VERSION ""

NS_ :

BS_:

BU_: Bat1 OpticalSensor EMUS_BMS SCIMO_PE TelemetryNode Master SensorF SensorR BrakeF BrakeR PDU HVCU HVTU TestBench MDB1 MDB2 MDB3 MDB4 MDB5 MDB6 Track CLU

BO_ 57 CLU_TX_ActionRequest: 5 CLU
 SG_ CLU_TX_TargetAirGap : 8|32@1+ (1,0) [0|4294967295] "" Vector__XXX
 SG_ CLU_TX_ActionRequest : 0|8@1+ (1,0) [0|255] "" Vector__XXX

BO_ 564 CLU_RX_ActionRequest: 1 SensorF
 SG_ CLU_RX_ActionRequest : 0|8@1+ (1,0) [0|255] ""  SensorF

BO_ 2165346838 BMS44_2_Frame: 8 Vector__XXX
 SG_ BMS44_2_FramePayload : 0|64@1+ (1,0) [0|0] ""  SensorF

BO_ 1792 CLU_RX_StatusLedControll: 1 SensorF
 SG_ CLU_RX_ErrorStatus : 0|1@1+ (1,0) [0|1] ""  CLU

BO_ 592 CLU_TX_LevitationState: 1 CLU
 SG_ CLU_LevitationState : 0|8@1+ (1,0) [0|255] ""  SensorF

BO_ 768 CLU_TX_CoolingState: 1 Vector__XXX
 SG_ CLU_RequiresCooling : 0|1@1+ (1,0) [0|1] ""  SensorF

BO_ 274 MDB3_RX_TargetAirGap: 4 CLU
 SG_ MDB3_TargetAirGap : 0|32@1- (0.0001,0) [-214748.3648|214748.3647] "mm" Vector__XXX

BO_ 295 MDB6_RX_TargetAirGap: 4 CLU
 SG_ MDB6_TargetAirGap : 0|32@1- (0.0001,0) [-214748.3648|214748.3647] "mm" Vector__XXX

BO_ 297 MDB6_TX_Temperature: 4 Vector__XXX
 SG_ MDB6_Temperature : 0|32@1- (0.0001,0) [-214748.3648|214748.3647] "C"  CLU

BO_ 294 MDB6_TX_AirGap: 4 Vector__XXX
 SG_ MDB6_AirGap : 0|32@1- (0.0001,0) [-214748.3648|214748.3647] "mm"  CLU

BO_ 293 MDB6_TX_State: 1 MDB6
 SG_ MDB6_State : 0|8@1+ (1,0) [0|255] ""  CLU

BO_ 292 MDB5_TX_Temperature: 4 Vector__XXX
 SG_ MDB5_Temperature : 0|32@1- (0.0001,0) [-214748.3648|214748.3647] "C"  CLU

BO_ 290 MDB5_RX_TargetAirGap: 4 CLU
 SG_ MDB5_TargetAirGap : 0|32@1- (0.0001,0) [-214748.3648|214748.3647] "mm" Vector__XXX

BO_ 289 MDB5_TX_AirGap: 4 Vector__XXX
 SG_ MDB5_AirGap : 0|32@1- (0.0001,0) [-214748.3648|214748.3647] "mm"  CLU

BO_ 288 MDB5_TX_State: 1 MDB5
 SG_ MDB5_State : 0|8@1+ (1,0) [0|255] ""  CLU

BO_ 281 MDB4_TX_Temperature: 4 Vector__XXX
 SG_ MDB4_Temperature : 0|32@1- (0.0001,0) [-214748.3648|214748.3647] "C"  CLU

BO_ 279 MDB4_RX_TargetAirGap: 4 CLU
 SG_ MDB4_TargetAirGap : 0|32@1- (0.0001,0) [-214748.3648|214748.3647] "C" Vector__XXX

BO_ 278 MDB4_TX_AirGap: 4 Vector__XXX
 SG_ MDB4_AirGap : 0|32@1- (0.0001,0) [-214748.3648|214748.3647] "mm"  CLU

BO_ 277 MDB4_TX_State: 1 MDB4
 SG_ MDB4_State : 0|8@1+ (1,0) [0|255] ""  CLU

BO_ 276 MDB3_TX_Temperature: 4 Vector__XXX
 SG_ MDB3_Temperature : 0|32@1- (0.0001,0) [-214748.3648|214748.3647] "C"  CLU

BO_ 273 MDB3_TX_AirGap: 4 Vector__XXX
 SG_ MDB3_AirGap : 0|32@1- (0.0001,0) [-214748.3648|214748.3647] "mm"  CLU

BO_ 272 MDB3_TX_State: 1 MDB3
 SG_ MDB3_State : 0|8@1+ (1,0) [0|255] ""  CLU

BO_ 265 MDB2_TX_Temperature: 4 Vector__XXX
 SG_ MDB2_Temperature : 0|32@1- (0.0001,0) [-214748.3648|214748.3647] "C"  CLU

BO_ 263 MDB2_RX_TargetAirGap: 4 CLU
 SG_ MDB2_TargetAirGap : 0|32@1- (0.0001,0) [-214748.3648|214748.3647] "mm" Vector__XXX

BO_ 262 MDB2_TX_AirGap: 4 Vector__XXX
 SG_ MDB2_AirGap : 0|32@1- (0.0001,0) [-214748.3648|214748.3647] "mm"  CLU

BO_ 261 MDB2_TX_State: 1 MDB2
 SG_ MDB2_State : 0|8@1+ (1,0) [0|255] ""  CLU

BO_ 258 MDB1_RX_TargetAirGap: 4 CLU
 SG_ MDB1_TargetAirGap : 0|32@1- (0.0001,0) [0|0] "mm" Vector__XXX

BO_ 260 MDB1_TX_Temperature: 4 MDB3
 SG_ MDB1_Temperature : 0|32@1- (0.0001,0) [-214748.3648|214748.3647] "C"  CLU,SensorF

BO_ 257 MDB1_TX_AirGap: 4 MDB3
 SG_ MDB1_AirGap : 0|32@1- (0.0001,0) [-214748.3648|214748.3647] "mm"  CLU

BO_ 1041 BrakeF_TX_PressureCooling: 2 BrakeF
 SG_ BrakeF_TX_Pressure_Reservoir : 0|12@1+ (0.005,-2) [-2|18.475] "bar"  SensorF

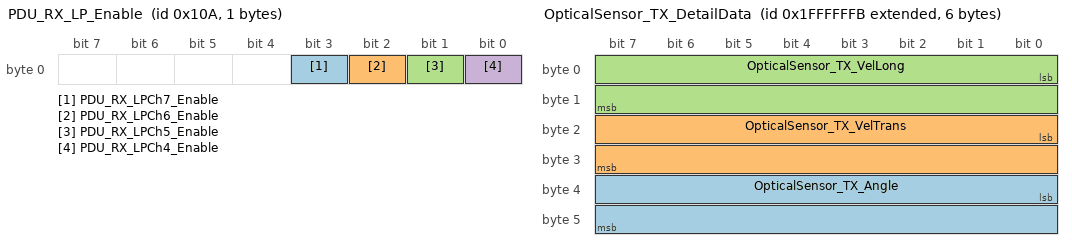
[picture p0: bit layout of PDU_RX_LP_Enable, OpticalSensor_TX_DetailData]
BO_ 266 PDU_RX_LP_Enable: 1 PDU
 SG_ PDU_RX_LPCh7_Enable : 3|1@1+ (1,0) [0|1] ""  PDU,SensorF
 SG_ PDU_RX_LPCh6_Enable : 2|1@1+ (1,0) [0|1] ""  PDU,SensorF
 SG_ PDU_RX_LPCh5_Enable : 1|1@1+ (1,0) [0|1] ""  PDU,SensorF
 SG_ PDU_RX_LPCh4_Enable : 0|1@1+ (1,0) [0|1] ""  PDU,SensorF

BO_ 2148592864 BMS44_1_Frame: 8 Bat1
 SG_ BMS44_1_FramePayload : 0|64@1+ (1,0) [0|0] ""  SensorF

BO_ 1 Track_TX_Respond: 1 Track
 SG_ Track_TX_Response : 0|8@1+ (1,0) [0|255] ""  SensorF

BO_ 0 Track_RX_Controll: 1 SensorF
 SG_ Track_RX_Command : 0|8@1+ (1,0) [0|255] "" Vector__XXX

BO_ 512 TEST_GROUND_STATION_CONTROLL: 1 Vector__XXX
 SG_ TEST_GROUND_STATION_COMMAND : 0|8@1+ (1,0) [0|255] ""  SensorF

BO_ 256 MDB1_TX_State: 1 MDB1
 SG_ MDB1_State : 0|8@1+ (1,0) [0|255] ""  CLU,SensorF

BO_ 450 SensorR_RX_POD1: 8 Vector__XXX

BO_ 2684354555 OpticalSensor_TX_DetailData: 6 OpticalSensor
 SG_ OpticalSensor_TX_Angle : 32|16@1- (0.01,0) [-45|45] "ï¿½" Vector__XXX
 SG_ OpticalSensor_TX_VelTrans : 16|16@1- (0.036,0) [-200|200] "km/h" Vector__XXX
 SG_ OpticalSensor_TX_VelLong : 0|16@1+ (0.036,0) [0|400] "km/h" Vector__XXX

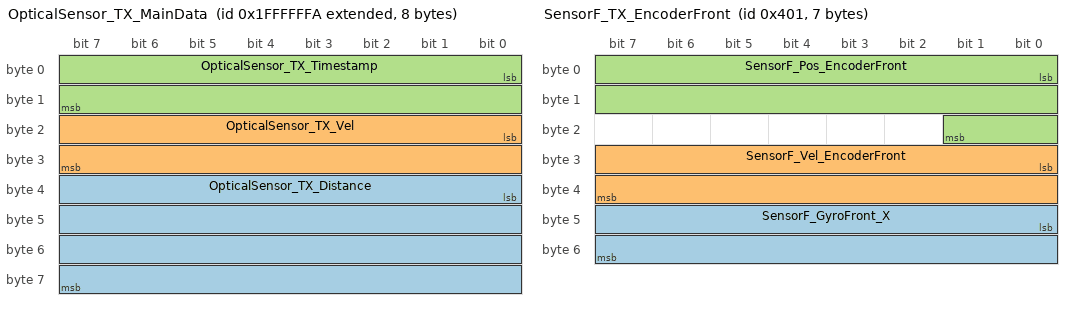
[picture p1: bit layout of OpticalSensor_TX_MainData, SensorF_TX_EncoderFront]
BO_ 2684354554 OpticalSensor_TX_MainData: 8 OpticalSensor
 SG_ OpticalSensor_TX_Distance : 32|32@1+ (0.001,0) [0|4294970] "m"  SensorF,SensorR
 SG_ OpticalSensor_TX_Vel : 16|16@1+ (0.036,0) [0|400] "km/h"  SensorF,SensorR
 SG_ OpticalSensor_TX_Timestamp : 0|16@1+ (1,0) [0|65535] ""  SensorF,SensorR

BO_ 2684354556 OpticalSensor_TX_Status: 8 OpticalSensor
 SG_ OpticalSensor_TX_VddOK : 62|1@1+ (1,0) [0|0] ""  SensorF
 SG_ OpticalSensor_TX_VeeOK : 61|1@1+ (1,0) [0|0] ""  SensorF
 SG_ OpticalSensor_TX_V33OK : 60|1@1+ (1,0) [0|0] ""  SensorF
 SG_ OpticalSensor_TX_V25OK : 59|1@1+ (1,0) [0|0] ""  SensorF
 SG_ OpticalSensor_TX_LEDStatus : 57|2@1+ (1,0) [0|0] ""  SensorF
 SG_ OpticalSensor_TX_LED_Cal : 56|1@1+ (1,0) [0|0] ""  SensorF
 SG_ OpticalSensor_TX_PowerOK : 55|1@1+ (1,0) [0|0] ""  SensorF
 SG_ OpticalSensor_TX_CurrentOK : 54|1@1+ (1,0) [0|0] ""  SensorF
 SG_ OpticalSensor_TX_CurrentLowHigh : 53|1@1+ (1,0) [0|0] ""  SensorF
 SG_ OpticalSensor_TX_OpticOK : 52|1@1+ (1,0) [0|0] ""  SensorF
 SG_ OpticalSensor_TX_TempOK : 51|1@1+ (1,0) [0|0] ""  SensorF
 SG_ OpticalSensor_TX_SensorOK : 50|1@1+ (1,0) [0|0] ""  SensorF
 SG_ OpticalSensor_TX_SelfTest : 49|1@1+ (1,0) [0|0] ""  SensorF
 SG_ OpticalSensor_TX_STST : 48|1@1+ (1,0) [0|0] ""  SensorF
 SG_ OpticalSensor_TX_LEDCurrent : 40|8@1+ (0.01,0) [0|2.55] "A"  SensorF
 SG_ OpticalSensor_TX_Temp : 32|8@1- (1,0) [-128|127] "ï¿½C"  SensorF
 SG_ OpticalSensor_TX_SensorNo : 24|8@1+ (1,0) [0|0] ""  SensorF
 SG_ OpticalSensor_TX_SerialNo : 0|24@1+ (1,0) [0|0] ""  SensorF

BO_ 2 CANzero_NMT: 4 Master
 SG_ CANzero_NMT_Node : 16|16@1+ (1,0) [0|63] ""  SensorF,SensorR,BrakeF,BrakeR,PDU,HVCU,HVTU,TelemetryNode,MDB1,MDB2,MDB3,MDB4,MDB5,MDB6,Track,CLU
 SG_ CANzero_NMT_State : 0|16@1+ (1,0) [0|0] ""  SensorF,SensorR,BrakeF,BrakeR,PDU,HVCU,HVTU,TelemetryNode,MDB1,MDB2,MDB3,MDB4,MDB5,MDB6,Track,CLU

BO_ 122 CANzero_Sync: 0 Master

BO_ 123 CANzero_Timestamp: 0 Master

BO_ 129 SensorF_EMCY: 4 SensorF
 SG_ SensorF_E14_fiducialHighOffset : 26|1@1+ (1,0) [0|0] ""  Master,TelemetryNode
 SG_ SensorF_E13_encoderSpeedError : 25|1@1+ (1,0) [0|0] ""  Master,TelemetryNode
 SG_ SensorF_E12_encoderError : 24|1@1+ (1,0) [0|0] ""  Master,TelemetryNode
 SG_ SensorF_E10_TelemEmergency : 22|1@1+ (1,0) [0|0] ""  Master,TelemetryNode
 SG_ SensorF_E9_SWError : 21|1@1+ (1,0) [0|0] ""  Master,TelemetryNode
 SG_ SensorF_E8_NodeErrorFlag : 20|1@1+ (1,0) [0|0] ""  Master,TelemetryNode
 SG_ SensorF_E7_TelemetryTimeout : 19|1@1+ (1,0) [0|0] ""  Master,TelemetryNode
 SG_ SensorF_E6_SensorRTimeout : 18|1@1+ (1,0) [0|0] ""  Master,TelemetryNode
 SG_ SensorF_E5_HVCUTimeout : 17|1@1+ (1,0) [0|0] ""  Master,TelemetryNode
 SG_ SensorF_E4_PDUTimeout : 16|1@1+ (1,0) [0|0] ""  Master,TelemetryNode
 SG_ SensorF_E3_BrakeRTimeout : 15|1@1+ (1,0) [0|0] ""  Master,TelemetryNode
 SG_ SensorF_E2_BrakeFTimeout : 14|1@1+ (1,0) [0|0] ""  Master,TelemetryNode
 SG_ SensorF_E1_StateMTransitionE : 13|1@1+ (1,0) [0|0] ""  Master,TelemetryNode
 SG_ SensorF_E0_OtherError : 12|1@1+ (1,0) [0|0] ""  Master,TelemetryNode
 SG_ SensorF_W2_encoderOORWarning : 2|1@1+ (1,0) [0|0] ""  Master,TelemetryNode
 SG_ SensorF_W1_StateMTransitionW : 1|1@1+ (1,0) [0|0] ""  Master,TelemetryNode
 SG_ SensorF_W0_OtherWarning : 0|1@1+ (1,0) [0|0] ""  Master,TelemetryNode

BO_ 385 SensorF_TX_StatePod: 1 SensorF
 SG_ SensorF_TX_PodState : 0|8@1+ (1,0) [0|0] ""  CLU,Track,BrakeF,PDU

BO_ 449 SensorF_RX_PDO1: 0 Vector__XXX

BO_ 513 SensorF_TX_FSMTransitions: 4 SensorF
 SG_ SensorF_TX_PreopHVCUT : 24|1@1+ (1,0) [0|0] "" Vector__XXX
 SG_ SensorF_TX_PreopPDUT : 16|1@1+ (1,0) [0|0] "" Vector__XXX
 SG_ SensorF_TX_PreopBrakeRT : 15|1@1+ (1,0) [0|0] "" Vector__XXX
 SG_ SensorF_TX_PreopBrakeFT : 14|1@1+ (1,0) [0|0] "" Vector__XXX
 SG_ SensorF_TX_PreopSensorRT : 13|1@1+ (1,0) [0|0] "" Vector__XXX
 SG_ SensorF_TX_EnableSensorRT : 12|1@1+ (1,0) [0|0] "" Vector__XXX
 SG_ SensorF_TX_EnablePDUT : 11|1@1+ (1,0) [0|0] "" Vector__XXX
 SG_ SensorF_TX_EnableHVCUT : 10|1@1+ (1,0) [0|0] "" Vector__XXX
 SG_ SensorF_TX_EnableBrakeRT : 9|1@1+ (1,0) [0|0] "" Vector__XXX
 SG_ SensorF_TX_EnableBrakeFT : 8|1@1+ (1,0) [0|0] "" Vector__XXX
 SG_ SensorF_TX_SetHVTransition : 7|1@1+ (1,0) [0|0] "" Vector__XXX
 SG_ SensorF_TX_PreopTransition : 6|1@1+ (1,0) [0|0] "" Vector__XXX
 SG_ SensorF_TX_LaunchStartTransition : 5|1@1+ (1,0) [0|0] "" Vector__XXX
 SG_ SensorF_TX_LaunchSetupTransition : 4|1@1+ (1,0) [0|0] "" Vector__XXX
 SG_ SensorF_TX_HWEnableTransition : 3|1@1+ (1,0) [0|0] "" Vector__XXX
 SG_ SensorF_TX_ErrorResetTransition : 2|1@1+ (1,0) [0|0] "" Vector__XXX
 SG_ SensorF_TX_EnableTransition : 1|1@1+ (1,0) [0|0] "" Vector__XXX
 SG_ SensorF_TX_BrakesTransition : 0|1@1+ (1,0) [0|0] "" Vector__XXX

BO_ 577 SensorF_RX_PDO2: 0 Vector__XXX

BO_ 641 SensorF_TX_PDO3: 0 SensorF

BO_ 705 SensorF_RX_PDO3: 0 Vector__XXX

BO_ 769 SensorF_TX_PDO4: 0 SensorF

BO_ 833 SensorF_RX_PDO4: 0 Vector__XXX

BO_ 897 SensorF_TX_PDO5: 0 SensorF

BO_ 961 SensorF_TX_PDO6: 0 SensorF

BO_ 1025 SensorF_TX_EncoderFront: 7 SensorF
 SG_ SensorF_GyroFront_X : 40|16@1- (0.017,0) [-557.056|557.039] "Â°/s"  SensorR
 SG_ SensorF_Vel_EncoderFront : 24|16@1- (0.002,0) [-65.536|65.534] "m/s"  SensorR
 SG_ SensorF_Pos_EncoderFront : 0|18@1- (0.005,0) [-655.36|655.355] "m"  SensorR

BO_ 1089 SensorF_TX_BMS: 2 SensorF
 SG_ SensorF_TX_BatteryTemp : 0|12@1+ (0.05,-30) [-30|174.75] "C"  PDU

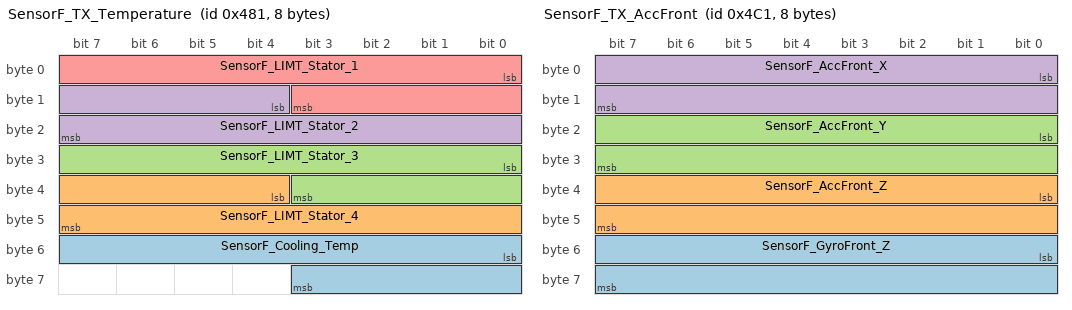
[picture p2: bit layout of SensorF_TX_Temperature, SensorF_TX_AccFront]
BO_ 1153 SensorF_TX_Temperature: 8 SensorF
 SG_ SensorF_Cooling_Temp : 48|12@1+ (0.05,-30) [-30|174.75] "C"  PDU
 SG_ SensorF_LIMT_Stator_4 : 36|12@1+ (0.075,-20) [-20|287.125] "ï¿½C" Vector__XXX
 SG_ SensorF_LIMT_Stator_3 : 24|12@1+ (0.075,-20) [-20|287.125] "ï¿½C" Vector__XXX
 SG_ SensorF_LIMT_Stator_2 : 12|12@1+ (0.075,-20) [-20|287.125] "ï¿½C" Vector__XXX
 SG_ SensorF_LIMT_Stator_1 : 0|12@1+ (0.075,-20) [-20|287.125] "ï¿½C" Vector__XXX

BO_ 1217 SensorF_TX_AccFront: 8 SensorF
 SG_ SensorF_GyroFront_Z : 48|16@1- (0.017,0) [-557.056|557.039] "Â°/s"  SensorR
 SG_ SensorF_AccFront_Z : 32|16@1- (0.00125,0) [-40.96|40.95875] "m/s^2"  SensorR
 SG_ SensorF_AccFront_Y : 16|16@1- (0.00125,0) [-40.96|40.95875] "m/s^2"  SensorR
 SG_ SensorF_AccFront_X : 0|16@1- (0.00125,0) [-40.96|40.95875] "m/s^2"  SensorR

BO_ 1281 SensorF_TX_PDO11: 0 SensorF

BO_ 1345 SensorF_TX_PDO12: 0 SensorF

BO_ 1409 SensorF_SDO_Resp: 8 SensorF
 SG_ SensorF_OD_TitanCell12Voltage m785 : 16|16@1+ (0.001,0) [0|65.535] "V"  TelemetryNode
 SG_ SensorF_OD_TitanCell11Voltage m784 : 16|16@1+ (0.001,0) [0|65.535] "V"  TelemetryNode
 SG_ SensorF_OD_TitanCell10Voltage m783 : 16|16@1+ (0.001,0) [0|65.535] "V"  TelemetryNode
 SG_ SensorF_OD_TitanCell9Voltage m782 : 16|16@1+ (0.001,0) [0|65.535] "V"  TelemetryNode
 SG_ SensorF_OD_TitanCell8Voltage m781 : 16|16@1+ (0.001,0) [0|65.535] "V"  TelemetryNode
 SG_ SensorF_OD_TitanCell7Voltage m780 : 16|16@1+ (0.001,0) [0|65.535] "V"  TelemetryNode
 SG_ SensorF_OD_TitanCell6Voltage m779 : 16|16@1+ (0.001,0) [0|65.535] "V"  TelemetryNode
 SG_ SensorF_OD_TitanCell5Voltage m778 : 16|16@1+ (0.001,0) [0|65.535] "V"  TelemetryNode
 SG_ SensorF_OD_TitanCell4Voltage m777 : 16|16@1+ (0.001,0) [0|65.535] "V"  TelemetryNode
 SG_ SensorF_OD_TitanCell3Voltage m776 : 16|16@1+ (0.001,0) [0|65.535] "V"  TelemetryNode
 SG_ SensorF_OD_TitanCell2Voltage m775 : 16|16@1+ (0.001,0) [0|65.535] "V"  TelemetryNode
 SG_ SensorF_OD_TitanCell1Voltage m774 : 16|16@1+ (0.001,0) [0|65.535] "V"  TelemetryNode
 SG_ SensorF_OD_TitanHealthStatus m773 : 16|16@1+ (1,0) [0|65535] "%"  TelemetryNode
 SG_ SensorF_OD_TitanLifeCycle m772 : 16|16@1+ (1,0) [0|65535] ""  TelemetryNode
 SG_ SensorF_OD_TitanRemainingCapacit m771 : 16|16@1+ (1,0) [0|65535] "%"  TelemetryNode
 SG_ SensorF_OD_TitanCurrent m770 : 16|16@1+ (0.01,-100) [-100|555.35] "A"  TelemetryNode
 SG_ SensorF_OD_TitanVoltage m769 : 16|16@1+ (0.001,0) [0|65.535] "V"  TelemetryNode
 SG_ SensorF_OD_TitanTemperature m768 : 16|16@1+ (0.01,0) [0|655.35] "C°"  TelemetryNode
 SG_ SensorF_OD_HyperionCell12Voltage m529 : 16|16@1+ (0.001,0) [0|65.535] "V"  TelemetryNode
 SG_ SensorF_OD_HyperionCell11Voltage m528 : 16|16@1+ (0.001,0) [0|65.535] "V"  TelemetryNode
 SG_ SensorF_OD_HyperionCell10Voltage m527 : 16|16@1+ (0.001,0) [0|65.535] "V"  TelemetryNode
 SG_ SensorF_OD_HyperionCell9Voltage m526 : 16|16@1+ (0.001,0) [0|65.535] "V"  TelemetryNode
 SG_ SensorF_OD_HyperionCell8Voltage m525 : 16|16@1+ (0.001,0) [0|65.535] "V"  TelemetryNode
 SG_ SensorF_OD_HyperionCell7Voltage m524 : 16|16@1+ (0.001,0) [0|65.535] "V"  TelemetryNode
 SG_ SensorF_OD_HyperionCell6Voltage m523 : 16|16@1+ (0.001,0) [0|65.535] "V"  TelemetryNode
 SG_ SensorF_OD_HyperionCell5Voltage m522 : 16|16@1+ (0.001,0) [0|65.535] "V"  TelemetryNode
 SG_ SensorF_OD_HyperionCell4Voltage m521 : 16|16@1+ (0.001,0) [0|65.535] "V"  TelemetryNode
 SG_ SensorF_OD_HyperionCell3Voltage m520 : 16|16@1+ (0.001,0) [0|65.535] "V"  TelemetryNode
 SG_ SensorF_OD_HyperionCell2Voltage m519 : 16|16@1+ (0.001,0) [0|65.535] "V"  TelemetryNode
 SG_ SensorF_OD_HyperionCell1Voltage m518 : 16|16@1+ (0.01,0) [0|655.35] "V"  TelemetryNode
 SG_ SensorF_OD_HyperionHealthStatus m517 : 16|16@1+ (1,0) [0|65535] "%"  TelemetryNode
 SG_ SensorF_OD_HyperionLifeCycle m516 : 16|16@1+ (1,0) [0|65535] ""  TelemetryNode
 SG_ SensorF_OD_HyperionRemainingCapa m515 : 16|16@1+ (0.01,0) [0|655.35] "%"  TelemetryNode
 SG_ SensorF_OD_HyperionCurrent m514 : 16|16@1+ (0.01,-100) [-100|555.35] "A"  TelemetryNode
 SG_ SensorF_OD_HyperionVoltage m513 : 16|16@1+ (0.001,0) [0|65.535] "V"  TelemetryNode
 SG_ SensorF_OD_HyperionTemperature m512 : 16|16@1+ (0.01,0) [0|655.35] "C°"  TelemetryNode
 SG_ SensorF_OD_SetReset m2320 : 16|8@1+ (1,0) [0|255] ""  TelemetryNode
 SG_ SensorF_OD_Velocity m3329 : 16|16@1+ (0.01,-100) [-100|555.35] ""  TelemetryNode
 SG_ SensorF_OD_Position m3328 : 16|16@1+ (0.01,-100) [-100|555.35] ""  TelemetryNode
 SG_ SensorF_OD_StripeCount m3072 : 16|16@1+ (1,0) [0|65535] ""  TelemetryNode
 SG_ SensorF_OD_MdbState m2832 : 16|8@1+ (1,0) [0|255] ""  TelemetryNode
 SG_ SensorF_OD_Magnet_6_Temperature m2824 : 16|16@1+ (0.01,-100) [-100|555.35] ""  TelemetryNode
 SG_ SensorF_OD_Magnet_5_Temperature m2823 : 16|16@1+ (0.01,-100) [-100|555.35] ""  TelemetryNode
 SG_ SensorF_OD_Magnet_4_Temperature m2822 : 16|16@1+ (0.01,-100) [-100|555.35] ""  TelemetryNode
 SG_ SensorF_OD_Magnet_3_Temperature m2821 : 16|16@1+ (0.01,-100) [-100|555.35] ""  TelemetryNode
 SG_ SensorF_OD_Magnet_2_Temperature m2820 : 16|16@1+ (0.01,-100) [-100|555.35] ""  TelemetryNode
 SG_ SensorF_OD_Magnet_1_Temperature m2818 : 16|16@1+ (0.01,-100) [-100|555.35] ""  TelemetryNode
 SG_ SensorF_OD_ReservoirTemperature m2817 : 16|16@1+ (0.01,-100) [-100|555.35] ""  TelemetryNode
 SG_ SensorF_OD_CoolingPressure m2816 : 16|16@1+ (0.01,-100) [-100|555.35] ""  TelemetryNode
 SG_ SensorF_OD_IMU_GyroZ m2611 : 16|16@1+ (0.01,-100) [-100|555.35] ""  TelemetryNode
 SG_ SensorF_OD_IMU_GyroY m2610 : 16|16@1+ (0.01,-100) [-100|555.35] ""  TelemetryNode
 SG_ SensorF_OD_IMU_GyroX m2609 : 16|16@1+ (0.01,-100) [-100|555.35] ""  TelemetryNode
 SG_ SensorF_OD_IMU_AccelZ m2608 : 16|16@1+ (0.01,-100) [-100|555.35] ""  TelemetryNode
 SG_ SensorF_OD_IMU_AccelY m2601 : 16|16@1+ (0.01,-100) [-100|555.35] ""  TelemetryNode
 SG_ SensorF_OD_IMU_AccelX m2600 : 16|16@1+ (0.01,-100) [-100|555.35] ""  TelemetryNode
 SG_ SensorF_OD_IMU3_Temperature m2599 : 16|16@1+ (0.01,-100) [-100|555.35] ""  TelemetryNode
 SG_ SensorF_OD_IMU2_Temperature m2598 : 16|16@1+ (0.01,-100) [-100|555.35] ""  TelemetryNode
 SG_ SensorF_OD_IMU1_Temperature m2597 : 16|16@1+ (0.01,-100) [-100|555.35] ""  TelemetryNode
 SG_ SensorF_OD_IMU_number m2592 : 16|8@1+ (1,0) [0|255] ""  TelemetryNode
 SG_ SensorF_OD_EncoderResetPosition m2309 : 16|8@1+ (1,0) [0|255] ""  TelemetryNode
 SG_ SensorF_OD_EncoderWheelDiameter m2308 : 16|16@1+ (0.005,0) [1|300] "mm"  TelemetryNode
 SG_ SensorF_OD_HVBatteryMode m2307 : 16|8@1+ (1,0) [0|255] ""  TelemetryNode
 SG_ SensorF_OD_StateMachineActivate m2306 : 16|8@1+ (1,0) [0|255] ""  TelemetryNode
 SG_ SensorF_OD_StateMachineInterval m2305 : 16|8@1+ (1,0) [5|100] "ms"  TelemetryNode
 SG_ SensorF_OD_TelemetryCommands m2304 : 16|8@1+ (1,0) [0|255] ""  TelemetryNode
 SG_ SensorF_OD_samplingInterval m2048 : 16|16@1+ (0.01,0) [0.01|100] "ms"  TelemetryNode
 SG_ SensorF_OD_CAN2_DelayedTxMessage m1129 : 16|24@1+ (1,0) [0|16777215] ""  TelemetryNode
 SG_ SensorF_OD_CAN2_ErrorStatus m1128 : 16|8@1+ (1,0) [0|255] ""  TelemetryNode
 SG_ SensorF_OD_CAN2_DiscardedTxMessa m1127 : 16|24@1+ (1,0) [0|16777215] ""  TelemetryNode
 SG_ SensorF_OD_CAN2_Status m1126 : 16|8@1+ (1,0) [0|255] ""  TelemetryNode
 SG_ SensorF_OD_CAN2_Baudrate m1124 : 16|16@1+ (1,0) [125|1000] "kbps"  TelemetryNode
 SG_ SensorF_OD_CAN2_autoErrorReset m1123 : 16|8@1+ (1,0) [0|255] ""  TelemetryNode
 SG_ SensorF_OD_CAN2_lastErrorCode m1122 : 16|32@1+ (1,0) [0|4294967295] ""  TelemetryNode
 SG_ SensorF_OD_CAN2_RxErrCnt m1121 : 16|8@1+ (1,0) [0|255] ""  TelemetryNode
 SG_ SensorF_OD_CAN2_TxErrCnt m1120 : 16|8@1+ (1,0) [0|255] ""  TelemetryNode
 SG_ SensorF_OD_CAN1_DelayedTxMessage m1113 : 16|24@1+ (1,0) [0|16777215] ""  TelemetryNode
 SG_ SensorF_OD_CAN1_ErrorStatus m1112 : 16|8@1+ (1,0) [0|255] ""  TelemetryNode
 SG_ SensorF_OD_CAN1_DiscardedTxMessa m1111 : 16|24@1+ (1,0) [0|16777215] ""  TelemetryNode
 SG_ SensorF_OD_CAN1_Status m1110 : 16|8@1+ (1,0) [0|255] ""  TelemetryNode
 SG_ SensorF_OD_CAN1_Baudrate m1108 : 16|16@1+ (1,0) [125|1000] "kbps"  TelemetryNode
 SG_ SensorF_OD_CAN1_autoErrorReset m1107 : 16|8@1+ (1,0) [0|255] ""  TelemetryNode
 SG_ SensorF_OD_CAN1_lastErrorCode m1106 : 16|32@1+ (1,0) [0|4294967295] ""  TelemetryNode
 SG_ SensorF_OD_CAN1_RxErrCnt m1105 : 16|8@1+ (1,0) [0|255] ""  TelemetryNode
 SG_ SensorF_OD_CAN1_TxErrCnt m1104 : 16|8@1+ (1,0) [0|255] ""  TelemetryNode
 SG_ SensorF_OD_BuildTime m1073 : 16|24@1+ (1,0) [0|16777215] ""  TelemetryNode
 SG_ SensorF_OD_BuildDate m1072 : 16|32@1+ (1,0) [0|4294967295] ""  TelemetryNode
 SG_ SensorF_OD_ChipUID2 m1057 : 16|48@1+ (1,0) [0|281474976710655] ""  TelemetryNode
 SG_ SensorF_OD_ChipUID1 m1056 : 16|48@1+ (1,0) [0|281474976710655] ""  TelemetryNode
 SG_ SensorF_OD_SdcOut m1046 : 16|8@1+ (1,0) [0|255] ""  TelemetryNode
 SG_ SensorF_OD_SdcIn m1045 : 16|8@1+ (1,0) [0|255] ""  TelemetryNode
 SG_ SensorF_OD_runtime m1044 : 16|24@1+ (1,0) [0|16777215] "ms"  TelemetryNode
 SG_ SensorF_OD_InputVoltage m1043 : 16|16@1+ (0.001,0) [0|65.535] "V"  TelemetryNode
 SG_ SensorF_OD_BoardTemp m1042 : 16|16@1+ (0.01,-30) [-30|625.35] "°C"  TelemetryNode
 SG_ SensorF_OD_MemFree m1041 : 16|16@1+ (4,0) [0|262140] "bytes"  TelemetryNode
 SG_ SensorF_OD_CpuUsage m1040 : 16|8@1+ (0.5,0) [0|100] "%"  TelemetryNode
 SG_ SensorF_OD_OdEntrySendInterval m33 : 16|16@1+ (1,0) [0|65535] "ms"  TelemetryNode
 SG_ SensorF_OD_SendOdOnBootup m32 : 16|8@1+ (1,0) [0|255] ""  TelemetryNode
 SG_ SensorF_OD_HeartbeatInterval m16 : 16|16@1+ (1,0) [0|65535] "ms"  TelemetryNode
 SG_ SensorF_OD_DbcVersion m5 : 16|16@1+ (1,0) [0|65535] ""  TelemetryNode
 SG_ SensorF_OD_StackVersion m4 : 16|16@1+ (1,0) [0|65535] ""  TelemetryNode
 SG_ SensorF_OD_ProtocolVersion m3 : 16|16@1+ (1,0) [0|65535] ""  TelemetryNode
 SG_ SensorF_OD_NodeStatus m2 : 16|8@1+ (1,0) [0|255] ""  TelemetryNode
 SG_ SensorF_OD_NodeID m1 : 16|8@1+ (1,0) [0|255] ""  TelemetryNode
 SG_ SensorF_SDO_RespCode : 12|4@1+ (1,0) [0|0] ""  TelemetryNode
 SG_ SensorF_SDO_ID M : 0|12@1+ (1,0) [0|4095] ""  TelemetryNode

BO_ 1473 SensorF_SDO_Req_Up: 8 TelemetryNode
 SG_ SensorF_OD_TitanCell12Voltage m785 : 16|16@1+ (0.001,0) [0|65.535] "V"  SensorF
 SG_ SensorF_OD_TitanCell11Voltage m784 : 16|16@1+ (0.001,0) [0|65.535] "V"  SensorF
 SG_ SensorF_OD_TitanCell10Voltage m783 : 16|16@1+ (0.001,0) [0|65.535] "V"  SensorF
 SG_ SensorF_OD_TitanCell9Voltage m782 : 16|16@1+ (0.001,0) [0|65.535] "V"  SensorF
 SG_ SensorF_OD_TitanCell8Voltage m781 : 16|16@1+ (0.001,0) [0|65.535] "V"  SensorF
 SG_ SensorF_OD_TitanCell7Voltage m780 : 16|16@1+ (0.001,0) [0|65.535] "V"  SensorF
 SG_ SensorF_OD_TitanCell6Voltage m779 : 16|16@1+ (0.001,0) [0|65.535] "V"  SensorF
 SG_ SensorF_OD_TitanCell5Voltage m778 : 16|16@1+ (0.001,0) [0|65.535] "V"  SensorF
 SG_ SensorF_OD_TitanCell4Voltage m777 : 16|16@1+ (0.001,0) [0|65.535] "V"  SensorF
 SG_ SensorF_OD_TitanCell3Voltage m776 : 16|16@1+ (0.001,0) [0|65.535] "V"  SensorF
 SG_ SensorF_OD_TitanCell2Voltage m775 : 16|16@1+ (0.001,0) [0|65.535] "V"  SensorF
 SG_ SensorF_OD_TitanCell1Voltage m774 : 16|16@1+ (0.001,0) [0|65.535] "V"  SensorF
 SG_ SensorF_OD_TitanHealthStatus m773 : 16|16@1+ (1,0) [0|65535] "%"  SensorF
 SG_ SensorF_OD_TitanLifeCycle m772 : 16|16@1+ (1,0) [0|65535] ""  SensorF
 SG_ SensorF_OD_TitanRemainingCa_0000 m771 : 16|16@1+ (1,0) [0|65535] "%"  SensorF
 SG_ SensorF_OD_TitanCurrent m770 : 16|16@1+ (0.01,-100) [-100|555.35] "A"  SensorF
 SG_ SensorF_OD_TitanVoltage m769 : 16|16@1+ (0.001,0) [0|65.535] "V"  SensorF
 SG_ SensorF_OD_TitanTemperature m768 : 16|16@1+ (0.01,0) [0|655.35] "C°"  SensorF
 SG_ SensorF_OD_HyperionCell12Voltage m529 : 16|16@1+ (0.001,0) [0|65.535] "V"  SensorF
 SG_ SensorF_OD_HyperionCell11Voltage m528 : 16|16@1+ (0.001,0) [0|65.535] "V"  SensorF
 SG_ SensorF_OD_HyperionCell10Voltage m527 : 16|16@1+ (0.001,0) [0|65.535] "V"  SensorF
 SG_ SensorF_OD_HyperionCell9Voltage m526 : 16|16@1+ (0.001,0) [0|65.535] "V"  SensorF
 SG_ SensorF_OD_HyperionCell8Voltage m525 : 16|16@1+ (0.001,0) [0|65.535] "V"  SensorF
 SG_ SensorF_OD_HyperionCell7Voltage m524 : 16|16@1+ (0.001,0) [0|65.535] "V"  SensorF
 SG_ SensorF_OD_HyperionCell6Voltage m523 : 16|16@1+ (0.001,0) [0|65.535] "V"  SensorF
 SG_ SensorF_OD_HyperionCell5Voltage m522 : 16|16@1+ (0.001,0) [0|65.535] "V"  SensorF
 SG_ SensorF_OD_HyperionCell4Voltage m521 : 16|16@1+ (0.001,0) [0|65.535] "V"  SensorF
 SG_ SensorF_OD_HyperionCell3Voltage m520 : 16|16@1+ (0.001,0) [0|65.535] "V"  SensorF
 SG_ SensorF_OD_HyperionCell2Voltage m519 : 16|16@1+ (0.001,0) [0|65.535] "V"  SensorF
 SG_ SensorF_OD_HyperionCell1Voltage m518 : 16|16@1+ (0.01,0) [0|655.35] "V"  SensorF
 SG_ SensorF_OD_HyperionHealthStatus m517 : 16|16@1+ (1,0) [0|65535] "%"  SensorF
 SG_ SensorF_OD_HyperionLifeCycle m516 : 16|16@1+ (1,0) [0|65535] ""  SensorF
 SG_ SensorF_OD_HyperionRemainin_0000 m515 : 16|16@1+ (0.01,0) [0|655.35] "%"  SensorF
 SG_ SensorF_OD_HyperionCurrent m514 : 16|16@1+ (0.01,-100) [-100|555.35] "A"  SensorF
 SG_ SensorF_OD_HyperionVoltage m513 : 16|16@1+ (0.001,0) [0|65.535] "V"  SensorF
 SG_ SensorF_OD_HyperionTemperature m512 : 16|16@1+ (0.01,0) [0|655.35] "C°"  SensorF
 SG_ SensorF_OD_SetReset m2320 : 16|8@1+ (1,0) [0|255] ""  SensorF
 SG_ SensorF_OD_Velocity m3329 : 16|16@1+ (0.01,-100) [-100|555.35] ""  SensorF
 SG_ SensorF_OD_Position m3328 : 16|16@1+ (0.01,-100) [-100|555.35] ""  SensorF
 SG_ SensorF_OD_StripeCount m3072 : 16|16@1+ (1,0) [0|65535] ""  SensorF
 SG_ SensorF_OD_MdbState m2832 : 16|8@1+ (1,0) [0|255] ""  SensorF
 SG_ SensorF_OD_Magnet_6_Temperature m2824 : 16|16@1+ (0.01,-100) [-100|555.35] ""  SensorF
 SG_ SensorF_OD_Magnet_5_Temperature m2823 : 16|16@1+ (0.01,-100) [-100|555.35] ""  SensorF
 SG_ SensorF_OD_Magnet_4_Temperature m2822 : 16|16@1+ (0.01,-100) [-100|555.35] ""  SensorF
 SG_ SensorF_OD_Magnet_3_Temperature m2821 : 16|16@1+ (0.01,-100) [-100|555.35] ""  SensorF
 SG_ SensorF_OD_Magnet_2_Temperature m2820 : 16|16@1+ (0.01,-100) [-100|555.35] ""  SensorF
 SG_ SensorF_OD_Magnet_1_Temperature m2818 : 16|16@1+ (0.01,-100) [-100|555.35] ""  SensorF
 SG_ SensorF_OD_ReservoirTemperature m2817 : 16|16@1+ (0.01,-100) [-100|555.35] ""  SensorF
 SG_ SensorF_OD_CoolingPressure m2816 : 16|16@1+ (0.01,-100) [-100|555.35] ""  SensorF
 SG_ SensorF_OD_IMU_GyroZ m2611 : 16|16@1+ (0.01,-100) [-100|555.35] ""  SensorF
 SG_ SensorF_OD_IMU_GyroY m2610 : 16|16@1+ (0.01,-100) [-100|555.35] ""  SensorF
 SG_ SensorF_OD_IMU_GyroX m2609 : 16|16@1+ (0.01,-100) [-100|555.35] ""  SensorF
 SG_ SensorF_OD_IMU_AccelZ m2608 : 16|16@1+ (0.01,-100) [-100|555.35] ""  SensorF
 SG_ SensorF_OD_IMU_AccelY m2601 : 16|16@1+ (0.01,-100) [-100|555.35] ""  SensorF
 SG_ SensorF_OD_IMU_AccelX m2600 : 16|16@1+ (0.01,-100) [-100|555.35] ""  SensorF
 SG_ SensorF_OD_IMU3_Temperature m2599 : 16|16@1+ (0.01,-100) [-100|555.35] ""  SensorF
 SG_ SensorF_OD_IMU2_Temperature m2598 : 16|16@1+ (0.01,-100) [-100|555.35] ""  SensorF
 SG_ SensorF_OD_IMU1_Temperature m2597 : 16|16@1+ (0.01,-100) [-100|555.35] ""  SensorF
 SG_ SensorF_OD_IMU_number m2592 : 16|8@1+ (1,0) [0|255] ""  SensorF
 SG_ SensorF_OD_EncoderResetPosition m2309 : 16|8@1+ (1,0) [0|255] ""  SensorF
 SG_ SensorF_OD_EncoderWheelDiameter m2308 : 16|16@1+ (0.005,0) [1|300] "mm"  SensorF
 SG_ SensorF_OD_HVBatteryMode m2307 : 16|8@1+ (1,0) [0|255] ""  SensorF
 SG_ SensorF_OD_StateMachineActivate m2306 : 16|8@1+ (1,0) [0|255] ""  SensorF
 SG_ SensorF_OD_StateMachineInterval m2305 : 16|8@1+ (1,0) [5|100] "ms"  SensorF
 SG_ SensorF_OD_TelemetryCommands m2304 : 16|8@1+ (1,0) [0|255] ""  SensorF
 SG_ SensorF_OD_samplingInterval m2048 : 16|16@1+ (0.01,0) [0.01|100] "ms"  SensorF
 SG_ SensorF_OD_CAN2_DelayedTxMe_0000 m1129 : 16|24@1+ (1,0) [0|16777215] ""  SensorF
 SG_ SensorF_OD_CAN2_ErrorStatus m1128 : 16|8@1+ (1,0) [0|255] ""  SensorF
 SG_ SensorF_OD_CAN2_DiscardedTx_0000 m1127 : 16|24@1+ (1,0) [0|16777215] ""  SensorF
 SG_ SensorF_OD_CAN2_Status m1126 : 16|8@1+ (1,0) [0|255] ""  SensorF
 SG_ SensorF_OD_CAN2_Baudrate m1124 : 16|16@1+ (1,0) [125|1000] "kbps"  SensorF
 SG_ SensorF_OD_CAN2_autoErrorReset m1123 : 16|8@1+ (1,0) [0|255] ""  SensorF
 SG_ SensorF_OD_CAN2_lastErrorCode m1122 : 16|32@1+ (1,0) [0|4294967295] ""  SensorF
 SG_ SensorF_OD_CAN2_RxErrCnt m1121 : 16|8@1+ (1,0) [0|255] ""  SensorF
 SG_ SensorF_OD_CAN2_TxErrCnt m1120 : 16|8@1+ (1,0) [0|255] ""  SensorF
 SG_ SensorF_OD_CAN1_DelayedTxMe_0000 m1113 : 16|24@1+ (1,0) [0|16777215] ""  SensorF
 SG_ SensorF_OD_CAN1_ErrorStatus m1112 : 16|8@1+ (1,0) [0|255] ""  SensorF
 SG_ SensorF_OD_CAN1_DiscardedTx_0000 m1111 : 16|24@1+ (1,0) [0|16777215] ""  SensorF
 SG_ SensorF_OD_CAN1_Status m1110 : 16|8@1+ (1,0) [0|255] ""  SensorF
 SG_ SensorF_OD_CAN1_Baudrate m1108 : 16|16@1+ (1,0) [125|1000] "kbps"  SensorF
 SG_ SensorF_OD_CAN1_autoErrorReset m1107 : 16|8@1+ (1,0) [0|255] ""  SensorF
 SG_ SensorF_OD_CAN1_lastErrorCode m1106 : 16|32@1+ (1,0) [0|4294967295] ""  SensorF
 SG_ SensorF_OD_CAN1_RxErrCnt m1105 : 16|8@1+ (1,0) [0|255] ""  SensorF
 SG_ SensorF_OD_CAN1_TxErrCnt m1104 : 16|8@1+ (1,0) [0|255] ""  SensorF
 SG_ SensorF_OD_BuildTime m1073 : 16|24@1+ (1,0) [0|16777215] ""  SensorF
 SG_ SensorF_OD_BuildDate m1072 : 16|32@1+ (1,0) [0|4294967295] ""  SensorF
 SG_ SensorF_OD_ChipUID2 m1057 : 16|48@1+ (1,0) [0|281474976710655] ""  SensorF
 SG_ SensorF_OD_ChipUID1 m1056 : 16|48@1+ (1,0) [0|281474976710655] ""  SensorF
 SG_ SensorF_OD_SdcOut m1046 : 16|8@1+ (1,0) [0|255] ""  SensorF
 SG_ SensorF_OD_SdcIn m1045 : 16|8@1+ (1,0) [0|255] ""  SensorF
 SG_ SensorF_OD_runtime m1044 : 16|24@1+ (1,0) [0|16777215] "ms"  SensorF
 SG_ SensorF_OD_InputVoltage m1043 : 16|16@1+ (0.001,0) [0|65.535] "V"  SensorF
 SG_ SensorF_OD_BoardTemp m1042 : 16|16@1+ (0.01,-30) [-30|625.35] "°C"  SensorF
 SG_ SensorF_OD_MemFree m1041 : 16|16@1+ (4,0) [0|262140] "bytes"  SensorF
 SG_ SensorF_OD_CpuUsage m1040 : 16|8@1+ (0.5,0) [0|100] "%"  SensorF
 SG_ SensorF_OD_OdEntrySendInterval m33 : 16|16@1+ (1,0) [0|65535] "ms"  SensorF
 SG_ SensorF_OD_SendOdOnBootup m32 : 16|8@1+ (1,0) [0|255] ""  SensorF
 SG_ SensorF_OD_HeartbeatInterval m16 : 16|16@1+ (1,0) [0|65535] "ms"  SensorF
 SG_ SensorF_OD_DbcVersion m5 : 16|16@1+ (1,0) [0|65535] ""  SensorF
 SG_ SensorF_OD_StackVersion m4 : 16|16@1+ (1,0) [0|65535] ""  SensorF
 SG_ SensorF_OD_ProtocolVersion m3 : 16|16@1+ (1,0) [0|65535] ""  SensorF
 SG_ SensorF_OD_NodeStatus m2 : 16|8@1+ (1,0) [0|255] ""  SensorF
 SG_ SensorF_OD_NodeID m1 : 16|8@1+ (1,0) [0|255] ""  SensorF
 SG_ SensorF_SDO_ID M : 0|12@1+ (1,0) [0|4095] ""  SensorF

BO_ 1537 SensorF_SDO_Req_Down: 2 TelemetryNode
 SG_ SensorF_SDO_ID M : 0|12@1+ (1,0) [0|4095] ""  SensorF

BO_ 1793 SensorF_Heartbeat: 1 SensorF
 SG_ SensorF_NodeState : 0|8@1+ (1,0) [0|0] ""  SensorF,Master,TelemetryNode

BO_ 1857 SensorF_BTL_TX: 8 SensorF

BO_ 1921 SensorF_BTL_RX: 8 TelemetryNode

BO_ 130 SensorR_EMCY: 4 SensorR
 SG_ SensorR_E12_highLIMTemperature : 24|1@1+ (1,0) [0|0] ""  Master,TelemetryNode
 SG_ SensorR_E11_scimoPEerror101overc : 23|1@1+ (1,0) [0|0] ""  Master,TelemetryNode
 SG_ SensorR_E10_scimoPEerror103sumcu : 22|1@1+ (1,0) [0|0] ""  Master,TelemetryNode
 SG_ SensorR_E9_scimoPEerror102overcu : 21|1@1+ (1,0) [0|0] ""  Master,TelemetryNode
 SG_ SensorR_E8_scimoPEerror024motTem : 20|1@1+ (1,0) [0|0] ""  Master,TelemetryNode
 SG_ SensorR_E7_scimoPEerror020uZKmin : 19|1@1+ (1,0) [0|0] ""  Master,TelemetryNode
 SG_ SensorR_E6_scimoPEerror009Pulslo : 18|1@1+ (1,0) [0|0] ""  Master,TelemetryNode
 SG_ SensorR_E5_accEmergencyStop : 17|1@1+ (1,0) [0|0] ""  Master,TelemetryNode
 SG_ SensorR_E4_velEmergencyStop : 16|1@1+ (1,0) [0|0] ""  Master,TelemetryNode
 SG_ SensorR_E3_posEmergencyStop : 15|1@1+ (1,0) [0|0] ""  Master,TelemetryNode
 SG_ SensorR_E2_stripeEmergencyStop : 14|1@1+ (1,0) [0|0] ""  Master,TelemetryNode
 SG_ SensorR_E1_trajectoryError : 13|1@1+ (1,0) [0|0] ""  Master,TelemetryNode
 SG_ SensorR_E0_OtherError : 12|1@1+ (1,0) [0|0] ""  Master,TelemetryNode
 SG_ SensorR_W10_highLIMTemperature : 10|1@1+ (1,0) [0|0] ""  Master,TelemetryNode
 SG_ SensorR_W9_restrictingVelocity : 9|1@1+ (1,0) [0|0] ""  Master,TelemetryNode
 SG_ SensorR_W8_outOfLimModelBoundari : 8|1@1+ (1,0) [0|0] ""  Master,TelemetryNode
 SG_ SensorR_W7_highOscillations : 7|1@1+ (1,0) [0|0] ""  Master,TelemetryNode
 SG_ SensorR_W6_sciMoPEwarning104FETt : 6|1@1+ (1,0) [0|0] ""  Master,TelemetryNode
 SG_ SensorR_W5_sciMoPEwarning069CPUt : 5|1@1+ (1,0) [0|0] ""  Master,TelemetryNode
 SG_ SensorR_W4_stateEstimationAccWar : 4|1@1+ (1,0) [0|0] ""  Master,TelemetryNode
 SG_ SensorR_W3_stateEstimationPosWar : 3|1@1+ (1,0) [0|0] ""  Master,TelemetryNode
 SG_ SensorR_W2_stateEstimationVelWar : 2|1@1+ (1,0) [0|0] ""  Master,TelemetryNode
 SG_ SensorR_W1_stripeWarning : 1|1@1+ (1,0) [0|0] ""  Master,TelemetryNode
 SG_ SensorR_W0_OtherWarning : 0|1@1+ (1,0) [0|0] ""  Master,TelemetryNode

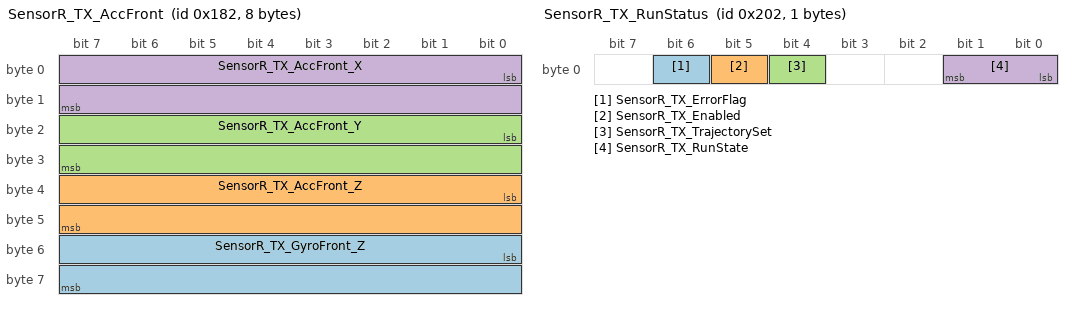
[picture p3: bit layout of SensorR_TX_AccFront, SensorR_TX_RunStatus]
BO_ 386 SensorR_TX_AccFront: 8 SensorR
 SG_ SensorR_TX_GyroFront_Z : 48|16@1- (0.017,0) [-557.056|557.039] "Â°/s" Vector__XXX
 SG_ SensorR_TX_AccFront_Z : 32|16@1- (0.00125,0) [-40.96|40.95875] "m/s^2" Vector__XXX
 SG_ SensorR_TX_AccFront_Y : 16|16@1- (0.00125,0) [-40.96|40.95875] "m/s^2" Vector__XXX
 SG_ SensorR_TX_AccFront_X : 0|16@1- (0.00125,0) [-40.96|40.95875] "m/s^2" Vector__XXX

BO_ 514 SensorR_TX_RunStatus: 1 SensorR
 SG_ SensorR_TX_ErrorFlag : 6|1@1+ (1,0) [0|0] "" Vector__XXX
 SG_ SensorR_TX_Enabled : 5|1@1+ (1,0) [0|0] "" Vector__XXX
 SG_ SensorR_TX_TrajectorySet : 4|1@1+ (1,0) [0|0] "" Vector__XXX
 SG_ SensorR_TX_RunState : 0|2@1+ (1,0) [0|0] ""  PDU

BO_ 578 SensorR_RX_PDO2: 0 Vector__XXX

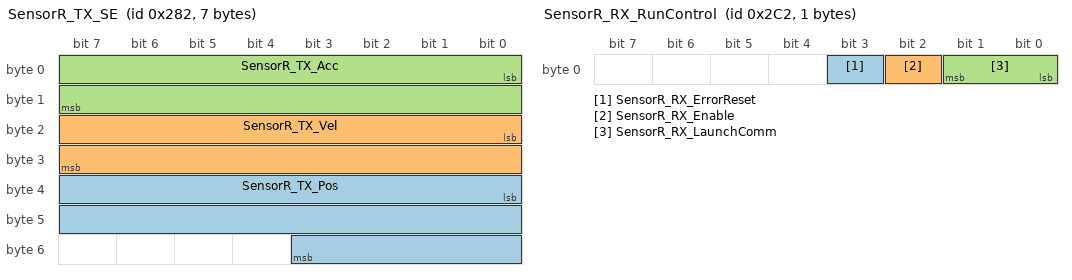
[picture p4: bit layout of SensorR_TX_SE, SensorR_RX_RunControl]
BO_ 642 SensorR_TX_SE: 7 SensorR
 SG_ SensorR_TX_Pos : 32|20@1- (0.001,0) [-524.288|524.287] "m"  PDU,TelemetryNode
 SG_ SensorR_TX_Vel : 16|16@1- (0.002,0) [-65.536|65.534] "m/s"  PDU,TelemetryNode
 SG_ SensorR_TX_Acc : 0|16@1- (0.00125,0) [-40.96|40.95875] "m/s^2"  PDU,TelemetryNode

BO_ 706 SensorR_RX_RunControl: 1 SensorF
 SG_ SensorR_RX_ErrorReset : 3|1@1+ (1,0) [0|0] "" Vector__XXX
 SG_ SensorR_RX_Enable : 2|1@1+ (1,0) [0|0] "" Vector__XXX
 SG_ SensorR_RX_LaunchComm : 0|2@1+ (1,0) [0|0] "" Vector__XXX

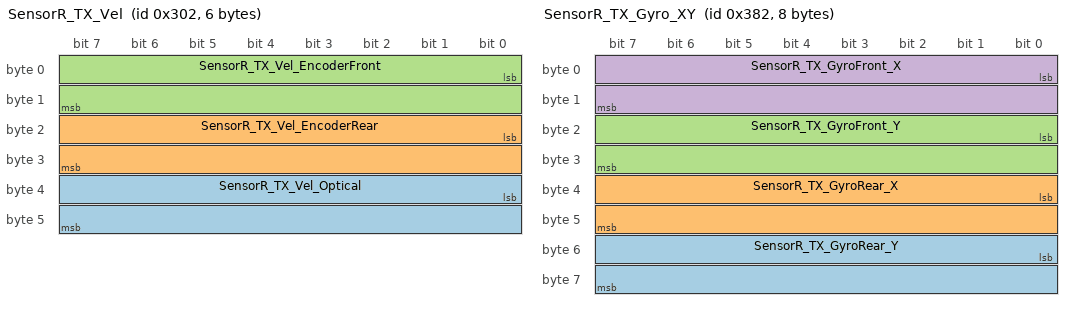
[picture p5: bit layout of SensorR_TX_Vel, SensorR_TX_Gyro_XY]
BO_ 770 SensorR_TX_Vel: 6 SensorR
 SG_ SensorR_TX_Vel_Optical : 32|16@1- (0.002,0) [-65.536|65.534] "m/s" Vector__XXX
 SG_ SensorR_TX_Vel_EncoderRear : 16|16@1- (0.002,0) [-65.536|65.534] "m/s" Vector__XXX
 SG_ SensorR_TX_Vel_EncoderFront : 0|16@1- (0.002,0) [-65.536|65.534] "m/s" Vector__XXX

BO_ 834 SensorR_RX_PDO4: 0 Vector__XXX

BO_ 898 SensorR_TX_Gyro_XY: 8 SensorR
 SG_ SensorR_TX_GyroRear_Y : 48|16@1- (0.017,0) [-557.056|557.039] "Â°/s" Vector__XXX
 SG_ SensorR_TX_GyroRear_X : 32|16@1- (0.017,0) [-557.056|557.039] "Â°/s" Vector__XXX
 SG_ SensorR_TX_GyroFront_Y : 16|16@1- (0.017,0) [-557.056|557.039] "Â°/s" Vector__XXX
 SG_ SensorR_TX_GyroFront_X : 0|16@1- (0.017,0) [-557.056|557.039] "Â°/s" Vector__XXX

BO_ 962 SensorR_TX_TargetValues: 2 SensorR
 SG_ SensorR_TX_TargetVelocity : 0|14@1- (0.01,0) [-81.92|81.91] "m/s" Vector__XXX

BO_ 1026 SensorR_TX_GapHeight: 4 SensorR
 SG_ SensorR_TX_GapHeight_Right : 12|12@1- (0.0125,0) [-25.6|25.5875] "mm" Vector__XXX
 SG_ SensorR_TX_GapHeight_Left : 0|12@1- (0.0125,0) [-25.6|25.5875] "mm" Vector__XXX

BO_ 1090 SensorR_TX_PDO8: 0 SensorR

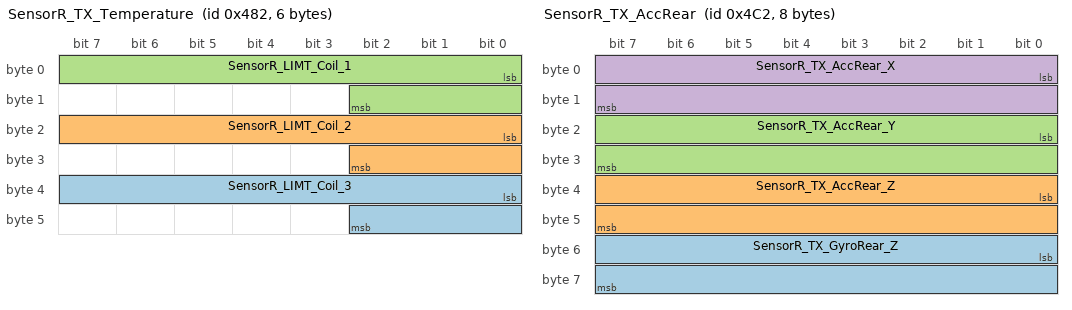
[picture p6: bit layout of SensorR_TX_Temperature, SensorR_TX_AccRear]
BO_ 1154 SensorR_TX_Temperature: 6 SensorR
 SG_ SensorR_LIMT_Coil_3 : 32|11@1+ (0.1,-5) [-5|199.7] "ï¿½C"  PDU
 SG_ SensorR_LIMT_Coil_2 : 16|11@1+ (0.1,-5) [-5|199.7] "ï¿½C"  PDU
 SG_ SensorR_LIMT_Coil_1 : 0|11@1+ (0.1,-5) [-5|199.7] "ï¿½C"  PDU

BO_ 1218 SensorR_TX_AccRear: 8 SensorR
 SG_ SensorR_TX_GyroRear_Z : 48|16@1- (0.017,0) [-557.056|557.039] "Â°/s" Vector__XXX
 SG_ SensorR_TX_AccRear_Z : 32|16@1- (0.00125,0) [-40.96|40.95875] "m/s^2" Vector__XXX
 SG_ SensorR_TX_AccRear_Y : 16|16@1- (0.00125,0) [-40.96|40.95875] "m/s^2" Vector__XXX
 SG_ SensorR_TX_AccRear_X : 0|16@1- (0.00125,0) [-40.96|40.95875] "m/s^2" Vector__XXX

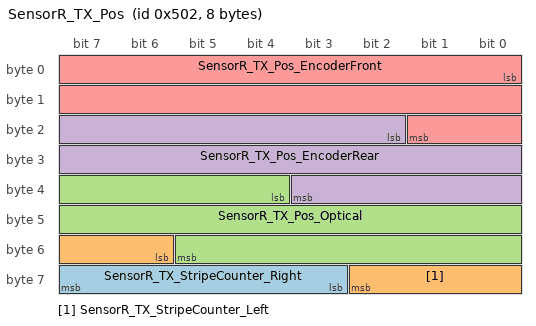
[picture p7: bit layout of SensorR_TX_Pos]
BO_ 1282 SensorR_TX_Pos: 8 SensorR
 SG_ SensorR_TX_StripeCounter_Right : 59|5@1+ (1,0) [0|31] "" Vector__XXX
 SG_ SensorR_TX_StripeCounter_Left : 54|5@1+ (1,0) [0|31] "" Vector__XXX
 SG_ SensorR_TX_Pos_Optical : 36|18@1- (0.005,0) [-655.36|655.355] "m" Vector__XXX
 SG_ SensorR_TX_Pos_EncoderRear : 18|18@1- (0.005,0) [-655.36|655.355] "m" Vector__XXX
 SG_ SensorR_TX_Pos_EncoderFront : 0|18@1- (0.005,0) [-655.36|655.355] "m" Vector__XXX

BO_ 1346 SensorR_TX_PDO12: 0 SensorR

BO_TX_BU_ 260 : MDB3,MDB2,MDB1,MDB6,MDB5,MDB4;
BO_TX_BU_ 257 : MDB3,MDB2,MDB1,MDB6,MDB5,MDB4;

CM_ BU_ OpticalSensor "Kistler SFP-II optical Sensor.";
CM_ BU_ EMUS_BMS "HV BMS ";
CM_ BU_ TelemetryNode "Gateway between Pod and Telemetry
Node-ID 0x22Gateway between Pod and Telemetry
Node-ID 0x22";
CM_ BU_ Master "CANzero NMT Master Node.";
CM_ BU_ SensorF "SensorECU
Node-ID 0x1";
CM_ BU_ SensorR "SensorECUR
Node-ID 0x2";
CM_ BU_ BrakeF "BrakeECU Front
Node-ID 0x11";
CM_ BU_ BrakeR "BrakeECUR
Node-ID 0x12";
CM_ BU_ PDU "PowerD
Node-ID 0x1A";
CM_ BU_ HVCU "HVController
Node-ID 0xA";
CM_ BU_ HVTU "High Voltage CAN Translation Unit between BMS and Pod
Node-ID 0x19";
CM_ BU_ MDB1 "ModularLevitationUnit-1
Node-ID 0x21";
CM_ BU_ MDB2 "ModularLevitationUnit-2
Node-ID 0x23";
CM_ BU_ MDB3 "ModularLevitationUnit-3
Node-ID 0x27";
CM_ BU_ MDB4 "ModularLevitationUnit-4
Node-ID 0x28";
CM_ BU_ MDB5 "ModularLevitationUnit-5
Node-ID 0x29";
CM_ BU_ MDB6 "ModularLevitationUnit-6
Node-ID 0x31";
CM_ BU_ Track "TrackECU
Node-ID 0x32";
CM_ BU_ CLU "central levitation unit
Node-ID 0x14";
CM_ SG_ 274 MDB3_TargetAirGap "as binary IEEE-754
";
CM_ SG_ 295 MDB6_TargetAirGap "as binary IEEE-754
";
CM_ SG_ 297 MDB6_Temperature "as binary IEEE-754";
CM_ SG_ 294 MDB6_AirGap "as binary IEEE-754
";
CM_ SG_ 292 MDB5_Temperature "as binary IEEE-754";
CM_ SG_ 290 MDB5_TargetAirGap "as binary IEEE-754
";
CM_ SG_ 289 MDB5_AirGap "as binary IEEE-754
";
CM_ SG_ 281 MDB4_Temperature "as binary IEEE-754";
CM_ SG_ 279 MDB4_TargetAirGap "as binary IEEE-754
";
CM_ SG_ 278 MDB4_AirGap "as binary IEEE-754
";
CM_ SG_ 276 MDB3_Temperature "as binary IEEE-754";
CM_ SG_ 273 MDB3_AirGap "as binary IEEE-754
";
CM_ SG_ 265 MDB2_Temperature "as binary IEEE-754";
CM_ SG_ 263 MDB2_TargetAirGap "as binary IEEE-754
";
CM_ SG_ 262 MDB2_AirGap "as binary IEEE-754
";
CM_ SG_ 258 MDB1_TargetAirGap "as binary IEEE-754
";
CM_ SG_ 260 MDB1_Temperature "as binary IEEE-754";
CM_ SG_ 257 MDB1_AirGap "as binary IEEE-754
";
CM_ BO_ 2684354555 "longitudinal and transverse velocity, angle between them";
CM_ SG_ 2684354555 OpticalSensor_TX_Angle "Angle between longitudianl and transverse direction.";
CM_ SG_ 2684354555 OpticalSensor_TX_VelTrans "Velocity in transverse direction.";
CM_ SG_ 2684354555 OpticalSensor_TX_VelLong "Velocity in longitudinal direction.";
CM_ BO_ 2684354554 "Timestamp, Veocity, Distance";
CM_ SG_ 2684354554 OpticalSensor_TX_Distance "Traveled distance";
CM_ SG_ 2684354554 OpticalSensor_TX_Vel "Absolute velocity";
CM_ BO_ 2684354556 "Timestamp, Veocity, Distance";
CM_ SG_ 2684354556 OpticalSensor_TX_Temp "Temperature of the sensor";
CM_ SG_ 2684354556 OpticalSensor_TX_SerialNo "Serialnumber of the sensor";
CM_ BO_ 2 "CANzero NMT message sent by NMT master.";
CM_ SG_ 2 CANzero_NMT_Node "CANzero NMT Node-ID of master request.";
CM_ SG_ 2 CANzero_NMT_State "CANzero NMT State Request by master.";
CM_ BO_ 122 "CANzero Sync message. Not used yet, just a placeholder for future versions.";
CM_ BO_ 123 "CANzero Timestamp message. Not used yet, just a placeholder for future versions.";
CM_ BO_ 129 "Emergency message of node SensorF with Node-ID 0x1";
CM_ SG_ 129 SensorF_E14_fiducialHighOffset "Fiducial position estimation derived from kistler estimation";
CM_ SG_ 129 SensorF_E13_encoderSpeedError "Error when the meassured speed is prohibited";
CM_ SG_ 129 SensorF_E12_encoderError "Error when something fails in the Wheel encoder.";
CM_ SG_ 129 SensorF_E10_TelemEmergency "Telemtry sent emergency command";
CM_ SG_ 129 SensorF_E9_SWError "State machine plausibility check failed";
CM_ SG_ 129 SensorF_E8_NodeErrorFlag "A nodes error flag was active";
CM_ SG_ 129 SensorF_E7_TelemetryTimeout "Did not respond in set max time";
CM_ SG_ 129 SensorF_E6_SensorRTimeout "Did not respond in set max time";
CM_ SG_ 129 SensorF_E5_HVCUTimeout "Did not respond in set max time";
CM_ SG_ 129 SensorF_E4_PDUTimeout "Did not respond in set max time";
CM_ SG_ 129 SensorF_E3_BrakeRTimeout "Did not respond in set max time";
CM_ SG_ 129 SensorF_E2_BrakeFTimeout "Did not respond in set max time";
CM_ SG_ 129 SensorF_E1_StateMTransitionE "Something went wrong with a transition";
CM_ SG_ 129 SensorF_E0_OtherError "Other error.";
CM_ SG_ 129 SensorF_W2_encoderOORWarning "the position form the wheelencoder is outside the track limits";
CM_ SG_ 129 SensorF_W1_StateMTransitionW "Some transition is about to time out";
CM_ SG_ 129 SensorF_W0_OtherWarning "Other warning.";
CM_ BO_ 385 "Transmit PDO 1 of node SensorF with Node-ID 0x1";
CM_ SG_ 385 SensorF_TX_PodState "PodState by State Machine.";
CM_ BO_ 449 "Receive PDO 1 of node SensorF with Node-ID 0x1";
CM_ BO_ 513 "Data from Encoder front (PDO10)";
CM_ BO_ 577 "Receive PDO 2 of node SensorF with Node-ID 0x1.";
CM_ BO_ 641 "Transmit PDO 3 of node SensorF with Node-ID 0x1";
CM_ BO_ 705 "Receive PDO 3 of node SensorF with Node-ID 0x1.";
CM_ BO_ 769 "Transmit PDO 4 of node SensorF with Node-ID 0x1";
CM_ BO_ 833 "Receive PDO 4 of node SensorF with Node-ID 0x1.";
CM_ BO_ 897 "Transmit PDO 5 of node SensorF with Node-ID 0x1";
CM_ BO_ 961 "Transmit PDO 6 of node SensorF with Node-ID 0x1";
CM_ BO_ 1025 "Transmit PDO 7 of node SensorF with Node-ID 0x1";
CM_ SG_ 1025 SensorF_GyroFront_X "Slope of front IMU in X direction.";
CM_ SG_ 1025 SensorF_Vel_EncoderFront "Velocity of Wheel Encoder front.";
CM_ SG_ 1025 SensorF_Pos_EncoderFront "Position of Wheel Encoder front.";
CM_ BO_ 1089 "Transmit PDO 8 of node SensorF with Node-ID 0x1";
CM_ BO_ 1153 "Transmit PDO 9 of node SensorF with Node-ID 0x1";
CM_ BO_ 1217 "Transmit Acc_X, Acc_Y, Acc_Z and Gyro_Z of front IMU of node SensorF.";
CM_ SG_ 1217 SensorF_GyroFront_Z "Slope of front IMU in Z direction.";
CM_ SG_ 1217 SensorF_AccFront_Z "Acceleration of front IMU in Z direction.";
CM_ SG_ 1217 SensorF_AccFront_Y "Acceleration of front IMU in Y direction.";
CM_ SG_ 1217 SensorF_AccFront_X "Acceleration of front IMU in X direction.";
CM_ BO_ 1281 "SensorF with Node-ID 0x1 (PDO11).";
CM_ BO_ 1345 "Transmit PDO 12 of node SensorF with Node-ID 0x1.";
CM_ BO_ 1409 "DO NOT CHANGE ANYTHING HERE!
SDO Response of node SensorF with Node-ID 0x1";
CM_ SG_ 1409 SensorF_OD_TitanCell12Voltage "Cell Voltage of Hyperion Battery (48V)";
CM_ SG_ 1409 SensorF_OD_TitanCell11Voltage "Cell Voltage of Hyperion Battery (48V)";
CM_ SG_ 1409 SensorF_OD_TitanCell10Voltage "Cell Voltage of Hyperion Battery (48V)";
CM_ SG_ 1409 SensorF_OD_TitanCell9Voltage "Cell Voltage of Hyperion Battery (48V)";
CM_ SG_ 1409 SensorF_OD_TitanCell8Voltage "Cell Voltage of Hyperion Battery (48V)";
CM_ SG_ 1409 SensorF_OD_TitanCell7Voltage "Cell Voltage of Hyperion Battery (48V)";
CM_ SG_ 1409 SensorF_OD_TitanCell6Voltage "Cell Voltage of Hyperion Battery (48V)";
CM_ SG_ 1409 SensorF_OD_TitanCell5Voltage "Cell Voltage of Hyperion Battery (48V)";
CM_ SG_ 1409 SensorF_OD_TitanCell4Voltage "Cell Voltage of Hyperion Battery (48V)";
CM_ SG_ 1409 SensorF_OD_TitanCell3Voltage "Cell Voltage of Hyperion Battery (48V)";
CM_ SG_ 1409 SensorF_OD_TitanCell2Voltage "Cell Voltage of Hyperion Battery (48V)";
CM_ SG_ 1409 SensorF_OD_TitanCell1Voltage "Cell Voltage of Hyperion Battery (48V)";
CM_ SG_ 1409 SensorF_OD_TitanHealthStatus "Health Status of Hyperion Battery (48V)";
CM_ SG_ 1409 SensorF_OD_TitanLifeCycle "Charge Discharge cycles of Hyperion Battery (48V)";
CM_ SG_ 1409 SensorF_OD_TitanRemainingCapacit "Remaining Capacity of Hyperion Battery (48V)";
CM_ SG_ 1409 SensorF_OD_TitanCurrent "Current of the Hyperion Battery (48V)";
CM_ SG_ 1409 SensorF_OD_TitanVoltage "Voltage of the Hyperion Battery (48V)";
CM_ SG_ 1409 SensorF_OD_TitanTemperature "Temperature of the Hyperion Battery (48V)";
CM_ SG_ 1409 SensorF_OD_HyperionCell12Voltage "Cell Voltage of Hyperion Battery (48V)";
CM_ SG_ 1409 SensorF_OD_HyperionCell11Voltage "Cell Voltage of Hyperion Battery (48V)";
CM_ SG_ 1409 SensorF_OD_HyperionCell10Voltage "Cell Voltage of Hyperion Battery (48V)";
CM_ SG_ 1409 SensorF_OD_HyperionCell9Voltage "Cell Voltage of Hyperion Battery (48V)";
CM_ SG_ 1409 SensorF_OD_HyperionCell8Voltage "Cell Voltage of Hyperion Battery (48V)";
CM_ SG_ 1409 SensorF_OD_HyperionCell7Voltage "Cell Voltage of Hyperion Battery (48V)";
CM_ SG_ 1409 SensorF_OD_HyperionCell6Voltage "Cell Voltage of Hyperion Battery (48V)";
CM_ SG_ 1409 SensorF_OD_HyperionCell5Voltage "Cell Voltage of Hyperion Battery (48V)";
CM_ SG_ 1409 SensorF_OD_HyperionCell4Voltage "Cell Voltage of Hyperion Battery (48V)";
CM_ SG_ 1409 SensorF_OD_HyperionCell3Voltage "Cell Voltage of Hyperion Battery (48V)";
CM_ SG_ 1409 SensorF_OD_HyperionCell2Voltage "Cell Voltage of Hyperion Battery (48V)";
CM_ SG_ 1409 SensorF_OD_HyperionCell1Voltage "Cell Voltage of Hyperion Battery (48V)";
CM_ SG_ 1409 SensorF_OD_HyperionHealthStatus "Health Status of Hyperion Battery (48V)";
CM_ SG_ 1409 SensorF_OD_HyperionLifeCycle "Charge Discharge cycles of Hyperion Battery (48V)";
CM_ SG_ 1409 SensorF_OD_HyperionRemainingCapa "Remaining Capacity of Hyperion Battery (48V)";
CM_ SG_ 1409 SensorF_OD_HyperionCurrent "Current of the Hyperion Battery (48V)";
CM_ SG_ 1409 SensorF_OD_HyperionVoltage "Voltage of the Hyperion Battery (48V)";
CM_ SG_ 1409 SensorF_OD_HyperionTemperature "Temperature of the Hyperion Battery (48V)";
CM_ SG_ 1409 SensorF_OD_SetReset "Reset the position of the encoder and IMU to zero.";
CM_ SG_ 1409 SensorF_OD_Velocity "Estimated Pod velocity";
CM_ SG_ 1409 SensorF_OD_Position "Estimated Pod position";
CM_ SG_ 1409 SensorF_OD_StripeCount "Fiducial Stripe Counter";
CM_ SG_ 1409 SensorF_OD_MdbState "State of all mdbs if not the same on all mdbs inconsistant.";
CM_ SG_ 1409 SensorF_OD_Magnet_6_Temperature "Magnet_6_Temperature";
CM_ SG_ 1409 SensorF_OD_Magnet_5_Temperature "Magnet_5_Temperature";
CM_ SG_ 1409 SensorF_OD_Magnet_4_Temperature "Magnet_4_Temperature";
CM_ SG_ 1409 SensorF_OD_Magnet_3_Temperature "Magnet_3_Temperature";
CM_ SG_ 1409 SensorF_OD_Magnet_2_Temperature "Magnet_2_Temperature";
CM_ SG_ 1409 SensorF_OD_Magnet_1_Temperature "Magnet_1_Temperature";
CM_ SG_ 1409 SensorF_OD_ReservoirTemperature "Cooling Reservoir Temperature";
CM_ SG_ 1409 SensorF_OD_CoolingPressure "IMU cooling pressure.";
CM_ SG_ 1409 SensorF_OD_IMU_GyroZ "IMU gyro z";
CM_ SG_ 1409 SensorF_OD_IMU_GyroY "IMU gyro y";
CM_ SG_ 1409 SensorF_OD_IMU_GyroX "IMU gyro X";
CM_ SG_ 1409 SensorF_OD_IMU_AccelZ "IMU accel z";
CM_ SG_ 1409 SensorF_OD_IMU_AccelY "IMU accel y";
CM_ SG_ 1409 SensorF_OD_IMU_AccelX "IMU accel X";
CM_ SG_ 1409 SensorF_OD_IMU3_Temperature "Internal temperature of IMU3.";
CM_ SG_ 1409 SensorF_OD_IMU2_Temperature "Internal temperature of IMU2.";
CM_ SG_ 1409 SensorF_OD_IMU1_Temperature "Internal temperature of IMU1.";
CM_ SG_ 1409 SensorF_OD_IMU_number "Number of IMUs that are online.";
CM_ SG_ 1409 SensorF_OD_EncoderResetPosition "Reset the position of the encoder to zero.";
CM_ SG_ 1409 SensorF_OD_EncoderWheelDiameter "Diameter of the encoder wheel in mm.";
CM_ SG_ 1409 SensorF_OD_HVBatteryMode "Switch the HV Battery from discharging to charging mode.";
CM_ SG_ 1409 SensorF_OD_StateMachineActivate "If it is deactivated, then no signals are sent by stateMachine";
CM_ SG_ 1409 SensorF_OD_StateMachineInterval "Interval in milliseconds for the state machine execution.";
CM_ SG_ 1409 SensorF_OD_TelemetryCommands "Commands from Telemetry to State Machine";
CM_ SG_ 1409 SensorF_OD_samplingInterval "Sensor sampling interval in ms.";
CM_ SG_ 1409 SensorF_OD_CAN2_DelayedTxMessage "Number of delayed TX messages on CAN2 because no messagebox was free.";
CM_ SG_ 1409 SensorF_OD_CAN2_ErrorStatus "Internal error status (e.g. Error active, Error passive, Bus Off)";
CM_ SG_ 1409 SensorF_OD_CAN2_DiscardedTxMessa "Number of discarded TX messages on CAN2 because all messageboxes were full";
CM_ SG_ 1409 SensorF_OD_CAN2_Status "Status of CAN2.";
CM_ SG_ 1409 SensorF_OD_CAN2_Baudrate "Baudrate of CAN.";
CM_ SG_ 1409 SensorF_OD_CAN2_autoErrorReset "Automatic reset of errors.";
CM_ SG_ 1409 SensorF_OD_CAN2_lastErrorCode "Last error code.";
CM_ SG_ 1409 SensorF_OD_CAN2_RxErrCnt "Receive error count of CAN1.";
CM_ SG_ 1409 SensorF_OD_CAN2_TxErrCnt "Transmit error count of CAN1.";
CM_ SG_ 1409 SensorF_OD_CAN1_DelayedTxMessage "Number of delayed TX messages on CAN1 because no messagebox was free.";
CM_ SG_ 1409 SensorF_OD_CAN1_ErrorStatus "Internal error status (e.g. Error active, Error passive, Bus Off)";
CM_ SG_ 1409 SensorF_OD_CAN1_DiscardedTxMessa "Number of discarded TX messages on CAN1 because all messageboxes were full";
CM_ SG_ 1409 SensorF_OD_CAN1_Status "Status of CAN1.";
CM_ SG_ 1409 SensorF_OD_CAN1_Baudrate "Baudrate of CAN.";
CM_ SG_ 1409 SensorF_OD_CAN1_autoErrorReset "Automatic reset of errors.";
CM_ SG_ 1409 SensorF_OD_CAN1_lastErrorCode "Last error code.";
CM_ SG_ 1409 SensorF_OD_CAN1_RxErrCnt "Receive error count of CAN1.";
CM_ SG_ 1409 SensorF_OD_CAN1_TxErrCnt "Transmit error count of CAN1.";
CM_ SG_ 1409 SensorF_OD_BuildTime "Software build time in the format HHMMSS.";
CM_ SG_ 1409 SensorF_OD_BuildDate "Software build date in the format YYYYMMDD.";
CM_ SG_ 1409 SensorF_OD_ChipUID2 "Seccond part of unique ID of microcontroller.";
CM_ SG_ 1409 SensorF_OD_ChipUID1 "First part of unique ID of microcontroller.";
CM_ SG_ 1409 SensorF_OD_SdcOut "Measurement of Shutdown Circuit Output";
CM_ SG_ 1409 SensorF_OD_SdcIn "Measurement of Shutdown Circuit Input";
CM_ SG_ 1409 SensorF_OD_runtime "Runtime of chip in milliseconds.";
CM_ SG_ 1409 SensorF_OD_InputVoltage "Board supply voltage.";
CM_ SG_ 1409 SensorF_OD_BoardTemp "Temperature of board";
CM_ SG_ 1409 SensorF_OD_MemFree "Free memory in bytes.";
CM_ SG_ 1409 SensorF_OD_CpuUsage "Current CPU usage in %.";
CM_ SG_ 1409 SensorF_OD_OdEntrySendInterval "Interval for sending all readable OD entries. Sending is disabled if less than 5 ms.";
CM_ SG_ 1409 SensorF_OD_SendOdOnBootup "Whether to send all OD entries on bootup.";
CM_ SG_ 1409 SensorF_OD_HeartbeatInterval "Heartbeat Interval in milliseconds.";
CM_ SG_ 1409 SensorF_OD_DbcVersion "CANzero DBC version.";
CM_ SG_ 1409 SensorF_OD_StackVersion "CANzero stack version.";
CM_ SG_ 1409 SensorF_OD_ProtocolVersion "CANzero Protocol Version.";
CM_ SG_ 1409 SensorF_OD_NodeStatus "State of the node.";
CM_ SG_ 1409 SensorF_OD_NodeID "CANzero Node-ID.";
CM_ SG_ 1409 SensorF_SDO_RespCode "Response code of SDO access.";
CM_ SG_ 1409 SensorF_SDO_ID "Specifies SDO-ID of SensorF";
CM_ BO_ 1473 "DO NOT CHANGE ANYTHING HERE!
SDO Request Upload to node SensorF with Node-ID 0x1";
CM_ SG_ 1473 SensorF_OD_TitanCell12Voltage "Cell Voltage of Hyperion Battery (48V)";
CM_ SG_ 1473 SensorF_OD_TitanCell11Voltage "Cell Voltage of Hyperion Battery (48V)";
CM_ SG_ 1473 SensorF_OD_TitanCell10Voltage "Cell Voltage of Hyperion Battery (48V)";
CM_ SG_ 1473 SensorF_OD_TitanCell9Voltage "Cell Voltage of Hyperion Battery (48V)";
CM_ SG_ 1473 SensorF_OD_TitanCell8Voltage "Cell Voltage of Hyperion Battery (48V)";
CM_ SG_ 1473 SensorF_OD_TitanCell7Voltage "Cell Voltage of Hyperion Battery (48V)";
CM_ SG_ 1473 SensorF_OD_TitanCell6Voltage "Cell Voltage of Hyperion Battery (48V)";
CM_ SG_ 1473 SensorF_OD_TitanCell5Voltage "Cell Voltage of Hyperion Battery (48V)";
CM_ SG_ 1473 SensorF_OD_TitanCell4Voltage "Cell Voltage of Hyperion Battery (48V)";
CM_ SG_ 1473 SensorF_OD_TitanCell3Voltage "Cell Voltage of Hyperion Battery (48V)";
CM_ SG_ 1473 SensorF_OD_TitanCell2Voltage "Cell Voltage of Hyperion Battery (48V)";
CM_ SG_ 1473 SensorF_OD_TitanCell1Voltage "Cell Voltage of Hyperion Battery (48V)";
CM_ SG_ 1473 SensorF_OD_TitanHealthStatus "Health Status of Hyperion Battery (48V)";
CM_ SG_ 1473 SensorF_OD_TitanLifeCycle "Charge Discharge cycles of Hyperion Battery (48V)";
CM_ SG_ 1473 SensorF_OD_TitanRemainingCa_0000 "Remaining Capacity of Hyperion Battery (48V)";
CM_ SG_ 1473 SensorF_OD_TitanCurrent "Current of the Hyperion Battery (48V)";
CM_ SG_ 1473 SensorF_OD_TitanVoltage "Voltage of the Hyperion Battery (48V)";
CM_ SG_ 1473 SensorF_OD_TitanTemperature "Temperature of the Hyperion Battery (48V)";
CM_ SG_ 1473 SensorF_OD_HyperionCell12Voltage "Cell Voltage of Hyperion Battery (48V)";
CM_ SG_ 1473 SensorF_OD_HyperionCell11Voltage "Cell Voltage of Hyperion Battery (48V)";
CM_ SG_ 1473 SensorF_OD_HyperionCell10Voltage "Cell Voltage of Hyperion Battery (48V)";
CM_ SG_ 1473 SensorF_OD_HyperionCell9Voltage "Cell Voltage of Hyperion Battery (48V)";
CM_ SG_ 1473 SensorF_OD_HyperionCell8Voltage "Cell Voltage of Hyperion Battery (48V)";
CM_ SG_ 1473 SensorF_OD_HyperionCell7Voltage "Cell Voltage of Hyperion Battery (48V)";
CM_ SG_ 1473 SensorF_OD_HyperionCell6Voltage "Cell Voltage of Hyperion Battery (48V)";
CM_ SG_ 1473 SensorF_OD_HyperionCell5Voltage "Cell Voltage of Hyperion Battery (48V)";
CM_ SG_ 1473 SensorF_OD_HyperionCell4Voltage "Cell Voltage of Hyperion Battery (48V)";
CM_ SG_ 1473 SensorF_OD_HyperionCell3Voltage "Cell Voltage of Hyperion Battery (48V)";
CM_ SG_ 1473 SensorF_OD_HyperionCell2Voltage "Cell Voltage of Hyperion Battery (48V)";
CM_ SG_ 1473 SensorF_OD_HyperionCell1Voltage "Cell Voltage of Hyperion Battery (48V)";
CM_ SG_ 1473 SensorF_OD_HyperionHealthStatus "Health Status of Hyperion Battery (48V)";
CM_ SG_ 1473 SensorF_OD_HyperionLifeCycle "Charge Discharge cycles of Hyperion Battery (48V)";
CM_ SG_ 1473 SensorF_OD_HyperionRemainin_0000 "Remaining Capacity of Hyperion Battery (48V)";
CM_ SG_ 1473 SensorF_OD_HyperionCurrent "Current of the Hyperion Battery (48V)";
CM_ SG_ 1473 SensorF_OD_HyperionVoltage "Voltage of the Hyperion Battery (48V)";
CM_ SG_ 1473 SensorF_OD_HyperionTemperature "Temperature of the Hyperion Battery (48V)";
CM_ SG_ 1473 SensorF_OD_SetReset "Reset the position of the encoder and IMU to zero.";
CM_ SG_ 1473 SensorF_OD_Velocity "Estimated Pod velocity";
CM_ SG_ 1473 SensorF_OD_Position "Estimated Pod position";
CM_ SG_ 1473 SensorF_OD_StripeCount "Fiducial Stripe Counter";
CM_ SG_ 1473 SensorF_OD_MdbState "State of all mdbs if not the same on all mdbs inconsistant.";
CM_ SG_ 1473 SensorF_OD_Magnet_6_Temperature "Magnet_6_Temperature";
CM_ SG_ 1473 SensorF_OD_Magnet_5_Temperature "Magnet_5_Temperature";
CM_ SG_ 1473 SensorF_OD_Magnet_4_Temperature "Magnet_4_Temperature";
CM_ SG_ 1473 SensorF_OD_Magnet_3_Temperature "Magnet_3_Temperature";
CM_ SG_ 1473 SensorF_OD_Magnet_2_Temperature "Magnet_2_Temperature";
CM_ SG_ 1473 SensorF_OD_Magnet_1_Temperature "Magnet_1_Temperature";
CM_ SG_ 1473 SensorF_OD_ReservoirTemperature "Cooling Reservoir Temperature";
CM_ SG_ 1473 SensorF_OD_CoolingPressure "IMU cooling pressure.";
CM_ SG_ 1473 SensorF_OD_IMU_GyroZ "IMU gyro z";
CM_ SG_ 1473 SensorF_OD_IMU_GyroY "IMU gyro y";
CM_ SG_ 1473 SensorF_OD_IMU_GyroX "IMU gyro X";
CM_ SG_ 1473 SensorF_OD_IMU_AccelZ "IMU accel z";
CM_ SG_ 1473 SensorF_OD_IMU_AccelY "IMU accel y";
CM_ SG_ 1473 SensorF_OD_IMU_AccelX "IMU accel X";
CM_ SG_ 1473 SensorF_OD_IMU3_Temperature "Internal temperature of IMU3.";
CM_ SG_ 1473 SensorF_OD_IMU2_Temperature "Internal temperature of IMU2.";
CM_ SG_ 1473 SensorF_OD_IMU1_Temperature "Internal temperature of IMU1.";
CM_ SG_ 1473 SensorF_OD_IMU_number "Number of IMUs that are online.";
CM_ SG_ 1473 SensorF_OD_EncoderResetPosition "Reset the position of the encoder to zero.";
CM_ SG_ 1473 SensorF_OD_EncoderWheelDiameter "Diameter of the encoder wheel in mm.";
CM_ SG_ 1473 SensorF_OD_HVBatteryMode "Switch the HV Battery from discharging to charging mode.";
CM_ SG_ 1473 SensorF_OD_StateMachineActivate "If it is deactivated, then no signals are sent by stateMachine";
CM_ SG_ 1473 SensorF_OD_StateMachineInterval "Interval in milliseconds for the state machine execution.";
CM_ SG_ 1473 SensorF_OD_TelemetryCommands "Commands from Telemetry to State Machine";
CM_ SG_ 1473 SensorF_OD_samplingInterval "Sensor sampling interval in ms.";
CM_ SG_ 1473 SensorF_OD_CAN2_DelayedTxMe_0000 "Number of delayed TX messages on CAN2 because no messagebox was free.";
CM_ SG_ 1473 SensorF_OD_CAN2_ErrorStatus "Internal error status (e.g. Error active, Error passive, Bus Off)";
CM_ SG_ 1473 SensorF_OD_CAN2_DiscardedTx_0000 "Number of discarded TX messages on CAN2 because all messageboxes were full";
CM_ SG_ 1473 SensorF_OD_CAN2_Status "Status of CAN2.";
CM_ SG_ 1473 SensorF_OD_CAN2_Baudrate "Baudrate of CAN.";
CM_ SG_ 1473 SensorF_OD_CAN2_autoErrorReset "Automatic reset of errors.";
CM_ SG_ 1473 SensorF_OD_CAN2_lastErrorCode "Last error code.";
CM_ SG_ 1473 SensorF_OD_CAN2_RxErrCnt "Receive error count of CAN1.";
CM_ SG_ 1473 SensorF_OD_CAN2_TxErrCnt "Transmit error count of CAN1.";
CM_ SG_ 1473 SensorF_OD_CAN1_DelayedTxMe_0000 "Number of delayed TX messages on CAN1 because no messagebox was free.";
CM_ SG_ 1473 SensorF_OD_CAN1_ErrorStatus "Internal error status (e.g. Error active, Error passive, Bus Off)";
CM_ SG_ 1473 SensorF_OD_CAN1_DiscardedTx_0000 "Number of discarded TX messages on CAN1 because all messageboxes were full";
CM_ SG_ 1473 SensorF_OD_CAN1_Status "Status of CAN1.";
CM_ SG_ 1473 SensorF_OD_CAN1_Baudrate "Baudrate of CAN.";
CM_ SG_ 1473 SensorF_OD_CAN1_autoErrorReset "Automatic reset of errors.";
CM_ SG_ 1473 SensorF_OD_CAN1_lastErrorCode "Last error code.";
CM_ SG_ 1473 SensorF_OD_CAN1_RxErrCnt "Receive error count of CAN1.";
CM_ SG_ 1473 SensorF_OD_CAN1_TxErrCnt "Transmit error count of CAN1.";
CM_ SG_ 1473 SensorF_OD_BuildTime "Software build time in the format HHMMSS.";
CM_ SG_ 1473 SensorF_OD_BuildDate "Software build date in the format YYYYMMDD.";
CM_ SG_ 1473 SensorF_OD_ChipUID2 "Seccond part of unique ID of microcontroller.";
CM_ SG_ 1473 SensorF_OD_ChipUID1 "First part of unique ID of microcontroller.";
CM_ SG_ 1473 SensorF_OD_SdcOut "Measurement of Shutdown Circuit Output";
CM_ SG_ 1473 SensorF_OD_SdcIn "Measurement of Shutdown Circuit Input";
CM_ SG_ 1473 SensorF_OD_runtime "Runtime of chip in milliseconds.";
CM_ SG_ 1473 SensorF_OD_InputVoltage "Board supply voltage.";
CM_ SG_ 1473 SensorF_OD_BoardTemp "Temperature of board";
CM_ SG_ 1473 SensorF_OD_MemFree "Free memory in bytes.";
CM_ SG_ 1473 SensorF_OD_CpuUsage "Current CPU usage in %.";
CM_ SG_ 1473 SensorF_OD_OdEntrySendInterval "Interval for sending all readable OD entries. Sending is disabled if less than 5 ms.";
CM_ SG_ 1473 SensorF_OD_SendOdOnBootup "Whether to send all OD entries on bootup.";
CM_ SG_ 1473 SensorF_OD_HeartbeatInterval "Heartbeat Interval in milliseconds.";
CM_ SG_ 1473 SensorF_OD_DbcVersion "CANzero DBC version.";
CM_ SG_ 1473 SensorF_OD_StackVersion "CANzero stack version.";
CM_ SG_ 1473 SensorF_OD_ProtocolVersion "CANzero Protocol Version.";
CM_ SG_ 1473 SensorF_OD_NodeStatus "State of the node.";
CM_ SG_ 1473 SensorF_OD_NodeID "CANzero Node-ID.";
CM_ SG_ 1473 SensorF_SDO_ID "Specifies SDO-ID of SensorF";
CM_ BO_ 1537 "DO NOT CHANGE ANYTHING HERE!
SDO Request Download from node SensorF with Node-ID 0x1";
CM_ SG_ 1537 SensorF_SDO_ID "Specifies SDO-ID of SensorF";
CM_ BO_ 1793 "Heartbeat of node SensorF with Node-ID 0x1";
CM_ SG_ 1793 SensorF_NodeState "Heartbeat status of node SensorF";
CM_ BO_ 1857 "Bootloader transmit from node SensorF with Node-ID 0x1";
CM_ BO_ 1921 "Bootloader receive by node SensorF with Node-ID 0x1";
CM_ BO_ 130 "Emergency message of node SensorR with Node-ID 0x2";
CM_ SG_ 130 SensorR_E12_highLIMTemperature "Error when motor temperature is too high.";
CM_ SG_ 130 SensorR_E11_scimoPEerror101overc "Current of a single phase too high (for more than 4 samples).";
CM_ SG_ 130 SensorR_E10_scimoPEerror103sumcu "Sum of the phase current too high.";
CM_ SG_ 130 SensorR_E9_scimoPEerror102overcu "Current of a single phase too high (for more than 4 samples).";
CM_ SG_ 130 SensorR_E8_scimoPEerror024motTem "Error if motor temperature too high.";
CM_ SG_ 130 SensorR_E7_scimoPEerror020uZKmin "Error if intermediate circuit voltage too low.";
CM_ SG_ 130 SensorR_E6_scimoPEerror009Pulslo "Error if hardware enable not given.";
CM_ SG_ 130 SensorR_E5_accEmergencyStop "The acceleration can not be measured directly by any sensor";
CM_ SG_ 130 SensorR_E4_velEmergencyStop "The velocity can not be measured directly by any sensor";
CM_ SG_ 130 SensorR_E3_posEmergencyStop "The position can not be measured directly by any sensor";
CM_ SG_ 130 SensorR_E2_stripeEmergencyStop "PlausibilitxCheck goes wrong, the position is not wiithin the range of the stripes";
CM_ SG_ 130 SensorR_E1_trajectoryError "Error when they Trajectory differs to much from the setpoint.";
CM_ SG_ 130 SensorR_E0_OtherError "Other error.";
CM_ SG_ 130 SensorR_W10_highLIMTemperature "Warning when motor temperature is too high. FIXME";
CM_ SG_ 130 SensorR_W9_restrictingVelocity "Warning when required velocity is higher than allowed. FIXME";
CM_ SG_ 130 SensorR_W8_outOfLimModelBoundari "Warning when required thrust force is large and acceleration has a different sign. FIXME";
CM_ SG_ 130 SensorR_W7_highOscillations "Warning when high oscillations occur. FIXME";
CM_ SG_ 130 SensorR_W6_sciMoPEwarning104FETt "High temperature of FETs.";
CM_ SG_ 130 SensorR_W5_sciMoPEwarning069CPUt "High temperature of PE controller CPU.";
CM_ SG_ 130 SensorR_W4_stateEstimationAccWar "One acceleration measurement is out of range";
CM_ SG_ 130 SensorR_W3_stateEstimationPosWar "One position measurement is out of range";
CM_ SG_ 130 SensorR_W2_stateEstimationVelWar "One velocity measurement is out of range";
CM_ SG_ 130 SensorR_W1_stripeWarning "Warning when the measured position is not within the half allowed distance of the two nearest stripes";
CM_ SG_ 130 SensorR_W0_OtherWarning "Other warning.";
CM_ BO_ 386 "Transmit PDO 1 of node SensorR with Node-ID 0x2. Data of front IMU.";
CM_ SG_ 386 SensorR_TX_GyroFront_Z "Slope of front IMU in Z direction.";
CM_ SG_ 386 SensorR_TX_AccFront_Z "Acceleration of front IMU in Z direction.";
CM_ SG_ 386 SensorR_TX_AccFront_Y "Acceleration of front IMU in Y direction.";
CM_ SG_ 386 SensorR_TX_AccFront_X "Acceleration of front IMU in X direction.";
CM_ BO_ 514 "Transmit PDO 2 of node SensorR with Node-ID 0x2. RunState, Enabled, ErrorFlag, TrajectorySet";
CM_ SG_ 514 SensorR_TX_ErrorFlag "Error status of SensorR.";
CM_ SG_ 514 SensorR_TX_Enabled "Enable status of SensorR.";
CM_ SG_ 514 SensorR_TX_TrajectorySet "Flag for trajectorySet";
CM_ SG_ 514 SensorR_TX_RunState "State of run of SensorR.";
CM_ BO_ 578 "Receive PDO 2 of node SensorR with Node-ID 0x2.";
CM_ BO_ 642 "Transmit PDO 3 of node SensorR with Node-ID 0x2. Filtered data after StateEstimation";
CM_ SG_ 642 SensorR_TX_Pos "Filtered position by StateEstimation.";
CM_ SG_ 642 SensorR_TX_Vel "Filtered velocity by StateEstimation.";
CM_ SG_ 642 SensorR_TX_Acc "Filtered acceleration by StateEstimation.";
CM_ BO_ 706 "Receive PDO 3 of node SensorR with Node-ID 0x2";
CM_ SG_ 706 SensorR_RX_ErrorReset "Error reset signal for SensorR.";
CM_ SG_ 706 SensorR_RX_Enable "Enable signal for SensorR.";
CM_ SG_ 706 SensorR_RX_LaunchComm "Launch Command of SensorR.";
CM_ BO_ 770 "Transmit PDO 4 of node SensorR with Node-ID 0x2. Velocity of EncoderFront, rear and optical, Stripes";
CM_ SG_ 770 SensorR_TX_Vel_Optical "Velocity of optical Sensor.";
CM_ SG_ 770 SensorR_TX_Vel_EncoderRear "Velocity of Wheel Encoder rear.";
CM_ SG_ 770 SensorR_TX_Vel_EncoderFront "Velocity of Wheel Encoder front.";
CM_ BO_ 834 "Receive PDO 4 of node SensorR with Node-ID 0x2.";
CM_ BO_ 898 "Transmit PDO 5 of node SensorR with Node-ID 0x2. Gyroscope data of IMU front and rear in X and Y direction.";
CM_ SG_ 898 SensorR_TX_GyroRear_Y "Slope of rear IMU in Y direction.";
CM_ SG_ 898 SensorR_TX_GyroRear_X "Slope of rear IMU in X direction.";
CM_ SG_ 898 SensorR_TX_GyroFront_Y "Slope of front IMU in Y direction.";
CM_ SG_ 898 SensorR_TX_GyroFront_X "Slope of front IMU in X direction.";
CM_ BO_ 962 "Transmit PDO 6 of node SensorR with Node-ID 0x2";
CM_ BO_ 1026 "Transmit PDO 7 of node SensorR with Node-ID 0x2. Gap Height of left and right sensor.";
CM_ SG_ 1026 SensorR_TX_GapHeight_Right "Gap height of LIM right.";
CM_ SG_ 1026 SensorR_TX_GapHeight_Left "Gap height of LIM left.";
CM_ BO_ 1090 "Transmit PDO 8 of node SensorR with Node-ID 0x2";
CM_ BO_ 1154 "Transmit PDO 9 of node SensorR with Node-ID 0x2";
CM_ BO_ 1218 "Transmit PDO 10 of node SensorR with Node-ID 0x2. Send acceleration of IMU Rear.";
CM_ SG_ 1218 SensorR_TX_GyroRear_Z "Slope of rear IMU in Z direction.";
CM_ SG_ 1218 SensorR_TX_AccRear_Z "Acceleration of rear IMU in Z direction.";
CM_ SG_ 1218 SensorR_TX_AccRear_Y "Acceleration of rear IMU in Y direction.";
CM_ SG_ 1218 SensorR_TX_AccRear_X "Acceleration of rear IMU in X direction.";
CM_ BO_ 1282 "Transmit PDO 11 of node SensorR with Node-ID 0x2. Send position data of Encoder front, rear and optical and Stripes.";
CM_ SG_ 1282 SensorR_TX_StripeCounter_Right "Counting reflectors on the right site.";
CM_ SG_ 1282 SensorR_TX_StripeCounter_Left "Counting reflectors on the left site.";
CM_ SG_ 1282 SensorR_TX_Pos_Optical "Position of optical Sensor.";
CM_ SG_ 1282 SensorR_TX_Pos_EncoderRear "Position of Wheel Encoder rear.";
CM_ SG_ 1282 SensorR_TX_Pos_EncoderFront "Position of Wheel Encoder front.";
CM_ BO_ 1346 "Transmit PDO 12 of node SensorR with Node-ID 0x2.";
BA_DEF_ SG_  "GenSigSendType" ENUM  "Cyclic","OnWrite","OnWriteWithRepetition","OnChange","OnChangeWithRepetition","IfActive","IfActiveWithRepetition","NoSigSendType";
BA_DEF_ BO_  "GenMsgSendType" ENUM  "Cyclic","not_used","not_used","not_used","not_used","Cyclic","not_used","IfActive","NoMsgSendType";
BA_DEF_  "BusType" STRING ;
BA_DEF_  "DBName" STRING ;
BA_DEF_ BO_  "GenMsgCycleTime" INT 2 50000;
BA_DEF_ BO_  "GenMsgDelayTime" INT 1 1000;
BA_DEF_ BO_  "GenMsgNrOfRepetitions" INT 1 999999;
BA_DEF_ SG_  "GenSigStartValue" FLOAT 0 100000000000;
BA_DEF_  "CANzero_ProtocolVersion" STRING ;
BA_DEF_  "CANzero_DBCVersion" INT 0 16777215;
BA_DEF_  "CANzero_SDOClientName" STRING ;
BA_DEF_  "CANzero_NMTMasterName" STRING ;
BA_DEF_ BU_  "CANzero_NodeID" HEX 0 63;
BA_DEF_ SG_  "CANzero_SDO_Group" STRING ;
BA_DEF_ SG_  "CANzero_SDO_AccessIfOperational" ENUM  "No","Yes";
BA_DEF_ SG_  "CANzero_SDO_AccessType" ENUM  "Read Write","Read Only","Write Only";
BA_DEF_ SG_  "CANzero_SDO_Default" FLOAT 0 0;
BA_DEF_ SG_  "SystemSignalLongSymbol" STRING ;
BA_DEF_DEF_  "GenSigSendType" "Cyclic";
BA_DEF_DEF_  "GenMsgSendType" "NoMsgSendType";
BA_DEF_DEF_  "BusType" "";
BA_DEF_DEF_  "DBName" "";
BA_DEF_DEF_  "GenMsgCycleTime" 100;
BA_DEF_DEF_  "GenMsgDelayTime" 1;
BA_DEF_DEF_  "GenMsgNrOfRepetitions" 1;
BA_DEF_DEF_  "GenSigStartValue" 0;
BA_DEF_DEF_  "CANzero_ProtocolVersion" "";
BA_DEF_DEF_  "CANzero_DBCVersion" 0;
BA_DEF_DEF_  "CANzero_SDOClientName" "Master";
BA_DEF_DEF_  "CANzero_NMTMasterName" "Master";
BA_DEF_DEF_  "CANzero_NodeID" 0;
BA_DEF_DEF_  "CANzero_SDO_Group" "";
BA_DEF_DEF_  "CANzero_SDO_AccessIfOperational" "No";
BA_DEF_DEF_  "CANzero_SDO_AccessType" "Read Write";
BA_DEF_DEF_  "CANzero_SDO_Default" 0;
BA_DEF_DEF_  "SystemSignalLongSymbol" "";
BA_ "BusType" "CAN";
BA_ "CANzero_ProtocolVersion" "V1.0";
BA_ "CANzero_DBCVersion" 213;
BA_ "CANzero_SDOClientName" "TelemetryNode";
BA_ "DBName" "pod2022";
BA_ "CANzero_NodeID" BU_ TelemetryNode 34;
BA_ "CANzero_NodeID" BU_ SensorF 1;
BA_ "CANzero_NodeID" BU_ SensorR 2;
BA_ "CANzero_NodeID" BU_ BrakeF 17;
BA_ "CANzero_NodeID" BU_ BrakeR 18;
BA_ "CANzero_NodeID" BU_ PDU 26;
BA_ "CANzero_NodeID" BU_ HVCU 10;
BA_ "CANzero_NodeID" BU_ HVTU 25;
BA_ "CANzero_NodeID" BU_ MDB1 33;
BA_ "CANzero_NodeID" BU_ MDB2 35;
BA_ "CANzero_NodeID" BU_ MDB3 39;
BA_ "CANzero_NodeID" BU_ MDB4 40;
BA_ "CANzero_NodeID" BU_ MDB5 41;
BA_ "CANzero_NodeID" BU_ MDB6 49;
BA_ "CANzero_NodeID" BU_ Track 50;
BA_ "CANzero_NodeID" BU_ CLU 20;
BA_ "GenSigStartValue" SG_ 1041 BrakeF_TX_Pressure_Reservoir 400;
BA_ "GenSigStartValue" SG_ 1089 SensorF_TX_BatteryTemp 600;
BA_ "GenSigStartValue" SG_ 1153 SensorF_Cooling_Temp 600;
BA_ "GenSigStartValue" SG_ 1153 SensorF_LIMT_Stator_4 266.666666666667;
BA_ "GenSigStartValue" SG_ 1153 SensorF_LIMT_Stator_3 266.666666666667;
BA_ "GenSigStartValue" SG_ 1153 SensorF_LIMT_Stator_2 266.666666666667;
BA_ "GenSigStartValue" SG_ 1153 SensorF_LIMT_Stator_1 266.666666666667;
BA_ "CANzero_SDO_AccessType" SG_ 1409 SensorF_OD_TitanCell12Voltage 1;
BA_ "CANzero_SDO_AccessIfOperational" SG_ 1409 SensorF_OD_TitanCell12Voltage 1;
BA_ "CANzero_SDO_AccessType" SG_ 1409 SensorF_OD_TitanCell11Voltage 1;
BA_ "CANzero_SDO_AccessIfOperational" SG_ 1409 SensorF_OD_TitanCell11Voltage 1;
BA_ "CANzero_SDO_AccessType" SG_ 1409 SensorF_OD_TitanCell10Voltage 1;
BA_ "CANzero_SDO_AccessIfOperational" SG_ 1409 SensorF_OD_TitanCell10Voltage 1;
BA_ "CANzero_SDO_AccessType" SG_ 1409 SensorF_OD_TitanCell9Voltage 1;
BA_ "CANzero_SDO_AccessIfOperational" SG_ 1409 SensorF_OD_TitanCell9Voltage 1;
BA_ "CANzero_SDO_AccessType" SG_ 1409 SensorF_OD_TitanCell8Voltage 1;
BA_ "CANzero_SDO_AccessIfOperational" SG_ 1409 SensorF_OD_TitanCell8Voltage 1;
BA_ "CANzero_SDO_AccessType" SG_ 1409 SensorF_OD_TitanCell7Voltage 1;
BA_ "CANzero_SDO_AccessIfOperational" SG_ 1409 SensorF_OD_TitanCell7Voltage 1;
BA_ "CANzero_SDO_AccessType" SG_ 1409 SensorF_OD_TitanCell6Voltage 1;
BA_ "CANzero_SDO_AccessIfOperational" SG_ 1409 SensorF_OD_TitanCell6Voltage 1;
BA_ "CANzero_SDO_AccessType" SG_ 1409 SensorF_OD_TitanCell5Voltage 1;
BA_ "CANzero_SDO_AccessIfOperational" SG_ 1409 SensorF_OD_TitanCell5Voltage 1;
BA_ "CANzero_SDO_AccessType" SG_ 1409 SensorF_OD_TitanCell4Voltage 1;
BA_ "CANzero_SDO_AccessIfOperational" SG_ 1409 SensorF_OD_TitanCell4Voltage 1;
BA_ "CANzero_SDO_AccessType" SG_ 1409 SensorF_OD_TitanCell3Voltage 1;
BA_ "CANzero_SDO_AccessIfOperational" SG_ 1409 SensorF_OD_TitanCell3Voltage 1;
BA_ "CANzero_SDO_AccessType" SG_ 1409 SensorF_OD_TitanCell2Voltage 1;
BA_ "CANzero_SDO_AccessIfOperational" SG_ 1409 SensorF_OD_TitanCell2Voltage 1;
BA_ "CANzero_SDO_AccessType" SG_ 1409 SensorF_OD_TitanCell1Voltage 1;
BA_ "CANzero_SDO_AccessIfOperational" SG_ 1409 SensorF_OD_TitanCell1Voltage 1;
BA_ "CANzero_SDO_AccessType" SG_ 1409 SensorF_OD_TitanHealthStatus 1;
BA_ "CANzero_SDO_AccessIfOperational" SG_ 1409 SensorF_OD_TitanHealthStatus 1;
BA_ "CANzero_SDO_AccessType" SG_ 1409 SensorF_OD_TitanLifeCycle 1;
BA_ "CANzero_SDO_AccessIfOperational" SG_ 1409 SensorF_OD_TitanLifeCycle 1;
BA_ "CANzero_SDO_AccessType" SG_ 1409 SensorF_OD_TitanRemainingCapacit 1;
BA_ "CANzero_SDO_AccessIfOperational" SG_ 1409 SensorF_OD_TitanRemainingCapacit 1;
BA_ "SystemSignalLongSymbol" SG_ 1409 SensorF_OD_TitanRemainingCapacit "SensorF_OD_TitanRemainingCapacity";
BA_ "CANzero_SDO_AccessType" SG_ 1409 SensorF_OD_TitanCurrent 1;
BA_ "CANzero_SDO_AccessIfOperational" SG_ 1409 SensorF_OD_TitanCurrent 1;
BA_ "GenSigStartValue" SG_ 1409 SensorF_OD_TitanCurrent 10000.0;
BA_ "CANzero_SDO_AccessType" SG_ 1409 SensorF_OD_TitanVoltage 1;
BA_ "CANzero_SDO_AccessIfOperational" SG_ 1409 SensorF_OD_TitanVoltage 1;
BA_ "CANzero_SDO_AccessType" SG_ 1409 SensorF_OD_TitanTemperature 1;
BA_ "CANzero_SDO_AccessIfOperational" SG_ 1409 SensorF_OD_TitanTemperature 1;
BA_ "CANzero_SDO_AccessType" SG_ 1409 SensorF_OD_HyperionCell12Voltage 1;
BA_ "CANzero_SDO_AccessIfOperational" SG_ 1409 SensorF_OD_HyperionCell12Voltage 1;
BA_ "CANzero_SDO_AccessType" SG_ 1409 SensorF_OD_HyperionCell11Voltage 1;
BA_ "CANzero_SDO_AccessIfOperational" SG_ 1409 SensorF_OD_HyperionCell11Voltage 1;
BA_ "CANzero_SDO_AccessType" SG_ 1409 SensorF_OD_HyperionCell10Voltage 1;
BA_ "CANzero_SDO_AccessIfOperational" SG_ 1409 SensorF_OD_HyperionCell10Voltage 1;
BA_ "CANzero_SDO_AccessType" SG_ 1409 SensorF_OD_HyperionCell9Voltage 1;
BA_ "CANzero_SDO_AccessIfOperational" SG_ 1409 SensorF_OD_HyperionCell9Voltage 1;
BA_ "CANzero_SDO_AccessType" SG_ 1409 SensorF_OD_HyperionCell8Voltage 1;
BA_ "CANzero_SDO_AccessIfOperational" SG_ 1409 SensorF_OD_HyperionCell8Voltage 1;
BA_ "CANzero_SDO_AccessType" SG_ 1409 SensorF_OD_HyperionCell7Voltage 1;
BA_ "CANzero_SDO_AccessIfOperational" SG_ 1409 SensorF_OD_HyperionCell7Voltage 1;
BA_ "CANzero_SDO_AccessType" SG_ 1409 SensorF_OD_HyperionCell6Voltage 1;
BA_ "CANzero_SDO_AccessIfOperational" SG_ 1409 SensorF_OD_HyperionCell6Voltage 1;
BA_ "CANzero_SDO_AccessType" SG_ 1409 SensorF_OD_HyperionCell5Voltage 1;
BA_ "CANzero_SDO_AccessIfOperational" SG_ 1409 SensorF_OD_HyperionCell5Voltage 1;
BA_ "CANzero_SDO_AccessType" SG_ 1409 SensorF_OD_HyperionCell4Voltage 1;
BA_ "CANzero_SDO_AccessIfOperational" SG_ 1409 SensorF_OD_HyperionCell4Voltage 1;
BA_ "CANzero_SDO_AccessType" SG_ 1409 SensorF_OD_HyperionCell3Voltage 1;
BA_ "CANzero_SDO_AccessIfOperational" SG_ 1409 SensorF_OD_HyperionCell3Voltage 1;
BA_ "CANzero_SDO_AccessType" SG_ 1409 SensorF_OD_HyperionCell2Voltage 1;
BA_ "CANzero_SDO_AccessIfOperational" SG_ 1409 SensorF_OD_HyperionCell2Voltage 1;
BA_ "CANzero_SDO_AccessType" SG_ 1409 SensorF_OD_HyperionCell1Voltage 1;
BA_ "CANzero_SDO_AccessIfOperational" SG_ 1409 SensorF_OD_HyperionCell1Voltage 1;
BA_ "CANzero_SDO_AccessIfOperational" SG_ 1409 SensorF_OD_HyperionHealthStatus 1;
BA_ "CANzero_SDO_AccessType" SG_ 1409 SensorF_OD_HyperionLifeCycle 1;
BA_ "CANzero_SDO_AccessIfOperational" SG_ 1409 SensorF_OD_HyperionLifeCycle 1;
BA_ "CANzero_SDO_AccessType" SG_ 1409 SensorF_OD_HyperionRemainingCapa 1;
BA_ "CANzero_SDO_AccessIfOperational" SG_ 1409 SensorF_OD_HyperionRemainingCapa 1;
BA_ "SystemSignalLongSymbol" SG_ 1409 SensorF_OD_HyperionRemainingCapa "SensorF_OD_HyperionRemainingCapacity";
BA_ "CANzero_SDO_AccessType" SG_ 1409 SensorF_OD_HyperionCurrent 1;
BA_ "CANzero_SDO_AccessIfOperational" SG_ 1409 SensorF_OD_HyperionCurrent 1;
BA_ "GenSigStartValue" SG_ 1409 SensorF_OD_HyperionCurrent 10000.0;
BA_ "CANzero_SDO_AccessType" SG_ 1409 SensorF_OD_HyperionVoltage 1;
BA_ "CANzero_SDO_AccessIfOperational" SG_ 1409 SensorF_OD_HyperionVoltage 1;
BA_ "CANzero_SDO_AccessType" SG_ 1409 SensorF_OD_HyperionTemperature 1;
BA_ "CANzero_SDO_AccessIfOperational" SG_ 1409 SensorF_OD_HyperionTemperature 1;
BA_ "CANzero_SDO_AccessType" SG_ 1409 SensorF_OD_SetReset 2;
BA_ "CANzero_SDO_AccessIfOperational" SG_ 1409 SensorF_OD_SetReset 1;
BA_ "CANzero_SDO_AccessType" SG_ 1409 SensorF_OD_Velocity 1;
BA_ "CANzero_SDO_AccessIfOperational" SG_ 1409 SensorF_OD_Velocity 1;
BA_ "GenSigStartValue" SG_ 1409 SensorF_OD_Velocity 10000.0;
BA_ "CANzero_SDO_AccessType" SG_ 1409 SensorF_OD_Position 1;
BA_ "CANzero_SDO_AccessIfOperational" SG_ 1409 SensorF_OD_Position 1;
BA_ "GenSigStartValue" SG_ 1409 SensorF_OD_Position 10000.0;
BA_ "CANzero_SDO_AccessType" SG_ 1409 SensorF_OD_StripeCount 1;
BA_ "CANzero_SDO_AccessIfOperational" SG_ 1409 SensorF_OD_StripeCount 1;
BA_ "CANzero_SDO_AccessIfOperational" SG_ 1409 SensorF_OD_MdbState 1;
BA_ "CANzero_SDO_AccessType" SG_ 1409 SensorF_OD_Magnet_6_Temperature 1;
BA_ "CANzero_SDO_AccessIfOperational" SG_ 1409 SensorF_OD_Magnet_6_Temperature 1;
BA_ "GenSigStartValue" SG_ 1409 SensorF_OD_Magnet_6_Temperature 11000.0;
BA_ "CANzero_SDO_Default" SG_ 1409 SensorF_OD_Magnet_6_Temperature 10;
BA_ "CANzero_SDO_AccessType" SG_ 1409 SensorF_OD_Magnet_5_Temperature 1;
BA_ "CANzero_SDO_AccessIfOperational" SG_ 1409 SensorF_OD_Magnet_5_Temperature 1;
BA_ "GenSigStartValue" SG_ 1409 SensorF_OD_Magnet_5_Temperature 11000.0;
BA_ "CANzero_SDO_Default" SG_ 1409 SensorF_OD_Magnet_5_Temperature 10;
BA_ "CANzero_SDO_AccessType" SG_ 1409 SensorF_OD_Magnet_4_Temperature 1;
BA_ "CANzero_SDO_AccessIfOperational" SG_ 1409 SensorF_OD_Magnet_4_Temperature 1;
BA_ "GenSigStartValue" SG_ 1409 SensorF_OD_Magnet_4_Temperature 11000.0;
BA_ "CANzero_SDO_Default" SG_ 1409 SensorF_OD_Magnet_4_Temperature 10;
BA_ "CANzero_SDO_AccessType" SG_ 1409 SensorF_OD_Magnet_3_Temperature 1;
BA_ "CANzero_SDO_AccessIfOperational" SG_ 1409 SensorF_OD_Magnet_3_Temperature 1;
BA_ "GenSigStartValue" SG_ 1409 SensorF_OD_Magnet_3_Temperature 11000.0;
BA_ "CANzero_SDO_Default" SG_ 1409 SensorF_OD_Magnet_3_Temperature 10;
BA_ "CANzero_SDO_AccessType" SG_ 1409 SensorF_OD_Magnet_2_Temperature 1;
BA_ "CANzero_SDO_AccessIfOperational" SG_ 1409 SensorF_OD_Magnet_2_Temperature 1;
BA_ "GenSigStartValue" SG_ 1409 SensorF_OD_Magnet_2_Temperature 11000.0;
BA_ "CANzero_SDO_Default" SG_ 1409 SensorF_OD_Magnet_2_Temperature 10;
BA_ "CANzero_SDO_AccessType" SG_ 1409 SensorF_OD_Magnet_1_Temperature 1;
BA_ "CANzero_SDO_AccessIfOperational" SG_ 1409 SensorF_OD_Magnet_1_Temperature 1;
BA_ "GenSigStartValue" SG_ 1409 SensorF_OD_Magnet_1_Temperature 11000.0;
BA_ "CANzero_SDO_Default" SG_ 1409 SensorF_OD_Magnet_1_Temperature 10;
BA_ "CANzero_SDO_AccessType" SG_ 1409 SensorF_OD_ReservoirTemperature 1;
BA_ "CANzero_SDO_AccessIfOperational" SG_ 1409 SensorF_OD_ReservoirTemperature 1;
BA_ "GenSigStartValue" SG_ 1409 SensorF_OD_ReservoirTemperature 18000.0;
BA_ "CANzero_SDO_Default" SG_ 1409 SensorF_OD_ReservoirTemperature 80;
BA_ "CANzero_SDO_AccessType" SG_ 1409 SensorF_OD_CoolingPressure 1;
BA_ "CANzero_SDO_AccessIfOperational" SG_ 1409 SensorF_OD_CoolingPressure 1;
BA_ "GenSigStartValue" SG_ 1409 SensorF_OD_CoolingPressure 9810.0;
BA_ "CANzero_SDO_Default" SG_ 1409 SensorF_OD_CoolingPressure -1.9;
BA_ "CANzero_SDO_AccessType" SG_ 1409 SensorF_OD_IMU_GyroZ 1;
BA_ "CANzero_SDO_AccessIfOperational" SG_ 1409 SensorF_OD_IMU_GyroZ 1;
BA_ "GenSigStartValue" SG_ 1409 SensorF_OD_IMU_GyroZ 10000.0;
BA_ "CANzero_SDO_AccessType" SG_ 1409 SensorF_OD_IMU_GyroY 1;
BA_ "CANzero_SDO_AccessIfOperational" SG_ 1409 SensorF_OD_IMU_GyroY 1;
BA_ "GenSigStartValue" SG_ 1409 SensorF_OD_IMU_GyroY 10000.0;
BA_ "CANzero_SDO_AccessType" SG_ 1409 SensorF_OD_IMU_GyroX 1;
BA_ "CANzero_SDO_AccessIfOperational" SG_ 1409 SensorF_OD_IMU_GyroX 1;
BA_ "GenSigStartValue" SG_ 1409 SensorF_OD_IMU_GyroX 10000.0;
BA_ "CANzero_SDO_AccessType" SG_ 1409 SensorF_OD_IMU_AccelZ 1;
BA_ "CANzero_SDO_AccessIfOperational" SG_ 1409 SensorF_OD_IMU_AccelZ 1;
BA_ "GenSigStartValue" SG_ 1409 SensorF_OD_IMU_AccelZ 10000.0;
BA_ "CANzero_SDO_AccessType" SG_ 1409 SensorF_OD_IMU_AccelY 1;
BA_ "CANzero_SDO_AccessIfOperational" SG_ 1409 SensorF_OD_IMU_AccelY 1;
BA_ "GenSigStartValue" SG_ 1409 SensorF_OD_IMU_AccelY 10000.0;
BA_ "CANzero_SDO_AccessType" SG_ 1409 SensorF_OD_IMU_AccelX 1;
BA_ "CANzero_SDO_AccessIfOperational" SG_ 1409 SensorF_OD_IMU_AccelX 1;
BA_ "GenSigStartValue" SG_ 1409 SensorF_OD_IMU_AccelX 10000.0;
BA_ "CANzero_SDO_AccessType" SG_ 1409 SensorF_OD_IMU3_Temperature 1;
BA_ "CANzero_SDO_AccessIfOperational" SG_ 1409 SensorF_OD_IMU3_Temperature 1;
BA_ "GenSigStartValue" SG_ 1409 SensorF_OD_IMU3_Temperature 10000.0;
BA_ "CANzero_SDO_AccessType" SG_ 1409 SensorF_OD_IMU2_Temperature 1;
BA_ "CANzero_SDO_AccessIfOperational" SG_ 1409 SensorF_OD_IMU2_Temperature 1;
BA_ "GenSigStartValue" SG_ 1409 SensorF_OD_IMU2_Temperature 10000.0;
BA_ "CANzero_SDO_AccessType" SG_ 1409 SensorF_OD_IMU1_Temperature 1;
BA_ "CANzero_SDO_AccessIfOperational" SG_ 1409 SensorF_OD_IMU1_Temperature 1;
BA_ "GenSigStartValue" SG_ 1409 SensorF_OD_IMU1_Temperature 10000.0;
BA_ "CANzero_SDO_AccessType" SG_ 1409 SensorF_OD_IMU_number 1;
BA_ "CANzero_SDO_AccessIfOperational" SG_ 1409 SensorF_OD_IMU_number 1;
BA_ "CANzero_SDO_AccessType" SG_ 1409 SensorF_OD_EncoderResetPosition 2;
BA_ "CANzero_SDO_AccessIfOperational" SG_ 1409 SensorF_OD_EncoderResetPosition 1;
BA_ "CANzero_SDO_AccessIfOperational" SG_ 1409 SensorF_OD_EncoderWheelDiameter 1;
BA_ "GenSigStartValue" SG_ 1409 SensorF_OD_EncoderWheelDiameter 15000.0;
BA_ "CANzero_SDO_Default" SG_ 1409 SensorF_OD_EncoderWheelDiameter 75;
BA_ "CANzero_SDO_AccessIfOperational" SG_ 1409 SensorF_OD_HVBatteryMode 1;
BA_ "CANzero_SDO_AccessIfOperational" SG_ 1409 SensorF_OD_StateMachineActivate 1;
BA_ "CANzero_SDO_AccessIfOperational" SG_ 1409 SensorF_OD_StateMachineInterval 1;
BA_ "GenSigStartValue" SG_ 1409 SensorF_OD_StateMachineInterval 10.0;
BA_ "CANzero_SDO_Default" SG_ 1409 SensorF_OD_StateMachineInterval 10;
BA_ "CANzero_SDO_AccessIfOperational" SG_ 1409 SensorF_OD_TelemetryCommands 1;
BA_ "CANzero_SDO_AccessIfOperational" SG_ 1409 SensorF_OD_samplingInterval 1;
BA_ "GenSigStartValue" SG_ 1409 SensorF_OD_samplingInterval 1000.0;
BA_ "CANzero_SDO_Default" SG_ 1409 SensorF_OD_samplingInterval 10;
BA_ "CANzero_SDO_Group" SG_ 1409 SensorF_OD_CAN2_DelayedTxMessage "CAN";
BA_ "CANzero_SDO_AccessType" SG_ 1409 SensorF_OD_CAN2_DelayedTxMessage 1;
BA_ "CANzero_SDO_AccessIfOperational" SG_ 1409 SensorF_OD_CAN2_DelayedTxMessage 1;
BA_ "SystemSignalLongSymbol" SG_ 1409 SensorF_OD_CAN2_DelayedTxMessage "SensorF_OD_CAN2_DelayedTxMessages";
BA_ "CANzero_SDO_Group" SG_ 1409 SensorF_OD_CAN2_ErrorStatus "CAN";
BA_ "CANzero_SDO_AccessType" SG_ 1409 SensorF_OD_CAN2_ErrorStatus 1;
BA_ "CANzero_SDO_AccessIfOperational" SG_ 1409 SensorF_OD_CAN2_ErrorStatus 1;
BA_ "CANzero_SDO_Group" SG_ 1409 SensorF_OD_CAN2_DiscardedTxMessa "CAN";
BA_ "CANzero_SDO_AccessType" SG_ 1409 SensorF_OD_CAN2_DiscardedTxMessa 1;
BA_ "CANzero_SDO_AccessIfOperational" SG_ 1409 SensorF_OD_CAN2_DiscardedTxMessa 1;
BA_ "SystemSignalLongSymbol" SG_ 1409 SensorF_OD_CAN2_DiscardedTxMessa "SensorF_OD_CAN2_DiscardedTxMessages";
BA_ "CANzero_SDO_Group" SG_ 1409 SensorF_OD_CAN2_Status "CAN";
BA_ "CANzero_SDO_AccessType" SG_ 1409 SensorF_OD_CAN2_Status 1;
BA_ "CANzero_SDO_AccessIfOperational" SG_ 1409 SensorF_OD_CAN2_Status 1;
BA_ "CANzero_SDO_Group" SG_ 1409 SensorF_OD_CAN2_Baudrate "CAN";
BA_ "CANzero_SDO_AccessIfOperational" SG_ 1409 SensorF_OD_CAN2_Baudrate 1;
BA_ "GenSigStartValue" SG_ 1409 SensorF_OD_CAN2_Baudrate 1000.0;
BA_ "CANzero_SDO_Default" SG_ 1409 SensorF_OD_CAN2_Baudrate 1000;
BA_ "CANzero_SDO_Group" SG_ 1409 SensorF_OD_CAN2_autoErrorReset "CAN";
BA_ "CANzero_SDO_AccessIfOperational" SG_ 1409 SensorF_OD_CAN2_autoErrorReset 1;
BA_ "GenSigStartValue" SG_ 1409 SensorF_OD_CAN2_autoErrorReset 1.0;
BA_ "CANzero_SDO_Default" SG_ 1409 SensorF_OD_CAN2_autoErrorReset 1;
BA_ "CANzero_SDO_Group" SG_ 1409 SensorF_OD_CAN2_lastErrorCode "CAN";
BA_ "CANzero_SDO_AccessType" SG_ 1409 SensorF_OD_CAN2_lastErrorCode 1;
BA_ "CANzero_SDO_AccessIfOperational" SG_ 1409 SensorF_OD_CAN2_lastErrorCode 1;
BA_ "CANzero_SDO_Group" SG_ 1409 SensorF_OD_CAN2_RxErrCnt "CAN";
BA_ "CANzero_SDO_AccessType" SG_ 1409 SensorF_OD_CAN2_RxErrCnt 1;
BA_ "CANzero_SDO_AccessIfOperational" SG_ 1409 SensorF_OD_CAN2_RxErrCnt 1;
BA_ "CANzero_SDO_Group" SG_ 1409 SensorF_OD_CAN2_TxErrCnt "CAN";
BA_ "CANzero_SDO_AccessType" SG_ 1409 SensorF_OD_CAN2_TxErrCnt 1;
BA_ "CANzero_SDO_AccessIfOperational" SG_ 1409 SensorF_OD_CAN2_TxErrCnt 1;
BA_ "CANzero_SDO_Group" SG_ 1409 SensorF_OD_CAN1_DelayedTxMessage "CAN";
BA_ "CANzero_SDO_AccessType" SG_ 1409 SensorF_OD_CAN1_DelayedTxMessage 1;
BA_ "CANzero_SDO_AccessIfOperational" SG_ 1409 SensorF_OD_CAN1_DelayedTxMessage 1;
BA_ "SystemSignalLongSymbol" SG_ 1409 SensorF_OD_CAN1_DelayedTxMessage "SensorF_OD_CAN1_DelayedTxMessages";
BA_ "CANzero_SDO_Group" SG_ 1409 SensorF_OD_CAN1_ErrorStatus "CAN";
BA_ "CANzero_SDO_AccessType" SG_ 1409 SensorF_OD_CAN1_ErrorStatus 1;
BA_ "CANzero_SDO_AccessIfOperational" SG_ 1409 SensorF_OD_CAN1_ErrorStatus 1;
BA_ "CANzero_SDO_Group" SG_ 1409 SensorF_OD_CAN1_DiscardedTxMessa "CAN";
BA_ "CANzero_SDO_AccessType" SG_ 1409 SensorF_OD_CAN1_DiscardedTxMessa 1;
BA_ "CANzero_SDO_AccessIfOperational" SG_ 1409 SensorF_OD_CAN1_DiscardedTxMessa 1;
BA_ "SystemSignalLongSymbol" SG_ 1409 SensorF_OD_CAN1_DiscardedTxMessa "SensorF_OD_CAN1_DiscardedTxMessages";
BA_ "CANzero_SDO_Group" SG_ 1409 SensorF_OD_CAN1_Status "CAN";
BA_ "CANzero_SDO_AccessType" SG_ 1409 SensorF_OD_CAN1_Status 1;
BA_ "CANzero_SDO_AccessIfOperational" SG_ 1409 SensorF_OD_CAN1_Status 1;
BA_ "CANzero_SDO_Group" SG_ 1409 SensorF_OD_CAN1_Baudrate "CAN";
BA_ "CANzero_SDO_AccessIfOperational" SG_ 1409 SensorF_OD_CAN1_Baudrate 1;
BA_ "GenSigStartValue" SG_ 1409 SensorF_OD_CAN1_Baudrate 1000.0;
BA_ "CANzero_SDO_Default" SG_ 1409 SensorF_OD_CAN1_Baudrate 1000;
BA_ "CANzero_SDO_Group" SG_ 1409 SensorF_OD_CAN1_autoErrorReset "CAN";
BA_ "CANzero_SDO_AccessIfOperational" SG_ 1409 SensorF_OD_CAN1_autoErrorReset 1;
BA_ "GenSigStartValue" SG_ 1409 SensorF_OD_CAN1_autoErrorReset 1.0;
BA_ "CANzero_SDO_Default" SG_ 1409 SensorF_OD_CAN1_autoErrorReset 1;
BA_ "CANzero_SDO_Group" SG_ 1409 SensorF_OD_CAN1_lastErrorCode "CAN";
BA_ "CANzero_SDO_AccessType" SG_ 1409 SensorF_OD_CAN1_lastErrorCode 1;
BA_ "CANzero_SDO_AccessIfOperational" SG_ 1409 SensorF_OD_CAN1_lastErrorCode 1;
BA_ "CANzero_SDO_Group" SG_ 1409 SensorF_OD_CAN1_RxErrCnt "CAN";
BA_ "CANzero_SDO_AccessType" SG_ 1409 SensorF_OD_CAN1_RxErrCnt 1;
BA_ "CANzero_SDO_AccessIfOperational" SG_ 1409 SensorF_OD_CAN1_RxErrCnt 1;
BA_ "CANzero_SDO_Group" SG_ 1409 SensorF_OD_CAN1_TxErrCnt "CAN";
BA_ "CANzero_SDO_AccessType" SG_ 1409 SensorF_OD_CAN1_TxErrCnt 1;
BA_ "CANzero_SDO_AccessIfOperational" SG_ 1409 SensorF_OD_CAN1_TxErrCnt 1;
BA_ "CANzero_SDO_AccessType" SG_ 1409 SensorF_OD_BuildTime 1;
BA_ "CANzero_SDO_AccessIfOperational" SG_ 1409 SensorF_OD_BuildTime 1;
BA_ "CANzero_SDO_AccessType" SG_ 1409 SensorF_OD_BuildDate 1;
BA_ "CANzero_SDO_AccessIfOperational" SG_ 1409 SensorF_OD_BuildDate 1;
BA_ "CANzero_SDO_AccessType" SG_ 1409 SensorF_OD_ChipUID2 1;
BA_ "CANzero_SDO_AccessIfOperational" SG_ 1409 SensorF_OD_ChipUID2 1;
BA_ "CANzero_SDO_AccessType" SG_ 1409 SensorF_OD_ChipUID1 1;
BA_ "CANzero_SDO_AccessIfOperational" SG_ 1409 SensorF_OD_ChipUID1 1;
BA_ "CANzero_SDO_AccessType" SG_ 1409 SensorF_OD_SdcOut 1;
BA_ "CANzero_SDO_AccessIfOperational" SG_ 1409 SensorF_OD_SdcOut 1;
BA_ "CANzero_SDO_AccessType" SG_ 1409 SensorF_OD_SdcIn 1;
BA_ "CANzero_SDO_AccessIfOperational" SG_ 1409 SensorF_OD_SdcIn 1;
BA_ "CANzero_SDO_AccessType" SG_ 1409 SensorF_OD_runtime 1;
BA_ "CANzero_SDO_AccessIfOperational" SG_ 1409 SensorF_OD_runtime 1;
BA_ "CANzero_SDO_AccessType" SG_ 1409 SensorF_OD_InputVoltage 1;
BA_ "CANzero_SDO_AccessIfOperational" SG_ 1409 SensorF_OD_InputVoltage 1;
BA_ "CANzero_SDO_AccessType" SG_ 1409 SensorF_OD_BoardTemp 1;
BA_ "CANzero_SDO_AccessIfOperational" SG_ 1409 SensorF_OD_BoardTemp 1;
BA_ "GenSigStartValue" SG_ 1409 SensorF_OD_BoardTemp 3000.0;
BA_ "CANzero_SDO_AccessType" SG_ 1409 SensorF_OD_MemFree 1;
BA_ "CANzero_SDO_AccessIfOperational" SG_ 1409 SensorF_OD_MemFree 1;
BA_ "CANzero_SDO_AccessType" SG_ 1409 SensorF_OD_CpuUsage 1;
BA_ "CANzero_SDO_AccessIfOperational" SG_ 1409 SensorF_OD_CpuUsage 1;
BA_ "CANzero_SDO_AccessIfOperational" SG_ 1409 SensorF_OD_OdEntrySendInterval 1;
BA_ "GenSigStartValue" SG_ 1409 SensorF_OD_OdEntrySendInterval 50.0;
BA_ "CANzero_SDO_Default" SG_ 1409 SensorF_OD_OdEntrySendInterval 50;
BA_ "CANzero_SDO_AccessIfOperational" SG_ 1409 SensorF_OD_SendOdOnBootup 1;
BA_ "CANzero_SDO_AccessIfOperational" SG_ 1409 SensorF_OD_HeartbeatInterval 1;
BA_ "GenSigStartValue" SG_ 1409 SensorF_OD_HeartbeatInterval 250.0;
BA_ "CANzero_SDO_Default" SG_ 1409 SensorF_OD_HeartbeatInterval 250;
BA_ "CANzero_SDO_AccessType" SG_ 1409 SensorF_OD_DbcVersion 1;
BA_ "CANzero_SDO_AccessIfOperational" SG_ 1409 SensorF_OD_DbcVersion 1;
BA_ "CANzero_SDO_AccessType" SG_ 1409 SensorF_OD_StackVersion 1;
BA_ "CANzero_SDO_AccessIfOperational" SG_ 1409 SensorF_OD_StackVersion 1;
BA_ "CANzero_SDO_AccessType" SG_ 1409 SensorF_OD_ProtocolVersion 1;
BA_ "CANzero_SDO_AccessIfOperational" SG_ 1409 SensorF_OD_ProtocolVersion 1;
BA_ "GenSigStartValue" SG_ 1409 SensorF_OD_ProtocolVersion 1.0;
BA_ "CANzero_SDO_Default" SG_ 1409 SensorF_OD_ProtocolVersion 1;
BA_ "CANzero_SDO_AccessType" SG_ 1409 SensorF_OD_NodeStatus 1;
BA_ "CANzero_SDO_AccessIfOperational" SG_ 1409 SensorF_OD_NodeStatus 1;
BA_ "CANzero_SDO_AccessType" SG_ 1409 SensorF_OD_NodeID 1;
BA_ "CANzero_SDO_AccessIfOperational" SG_ 1409 SensorF_OD_NodeID 1;
BA_ "CANzero_SDO_AccessType" SG_ 1473 SensorF_OD_TitanCell12Voltage 1;
BA_ "CANzero_SDO_AccessIfOperational" SG_ 1473 SensorF_OD_TitanCell12Voltage 1;
BA_ "CANzero_SDO_AccessType" SG_ 1473 SensorF_OD_TitanCell11Voltage 1;
BA_ "CANzero_SDO_AccessIfOperational" SG_ 1473 SensorF_OD_TitanCell11Voltage 1;
BA_ "CANzero_SDO_AccessType" SG_ 1473 SensorF_OD_TitanCell10Voltage 1;
BA_ "CANzero_SDO_AccessIfOperational" SG_ 1473 SensorF_OD_TitanCell10Voltage 1;
BA_ "CANzero_SDO_AccessType" SG_ 1473 SensorF_OD_TitanCell9Voltage 1;
BA_ "CANzero_SDO_AccessIfOperational" SG_ 1473 SensorF_OD_TitanCell9Voltage 1;
BA_ "CANzero_SDO_AccessType" SG_ 1473 SensorF_OD_TitanCell8Voltage 1;
BA_ "CANzero_SDO_AccessIfOperational" SG_ 1473 SensorF_OD_TitanCell8Voltage 1;
BA_ "CANzero_SDO_AccessType" SG_ 1473 SensorF_OD_TitanCell7Voltage 1;
BA_ "CANzero_SDO_AccessIfOperational" SG_ 1473 SensorF_OD_TitanCell7Voltage 1;
BA_ "CANzero_SDO_AccessType" SG_ 1473 SensorF_OD_TitanCell6Voltage 1;
BA_ "CANzero_SDO_AccessIfOperational" SG_ 1473 SensorF_OD_TitanCell6Voltage 1;
BA_ "CANzero_SDO_AccessType" SG_ 1473 SensorF_OD_TitanCell5Voltage 1;
BA_ "CANzero_SDO_AccessIfOperational" SG_ 1473 SensorF_OD_TitanCell5Voltage 1;
BA_ "CANzero_SDO_AccessType" SG_ 1473 SensorF_OD_TitanCell4Voltage 1;
BA_ "CANzero_SDO_AccessIfOperational" SG_ 1473 SensorF_OD_TitanCell4Voltage 1;
BA_ "CANzero_SDO_AccessType" SG_ 1473 SensorF_OD_TitanCell3Voltage 1;
BA_ "CANzero_SDO_AccessIfOperational" SG_ 1473 SensorF_OD_TitanCell3Voltage 1;
BA_ "CANzero_SDO_AccessType" SG_ 1473 SensorF_OD_TitanCell2Voltage 1;
BA_ "CANzero_SDO_AccessIfOperational" SG_ 1473 SensorF_OD_TitanCell2Voltage 1;
BA_ "CANzero_SDO_AccessType" SG_ 1473 SensorF_OD_TitanCell1Voltage 1;
BA_ "CANzero_SDO_AccessIfOperational" SG_ 1473 SensorF_OD_TitanCell1Voltage 1;
BA_ "CANzero_SDO_AccessType" SG_ 1473 SensorF_OD_TitanHealthStatus 1;
BA_ "CANzero_SDO_AccessIfOperational" SG_ 1473 SensorF_OD_TitanHealthStatus 1;
BA_ "CANzero_SDO_AccessType" SG_ 1473 SensorF_OD_TitanLifeCycle 1;
BA_ "CANzero_SDO_AccessIfOperational" SG_ 1473 SensorF_OD_TitanLifeCycle 1;
BA_ "CANzero_SDO_AccessType" SG_ 1473 SensorF_OD_TitanRemainingCa_0000 1;
BA_ "CANzero_SDO_AccessIfOperational" SG_ 1473 SensorF_OD_TitanRemainingCa_0000 1;
BA_ "SystemSignalLongSymbol" SG_ 1473 SensorF_OD_TitanRemainingCa_0000 "SensorF_OD_TitanRemainingCapacity";
BA_ "CANzero_SDO_AccessType" SG_ 1473 SensorF_OD_TitanCurrent 1;
BA_ "CANzero_SDO_AccessIfOperational" SG_ 1473 SensorF_OD_TitanCurrent 1;
BA_ "GenSigStartValue" SG_ 1473 SensorF_OD_TitanCurrent 10000.0;
BA_ "CANzero_SDO_AccessType" SG_ 1473 SensorF_OD_TitanVoltage 1;
BA_ "CANzero_SDO_AccessIfOperational" SG_ 1473 SensorF_OD_TitanVoltage 1;
BA_ "CANzero_SDO_AccessType" SG_ 1473 SensorF_OD_TitanTemperature 1;
BA_ "CANzero_SDO_AccessIfOperational" SG_ 1473 SensorF_OD_TitanTemperature 1;
BA_ "CANzero_SDO_AccessType" SG_ 1473 SensorF_OD_HyperionCell12Voltage 1;
BA_ "CANzero_SDO_AccessIfOperational" SG_ 1473 SensorF_OD_HyperionCell12Voltage 1;
BA_ "CANzero_SDO_AccessType" SG_ 1473 SensorF_OD_HyperionCell11Voltage 1;
BA_ "CANzero_SDO_AccessIfOperational" SG_ 1473 SensorF_OD_HyperionCell11Voltage 1;
BA_ "CANzero_SDO_AccessType" SG_ 1473 SensorF_OD_HyperionCell10Voltage 1;
BA_ "CANzero_SDO_AccessIfOperational" SG_ 1473 SensorF_OD_HyperionCell10Voltage 1;
BA_ "CANzero_SDO_AccessType" SG_ 1473 SensorF_OD_HyperionCell9Voltage 1;
BA_ "CANzero_SDO_AccessIfOperational" SG_ 1473 SensorF_OD_HyperionCell9Voltage 1;
BA_ "CANzero_SDO_AccessType" SG_ 1473 SensorF_OD_HyperionCell8Voltage 1;
BA_ "CANzero_SDO_AccessIfOperational" SG_ 1473 SensorF_OD_HyperionCell8Voltage 1;
BA_ "CANzero_SDO_AccessType" SG_ 1473 SensorF_OD_HyperionCell7Voltage 1;
BA_ "CANzero_SDO_AccessIfOperational" SG_ 1473 SensorF_OD_HyperionCell7Voltage 1;
BA_ "CANzero_SDO_AccessType" SG_ 1473 SensorF_OD_HyperionCell6Voltage 1;
BA_ "CANzero_SDO_AccessIfOperational" SG_ 1473 SensorF_OD_HyperionCell6Voltage 1;
BA_ "CANzero_SDO_AccessType" SG_ 1473 SensorF_OD_HyperionCell5Voltage 1;
BA_ "CANzero_SDO_AccessIfOperational" SG_ 1473 SensorF_OD_HyperionCell5Voltage 1;
BA_ "CANzero_SDO_AccessType" SG_ 1473 SensorF_OD_HyperionCell4Voltage 1;
BA_ "CANzero_SDO_AccessIfOperational" SG_ 1473 SensorF_OD_HyperionCell4Voltage 1;
BA_ "CANzero_SDO_AccessType" SG_ 1473 SensorF_OD_HyperionCell3Voltage 1;
BA_ "CANzero_SDO_AccessIfOperational" SG_ 1473 SensorF_OD_HyperionCell3Voltage 1;
BA_ "CANzero_SDO_AccessType" SG_ 1473 SensorF_OD_HyperionCell2Voltage 1;
BA_ "CANzero_SDO_AccessIfOperational" SG_ 1473 SensorF_OD_HyperionCell2Voltage 1;
BA_ "CANzero_SDO_AccessType" SG_ 1473 SensorF_OD_HyperionCell1Voltage 1;
BA_ "CANzero_SDO_AccessIfOperational" SG_ 1473 SensorF_OD_HyperionCell1Voltage 1;
BA_ "CANzero_SDO_AccessIfOperational" SG_ 1473 SensorF_OD_HyperionHealthStatus 1;
BA_ "CANzero_SDO_AccessType" SG_ 1473 SensorF_OD_HyperionLifeCycle 1;
BA_ "CANzero_SDO_AccessIfOperational" SG_ 1473 SensorF_OD_HyperionLifeCycle 1;
BA_ "CANzero_SDO_AccessType" SG_ 1473 SensorF_OD_HyperionRemainin_0000 1;
BA_ "CANzero_SDO_AccessIfOperational" SG_ 1473 SensorF_OD_HyperionRemainin_0000 1;
BA_ "SystemSignalLongSymbol" SG_ 1473 SensorF_OD_HyperionRemainin_0000 "SensorF_OD_HyperionRemainingCapacity";
BA_ "CANzero_SDO_AccessType" SG_ 1473 SensorF_OD_HyperionCurrent 1;
BA_ "CANzero_SDO_AccessIfOperational" SG_ 1473 SensorF_OD_HyperionCurrent 1;
BA_ "GenSigStartValue" SG_ 1473 SensorF_OD_HyperionCurrent 10000.0;
BA_ "CANzero_SDO_AccessType" SG_ 1473 SensorF_OD_HyperionVoltage 1;
BA_ "CANzero_SDO_AccessIfOperational" SG_ 1473 SensorF_OD_HyperionVoltage 1;
BA_ "CANzero_SDO_AccessType" SG_ 1473 SensorF_OD_HyperionTemperature 1;
BA_ "CANzero_SDO_AccessIfOperational" SG_ 1473 SensorF_OD_HyperionTemperature 1;
BA_ "CANzero_SDO_AccessType" SG_ 1473 SensorF_OD_SetReset 2;
BA_ "CANzero_SDO_AccessIfOperational" SG_ 1473 SensorF_OD_SetReset 1;
BA_ "CANzero_SDO_AccessType" SG_ 1473 SensorF_OD_Velocity 1;
BA_ "CANzero_SDO_AccessIfOperational" SG_ 1473 SensorF_OD_Velocity 1;
BA_ "GenSigStartValue" SG_ 1473 SensorF_OD_Velocity 10000.0;
BA_ "CANzero_SDO_AccessType" SG_ 1473 SensorF_OD_Position 1;
BA_ "CANzero_SDO_AccessIfOperational" SG_ 1473 SensorF_OD_Position 1;
BA_ "GenSigStartValue" SG_ 1473 SensorF_OD_Position 10000.0;
BA_ "CANzero_SDO_AccessType" SG_ 1473 SensorF_OD_StripeCount 1;
BA_ "CANzero_SDO_AccessIfOperational" SG_ 1473 SensorF_OD_StripeCount 1;
BA_ "CANzero_SDO_AccessIfOperational" SG_ 1473 SensorF_OD_MdbState 1;
BA_ "CANzero_SDO_AccessType" SG_ 1473 SensorF_OD_Magnet_6_Temperature 1;
BA_ "CANzero_SDO_AccessIfOperational" SG_ 1473 SensorF_OD_Magnet_6_Temperature 1;
BA_ "GenSigStartValue" SG_ 1473 SensorF_OD_Magnet_6_Temperature 11000.0;
BA_ "CANzero_SDO_Default" SG_ 1473 SensorF_OD_Magnet_6_Temperature 10;
BA_ "CANzero_SDO_AccessType" SG_ 1473 SensorF_OD_Magnet_5_Temperature 1;
BA_ "CANzero_SDO_AccessIfOperational" SG_ 1473 SensorF_OD_Magnet_5_Temperature 1;
BA_ "GenSigStartValue" SG_ 1473 SensorF_OD_Magnet_5_Temperature 11000.0;
BA_ "CANzero_SDO_Default" SG_ 1473 SensorF_OD_Magnet_5_Temperature 10;
BA_ "CANzero_SDO_AccessType" SG_ 1473 SensorF_OD_Magnet_4_Temperature 1;
BA_ "CANzero_SDO_AccessIfOperational" SG_ 1473 SensorF_OD_Magnet_4_Temperature 1;
BA_ "GenSigStartValue" SG_ 1473 SensorF_OD_Magnet_4_Temperature 11000.0;
BA_ "CANzero_SDO_Default" SG_ 1473 SensorF_OD_Magnet_4_Temperature 10;
BA_ "CANzero_SDO_AccessType" SG_ 1473 SensorF_OD_Magnet_3_Temperature 1;
BA_ "CANzero_SDO_AccessIfOperational" SG_ 1473 SensorF_OD_Magnet_3_Temperature 1;
BA_ "GenSigStartValue" SG_ 1473 SensorF_OD_Magnet_3_Temperature 11000.0;
BA_ "CANzero_SDO_Default" SG_ 1473 SensorF_OD_Magnet_3_Temperature 10;
BA_ "CANzero_SDO_AccessType" SG_ 1473 SensorF_OD_Magnet_2_Temperature 1;
BA_ "CANzero_SDO_AccessIfOperational" SG_ 1473 SensorF_OD_Magnet_2_Temperature 1;
BA_ "GenSigStartValue" SG_ 1473 SensorF_OD_Magnet_2_Temperature 11000.0;
BA_ "CANzero_SDO_Default" SG_ 1473 SensorF_OD_Magnet_2_Temperature 10;
BA_ "CANzero_SDO_AccessType" SG_ 1473 SensorF_OD_Magnet_1_Temperature 1;
BA_ "CANzero_SDO_AccessIfOperational" SG_ 1473 SensorF_OD_Magnet_1_Temperature 1;
BA_ "GenSigStartValue" SG_ 1473 SensorF_OD_Magnet_1_Temperature 11000.0;
BA_ "CANzero_SDO_Default" SG_ 1473 SensorF_OD_Magnet_1_Temperature 10;
BA_ "CANzero_SDO_AccessType" SG_ 1473 SensorF_OD_ReservoirTemperature 1;
BA_ "CANzero_SDO_AccessIfOperational" SG_ 1473 SensorF_OD_ReservoirTemperature 1;
BA_ "GenSigStartValue" SG_ 1473 SensorF_OD_ReservoirTemperature 18000.0;
BA_ "CANzero_SDO_Default" SG_ 1473 SensorF_OD_ReservoirTemperature 80;
BA_ "CANzero_SDO_AccessType" SG_ 1473 SensorF_OD_CoolingPressure 1;
BA_ "CANzero_SDO_AccessIfOperational" SG_ 1473 SensorF_OD_CoolingPressure 1;
BA_ "GenSigStartValue" SG_ 1473 SensorF_OD_CoolingPressure 9810.0;
BA_ "CANzero_SDO_Default" SG_ 1473 SensorF_OD_CoolingPressure -1.9;
BA_ "CANzero_SDO_AccessType" SG_ 1473 SensorF_OD_IMU_GyroZ 1;
BA_ "CANzero_SDO_AccessIfOperational" SG_ 1473 SensorF_OD_IMU_GyroZ 1;
BA_ "GenSigStartValue" SG_ 1473 SensorF_OD_IMU_GyroZ 10000.0;
BA_ "CANzero_SDO_AccessType" SG_ 1473 SensorF_OD_IMU_GyroY 1;
BA_ "CANzero_SDO_AccessIfOperational" SG_ 1473 SensorF_OD_IMU_GyroY 1;
BA_ "GenSigStartValue" SG_ 1473 SensorF_OD_IMU_GyroY 10000.0;
BA_ "CANzero_SDO_AccessType" SG_ 1473 SensorF_OD_IMU_GyroX 1;
BA_ "CANzero_SDO_AccessIfOperational" SG_ 1473 SensorF_OD_IMU_GyroX 1;
BA_ "GenSigStartValue" SG_ 1473 SensorF_OD_IMU_GyroX 10000.0;
BA_ "CANzero_SDO_AccessType" SG_ 1473 SensorF_OD_IMU_AccelZ 1;
BA_ "CANzero_SDO_AccessIfOperational" SG_ 1473 SensorF_OD_IMU_AccelZ 1;
BA_ "GenSigStartValue" SG_ 1473 SensorF_OD_IMU_AccelZ 10000.0;
BA_ "CANzero_SDO_AccessType" SG_ 1473 SensorF_OD_IMU_AccelY 1;
BA_ "CANzero_SDO_AccessIfOperational" SG_ 1473 SensorF_OD_IMU_AccelY 1;
BA_ "GenSigStartValue" SG_ 1473 SensorF_OD_IMU_AccelY 10000.0;
BA_ "CANzero_SDO_AccessType" SG_ 1473 SensorF_OD_IMU_AccelX 1;
BA_ "CANzero_SDO_AccessIfOperational" SG_ 1473 SensorF_OD_IMU_AccelX 1;
BA_ "GenSigStartValue" SG_ 1473 SensorF_OD_IMU_AccelX 10000.0;
BA_ "CANzero_SDO_AccessType" SG_ 1473 SensorF_OD_IMU3_Temperature 1;
BA_ "CANzero_SDO_AccessIfOperational" SG_ 1473 SensorF_OD_IMU3_Temperature 1;
BA_ "GenSigStartValue" SG_ 1473 SensorF_OD_IMU3_Temperature 10000.0;
BA_ "CANzero_SDO_AccessType" SG_ 1473 SensorF_OD_IMU2_Temperature 1;
BA_ "CANzero_SDO_AccessIfOperational" SG_ 1473 SensorF_OD_IMU2_Temperature 1;
BA_ "GenSigStartValue" SG_ 1473 SensorF_OD_IMU2_Temperature 10000.0;
BA_ "CANzero_SDO_AccessType" SG_ 1473 SensorF_OD_IMU1_Temperature 1;
BA_ "CANzero_SDO_AccessIfOperational" SG_ 1473 SensorF_OD_IMU1_Temperature 1;
BA_ "GenSigStartValue" SG_ 1473 SensorF_OD_IMU1_Temperature 10000.0;
BA_ "CANzero_SDO_AccessType" SG_ 1473 SensorF_OD_IMU_number 1;
BA_ "CANzero_SDO_AccessIfOperational" SG_ 1473 SensorF_OD_IMU_number 1;
BA_ "CANzero_SDO_AccessType" SG_ 1473 SensorF_OD_EncoderResetPosition 2;
BA_ "CANzero_SDO_AccessIfOperational" SG_ 1473 SensorF_OD_EncoderResetPosition 1;
BA_ "CANzero_SDO_AccessIfOperational" SG_ 1473 SensorF_OD_EncoderWheelDiameter 1;
BA_ "GenSigStartValue" SG_ 1473 SensorF_OD_EncoderWheelDiameter 15000.0;
BA_ "CANzero_SDO_Default" SG_ 1473 SensorF_OD_EncoderWheelDiameter 75;
BA_ "CANzero_SDO_AccessIfOperational" SG_ 1473 SensorF_OD_HVBatteryMode 1;
BA_ "CANzero_SDO_AccessIfOperational" SG_ 1473 SensorF_OD_StateMachineActivate 1;
BA_ "CANzero_SDO_AccessIfOperational" SG_ 1473 SensorF_OD_StateMachineInterval 1;
BA_ "GenSigStartValue" SG_ 1473 SensorF_OD_StateMachineInterval 10.0;
BA_ "CANzero_SDO_Default" SG_ 1473 SensorF_OD_StateMachineInterval 10;
BA_ "CANzero_SDO_AccessIfOperational" SG_ 1473 SensorF_OD_TelemetryCommands 1;
BA_ "CANzero_SDO_AccessIfOperational" SG_ 1473 SensorF_OD_samplingInterval 1;
BA_ "GenSigStartValue" SG_ 1473 SensorF_OD_samplingInterval 1000.0;
BA_ "CANzero_SDO_Default" SG_ 1473 SensorF_OD_samplingInterval 10;
BA_ "CANzero_SDO_Group" SG_ 1473 SensorF_OD_CAN2_DelayedTxMe_0000 "CAN";
BA_ "CANzero_SDO_AccessType" SG_ 1473 SensorF_OD_CAN2_DelayedTxMe_0000 1;
BA_ "CANzero_SDO_AccessIfOperational" SG_ 1473 SensorF_OD_CAN2_DelayedTxMe_0000 1;
BA_ "SystemSignalLongSymbol" SG_ 1473 SensorF_OD_CAN2_DelayedTxMe_0000 "SensorF_OD_CAN2_DelayedTxMessages";
BA_ "CANzero_SDO_Group" SG_ 1473 SensorF_OD_CAN2_ErrorStatus "CAN";
BA_ "CANzero_SDO_AccessType" SG_ 1473 SensorF_OD_CAN2_ErrorStatus 1;
BA_ "CANzero_SDO_AccessIfOperational" SG_ 1473 SensorF_OD_CAN2_ErrorStatus 1;
BA_ "CANzero_SDO_Group" SG_ 1473 SensorF_OD_CAN2_DiscardedTx_0000 "CAN";
BA_ "CANzero_SDO_AccessType" SG_ 1473 SensorF_OD_CAN2_DiscardedTx_0000 1;
BA_ "CANzero_SDO_AccessIfOperational" SG_ 1473 SensorF_OD_CAN2_DiscardedTx_0000 1;
BA_ "SystemSignalLongSymbol" SG_ 1473 SensorF_OD_CAN2_DiscardedTx_0000 "SensorF_OD_CAN2_DiscardedTxMessages";
BA_ "CANzero_SDO_Group" SG_ 1473 SensorF_OD_CAN2_Status "CAN";
BA_ "CANzero_SDO_AccessType" SG_ 1473 SensorF_OD_CAN2_Status 1;
BA_ "CANzero_SDO_AccessIfOperational" SG_ 1473 SensorF_OD_CAN2_Status 1;
BA_ "CANzero_SDO_Group" SG_ 1473 SensorF_OD_CAN2_Baudrate "CAN";
BA_ "CANzero_SDO_AccessIfOperational" SG_ 1473 SensorF_OD_CAN2_Baudrate 1;
BA_ "GenSigStartValue" SG_ 1473 SensorF_OD_CAN2_Baudrate 1000.0;
BA_ "CANzero_SDO_Default" SG_ 1473 SensorF_OD_CAN2_Baudrate 1000;
BA_ "CANzero_SDO_Group" SG_ 1473 SensorF_OD_CAN2_autoErrorReset "CAN";
BA_ "CANzero_SDO_AccessIfOperational" SG_ 1473 SensorF_OD_CAN2_autoErrorReset 1;
BA_ "GenSigStartValue" SG_ 1473 SensorF_OD_CAN2_autoErrorReset 1.0;
BA_ "CANzero_SDO_Default" SG_ 1473 SensorF_OD_CAN2_autoErrorReset 1;
BA_ "CANzero_SDO_Group" SG_ 1473 SensorF_OD_CAN2_lastErrorCode "CAN";
BA_ "CANzero_SDO_AccessType" SG_ 1473 SensorF_OD_CAN2_lastErrorCode 1;
BA_ "CANzero_SDO_AccessIfOperational" SG_ 1473 SensorF_OD_CAN2_lastErrorCode 1;
BA_ "CANzero_SDO_Group" SG_ 1473 SensorF_OD_CAN2_RxErrCnt "CAN";
BA_ "CANzero_SDO_AccessType" SG_ 1473 SensorF_OD_CAN2_RxErrCnt 1;
BA_ "CANzero_SDO_AccessIfOperational" SG_ 1473 SensorF_OD_CAN2_RxErrCnt 1;
BA_ "CANzero_SDO_Group" SG_ 1473 SensorF_OD_CAN2_TxErrCnt "CAN";
BA_ "CANzero_SDO_AccessType" SG_ 1473 SensorF_OD_CAN2_TxErrCnt 1;
BA_ "CANzero_SDO_AccessIfOperational" SG_ 1473 SensorF_OD_CAN2_TxErrCnt 1;
BA_ "CANzero_SDO_Group" SG_ 1473 SensorF_OD_CAN1_DelayedTxMe_0000 "CAN";
BA_ "CANzero_SDO_AccessType" SG_ 1473 SensorF_OD_CAN1_DelayedTxMe_0000 1;
BA_ "CANzero_SDO_AccessIfOperational" SG_ 1473 SensorF_OD_CAN1_DelayedTxMe_0000 1;
BA_ "SystemSignalLongSymbol" SG_ 1473 SensorF_OD_CAN1_DelayedTxMe_0000 "SensorF_OD_CAN1_DelayedTxMessages";
BA_ "CANzero_SDO_Group" SG_ 1473 SensorF_OD_CAN1_ErrorStatus "CAN";
BA_ "CANzero_SDO_AccessType" SG_ 1473 SensorF_OD_CAN1_ErrorStatus 1;
BA_ "CANzero_SDO_AccessIfOperational" SG_ 1473 SensorF_OD_CAN1_ErrorStatus 1;
BA_ "CANzero_SDO_Group" SG_ 1473 SensorF_OD_CAN1_DiscardedTx_0000 "CAN";
BA_ "CANzero_SDO_AccessType" SG_ 1473 SensorF_OD_CAN1_DiscardedTx_0000 1;
BA_ "CANzero_SDO_AccessIfOperational" SG_ 1473 SensorF_OD_CAN1_DiscardedTx_0000 1;
BA_ "SystemSignalLongSymbol" SG_ 1473 SensorF_OD_CAN1_DiscardedTx_0000 "SensorF_OD_CAN1_DiscardedTxMessages";
BA_ "CANzero_SDO_Group" SG_ 1473 SensorF_OD_CAN1_Status "CAN";
BA_ "CANzero_SDO_AccessType" SG_ 1473 SensorF_OD_CAN1_Status 1;
BA_ "CANzero_SDO_AccessIfOperational" SG_ 1473 SensorF_OD_CAN1_Status 1;
BA_ "CANzero_SDO_Group" SG_ 1473 SensorF_OD_CAN1_Baudrate "CAN";
BA_ "CANzero_SDO_AccessIfOperational" SG_ 1473 SensorF_OD_CAN1_Baudrate 1;
BA_ "GenSigStartValue" SG_ 1473 SensorF_OD_CAN1_Baudrate 1000.0;
BA_ "CANzero_SDO_Default" SG_ 1473 SensorF_OD_CAN1_Baudrate 1000;
BA_ "CANzero_SDO_Group" SG_ 1473 SensorF_OD_CAN1_autoErrorReset "CAN";
BA_ "CANzero_SDO_AccessIfOperational" SG_ 1473 SensorF_OD_CAN1_autoErrorReset 1;
BA_ "GenSigStartValue" SG_ 1473 SensorF_OD_CAN1_autoErrorReset 1.0;
BA_ "CANzero_SDO_Default" SG_ 1473 SensorF_OD_CAN1_autoErrorReset 1;
BA_ "CANzero_SDO_Group" SG_ 1473 SensorF_OD_CAN1_lastErrorCode "CAN";
BA_ "CANzero_SDO_AccessType" SG_ 1473 SensorF_OD_CAN1_lastErrorCode 1;
BA_ "CANzero_SDO_AccessIfOperational" SG_ 1473 SensorF_OD_CAN1_lastErrorCode 1;
BA_ "CANzero_SDO_Group" SG_ 1473 SensorF_OD_CAN1_RxErrCnt "CAN";
BA_ "CANzero_SDO_AccessType" SG_ 1473 SensorF_OD_CAN1_RxErrCnt 1;
BA_ "CANzero_SDO_AccessIfOperational" SG_ 1473 SensorF_OD_CAN1_RxErrCnt 1;
BA_ "CANzero_SDO_Group" SG_ 1473 SensorF_OD_CAN1_TxErrCnt "CAN";
BA_ "CANzero_SDO_AccessType" SG_ 1473 SensorF_OD_CAN1_TxErrCnt 1;
BA_ "CANzero_SDO_AccessIfOperational" SG_ 1473 SensorF_OD_CAN1_TxErrCnt 1;
BA_ "CANzero_SDO_AccessType" SG_ 1473 SensorF_OD_BuildTime 1;
BA_ "CANzero_SDO_AccessIfOperational" SG_ 1473 SensorF_OD_BuildTime 1;
BA_ "CANzero_SDO_AccessType" SG_ 1473 SensorF_OD_BuildDate 1;
BA_ "CANzero_SDO_AccessIfOperational" SG_ 1473 SensorF_OD_BuildDate 1;
BA_ "CANzero_SDO_AccessType" SG_ 1473 SensorF_OD_ChipUID2 1;
BA_ "CANzero_SDO_AccessIfOperational" SG_ 1473 SensorF_OD_ChipUID2 1;
BA_ "CANzero_SDO_AccessType" SG_ 1473 SensorF_OD_ChipUID1 1;
BA_ "CANzero_SDO_AccessIfOperational" SG_ 1473 SensorF_OD_ChipUID1 1;
BA_ "CANzero_SDO_AccessType" SG_ 1473 SensorF_OD_SdcOut 1;
BA_ "CANzero_SDO_AccessIfOperational" SG_ 1473 SensorF_OD_SdcOut 1;
BA_ "CANzero_SDO_AccessType" SG_ 1473 SensorF_OD_SdcIn 1;
BA_ "CANzero_SDO_AccessIfOperational" SG_ 1473 SensorF_OD_SdcIn 1;
BA_ "CANzero_SDO_AccessType" SG_ 1473 SensorF_OD_runtime 1;
BA_ "CANzero_SDO_AccessIfOperational" SG_ 1473 SensorF_OD_runtime 1;
BA_ "CANzero_SDO_AccessType" SG_ 1473 SensorF_OD_InputVoltage 1;
BA_ "CANzero_SDO_AccessIfOperational" SG_ 1473 SensorF_OD_InputVoltage 1;
BA_ "CANzero_SDO_AccessType" SG_ 1473 SensorF_OD_BoardTemp 1;
BA_ "CANzero_SDO_AccessIfOperational" SG_ 1473 SensorF_OD_BoardTemp 1;
BA_ "GenSigStartValue" SG_ 1473 SensorF_OD_BoardTemp 3000.0;
BA_ "CANzero_SDO_AccessType" SG_ 1473 SensorF_OD_MemFree 1;
BA_ "CANzero_SDO_AccessIfOperational" SG_ 1473 SensorF_OD_MemFree 1;
BA_ "CANzero_SDO_AccessType" SG_ 1473 SensorF_OD_CpuUsage 1;
BA_ "CANzero_SDO_AccessIfOperational" SG_ 1473 SensorF_OD_CpuUsage 1;
BA_ "CANzero_SDO_AccessIfOperational" SG_ 1473 SensorF_OD_OdEntrySendInterval 1;
BA_ "GenSigStartValue" SG_ 1473 SensorF_OD_OdEntrySendInterval 50.0;
BA_ "CANzero_SDO_Default" SG_ 1473 SensorF_OD_OdEntrySendInterval 50;
BA_ "CANzero_SDO_AccessIfOperational" SG_ 1473 SensorF_OD_SendOdOnBootup 1;
BA_ "CANzero_SDO_AccessIfOperational" SG_ 1473 SensorF_OD_HeartbeatInterval 1;
BA_ "GenSigStartValue" SG_ 1473 SensorF_OD_HeartbeatInterval 250.0;
BA_ "CANzero_SDO_Default" SG_ 1473 SensorF_OD_HeartbeatInterval 250;
BA_ "CANzero_SDO_AccessType" SG_ 1473 SensorF_OD_DbcVersion 1;
BA_ "CANzero_SDO_AccessIfOperational" SG_ 1473 SensorF_OD_DbcVersion 1;
BA_ "CANzero_SDO_AccessType" SG_ 1473 SensorF_OD_StackVersion 1;
BA_ "CANzero_SDO_AccessIfOperational" SG_ 1473 SensorF_OD_StackVersion 1;
BA_ "CANzero_SDO_AccessType" SG_ 1473 SensorF_OD_ProtocolVersion 1;
BA_ "CANzero_SDO_AccessIfOperational" SG_ 1473 SensorF_OD_ProtocolVersion 1;
BA_ "GenSigStartValue" SG_ 1473 SensorF_OD_ProtocolVersion 1.0;
BA_ "CANzero_SDO_Default" SG_ 1473 SensorF_OD_ProtocolVersion 1;
BA_ "CANzero_SDO_AccessType" SG_ 1473 SensorF_OD_NodeStatus 1;
BA_ "CANzero_SDO_AccessIfOperational" SG_ 1473 SensorF_OD_NodeStatus 1;
BA_ "CANzero_SDO_AccessType" SG_ 1473 SensorF_OD_NodeID 1;
BA_ "CANzero_SDO_AccessIfOperational" SG_ 1473 SensorF_OD_NodeID 1;
BA_ "SystemSignalLongSymbol" SG_ 130 SensorR_E11_scimoPEerror101overc "SensorR_E11_scimoPEerror101overcurrent";
BA_ "SystemSignalLongSymbol" SG_ 130 SensorR_E10_scimoPEerror103sumcu "SensorR_E10_scimoPEerror103sumcurrent";
BA_ "SystemSignalLongSymbol" SG_ 130 SensorR_E9_scimoPEerror102overcu "SensorR_E9_scimoPEerror102overcurrent";
BA_ "SystemSignalLongSymbol" SG_ 130 SensorR_E8_scimoPEerror024motTem "SensorR_E8_scimoPEerror024motTemp";
BA_ "SystemSignalLongSymbol" SG_ 130 SensorR_E6_scimoPEerror009Pulslo "SensorR_E6_scimoPEerror009Pulslock";
BA_ "SystemSignalLongSymbol" SG_ 130 SensorR_W8_outOfLimModelBoundari "SensorR_W8_outOfLimModelBoundaries";
BA_ "SystemSignalLongSymbol" SG_ 130 SensorR_W6_sciMoPEwarning104FETt "SensorR_W6_sciMoPEwarning104FETtemp";
BA_ "SystemSignalLongSymbol" SG_ 130 SensorR_W5_sciMoPEwarning069CPUt "SensorR_W5_sciMoPEwarning069CPUtemp";
BA_ "SystemSignalLongSymbol" SG_ 130 SensorR_W4_stateEstimationAccWar "SensorR_W4_stateEstimationAccWarning";
BA_ "SystemSignalLongSymbol" SG_ 130 SensorR_W3_stateEstimationPosWar "SensorR_W3_stateEstimationPosWarning";
BA_ "SystemSignalLongSymbol" SG_ 130 SensorR_W2_stateEstimationVelWar "SensorR_W2_stateEstimationVelWarning";
BA_ "GenSigStartValue" SG_ 1154 SensorR_LIMT_Coil_3 50;
BA_ "GenSigStartValue" SG_ 1154 SensorR_LIMT_Coil_2 50;
BA_ "GenSigStartValue" SG_ 1154 SensorR_LIMT_Coil_1 50;
VAL_ 57 CLU_TX_ActionRequest 4 "SET_AIRGAP" 3 "STOP" 2 "START" 1 "PREPARE" 0 "NONE" ;
VAL_ 592 CLU_LevitationState 7 "INCONSISTANT" 6 "ERROR" 5 "LEVI" 4 "LEVI_START" 3 "READY" 2 "PRECHARGE" 1 "IDLE" 0 "OFF" ;
VAL_ 293 MDB6_State 14 "ERROR_AIRGAP" 13 "ERROR_OVERTEMP" 12 "ERROR_OVERVOLT" 11 "ERROR_OVERCURRENT" 10 "ERROR" 20 "ERROR_CALCTIME" 19 "ERROR_CHIPTEMP" 18 "ERROR_CURRE_CALIB" 17 "ERROR_CAN" 16 "ERROR_AIRGAP_SEN" 7 "LEVI_UNSTABLE" 6 "LEVI_END" 5 "LEVI_RUN" 4 "LEVI_START" 3 "READY" 2 "PRECHARGE" 1 "IDLE" 0 "INIT" ;
VAL_ 288 MDB5_State 15 "ERROR_AIRGAP_SEN" 14 "ERROR_AIRGAP" 13 "ERROR_OVERTEMP" 12 "ERROR_OVERVOLT" 11 "ERROR_OVERCURRENT" 10 "ERROR" 19 "ERROR_CALCTIME" 18 "ERROR_CHIPTEMP" 17 "ERROR_CURRE_CALIB" 16 "ERROR_CAN" 7 "LEVI_UNSTABLE" 6 "LEVI_END" 5 "LEVI_RUN" 4 "LEVI_START" 3 "READY" 2 "PRECHARGE" 1 "IDLE" 0 "INIT" ;
VAL_ 277 MDB4_State 15 "ERROR_AIRGAP_SEN" 14 "ERROR_AIRGAP" 13 "ERROR_OVERTEMP" 12 "ERROR_OVERVOLT" 11 "ERROR_OVERCURRENT" 10 "ERROR" 19 "ERROR_CALCTIME" 18 "ERROR_CHIPTEMP" 17 "ERROR_CURRE_CALIB" 16 "ERROR_CAN" 7 "LEVI_UNSTABLE" 6 "LEVI_END" 5 "LEVI_RUN" 4 "LEVI_START" 3 "READY" 2 "PRECHARGE" 1 "IDLE" 0 "INIT" ;
VAL_ 272 MDB3_State 18 "ERROR_CHIPTEMP" 17 "ERROR_CURRE_CALIB" 16 "ERROR_CAN" 15 "ERROR_AIRGAP_SEN" 14 "ERROR_AIRGAP" 13 "ERROR_OVERTEMP" 12 "ERROR_OVERVOLT" 11 "ERROR_OVERCURRENT" 10 "ERROR" 19 "ERROR_CALCTIME" 7 "LEVI_UNSTABLE" 6 "LEVI_END" 5 "LEVI_RUN" 4 "LEVI_START" 3 "READY" 2 "PRECHARGE" 1 "IDLE" 0 "INIT" ;
VAL_ 261 MDB2_State 15 "ERROR_AIRGAP_SEN" 14 "ERROR_AIRGAP" 13 "ERROR_OVERTEMP" 12 "ERROR_OVERVOLT" 11 "ERROR_OVERCURRENT" 10 "ERROR" 19 "ERROR_CALCTIME" 18 "ERROR_CHIPTEMP" 17 "ERROR_CURRE_CALIB" 16 "ERROR_CAN" 7 "LEVI_UNSTABLE" 6 "LEVI_END" 5 "LEVI_RUN" 4 "LEVI_START" 3 "READY" 2 "PRECHARGE" 1 "IDLE" 0 "INIT" ;
VAL_ 256 MDB1_State 15 "ERROR_AIRGAP_SEN" 14 "ERROR_AIRGAP" 13 "ERROR_OVERTEMP" 12 "ERROR_OVERVOLT" 11 "ERROR_OVERCURRENT" 10 "ERROR" 19 "ERROR_CALCTIME" 18 "ERROR_CHIPTEMP" 17 "ERROR_CURRE_CALIB" 16 "ERROR_CAN" 7 "LEVI_UNSTABLE" 6 "LEVI_END" 5 "LEVI_RUN" 4 "LEVI_START" 3 "READY" 2 "PRECHARGE" 1 "IDLE" 0 "INIT" ;
VAL_ 2684354556 OpticalSensor_TX_LEDStatus 2 "FLASHING" 1 "ON" 0 "OFF" ;
VAL_ 2 CANzero_NMT_Node 0 "All" 1 "SensorF" 2 "SensorR" 17 "BrakeF" 18 "BrakeR" 26 "PDU" 10 "HVCU" 25 "HVTU" 34 "TelemetryNode" 33 "MDB1" 35 "MDB2" 39 "MDB3" 40 "MDB4" 41 "MDB5" 49 "MDB6" 50 "Track" 20 "CLU" ;
VAL_ 2 CANzero_NMT_State 1 "Start Remote Node" 2 "Stop Remote Node" 128 "Enter Pre-Operational" 129 "Reset" ;
VAL_ 129 SensorF_E14_fiducialHighOffset 0 "Ok" 1 "ERR" ;
VAL_ 129 SensorF_E13_encoderSpeedError 0 "Ok" 1 "ERR" ;
VAL_ 129 SensorF_E12_encoderError 0 "Ok" 1 "ERR" ;
VAL_ 129 SensorF_E10_TelemEmergency 0 "Ok" 1 "ERR" ;
VAL_ 129 SensorF_E9_SWError 0 "Ok" 1 "ERR" ;
VAL_ 129 SensorF_E8_NodeErrorFlag 0 "Ok" 1 "ERR" ;
VAL_ 129 SensorF_E7_TelemetryTimeout 0 "Ok" 1 "ERR" ;
VAL_ 129 SensorF_E6_SensorRTimeout 0 "Ok" 1 "ERR" ;
VAL_ 129 SensorF_E5_HVCUTimeout 0 "Ok" 1 "ERR" ;
VAL_ 129 SensorF_E4_PDUTimeout 0 "Ok" 1 "ERR" ;
VAL_ 129 SensorF_E3_BrakeRTimeout 0 "Ok" 1 "ERR" ;
VAL_ 129 SensorF_E2_BrakeFTimeout 0 "Ok" 1 "ERR" ;
VAL_ 129 SensorF_E1_StateMTransitionE 0 "Ok" 1 "ERR" ;
VAL_ 129 SensorF_E0_OtherError 0 "Ok" 1 "ERR" ;
VAL_ 129 SensorF_W2_encoderOORWarning 0 "Ok" 1 "WARN" ;
VAL_ 129 SensorF_W1_StateMTransitionW 0 "Ok" 1 "WARN" ;
VAL_ 129 SensorF_W0_OtherWarning 0 "Ok" 1 "WARN" ;
VAL_ 385 SensorF_TX_PodState 14 "Pod Startup" 13 "Pod Pushable" 12 "Pod Safe to Approch" 11 "Pod End Of Run" 10 "Pod Engage Brakes" 9 "Pod Rolling" 8 "Pod Stop Levitation" 7 "Pod Disengage Brakes" 6 "Pod Crusing" 5 "Pod Stable Levitation" 4 "Pod Start Levitation" 3 "Pod Ready to Launch" 2 "Pod Launch Preparation" 1 "Pod Idle" 0 "Pod Off" ;
VAL_ 513 SensorF_TX_PreopHVCUT 1 "Transition" 0 "No Transitions" ;
VAL_ 513 SensorF_TX_PreopPDUT 1 "Transition" 0 "No Transitions" ;
VAL_ 513 SensorF_TX_PreopBrakeRT 1 "Transition" 0 "No Transitions" ;
VAL_ 513 SensorF_TX_PreopBrakeFT 1 "Transition" 0 "No Transitions" ;
VAL_ 513 SensorF_TX_PreopSensorRT 1 "Transition" 0 "No Transitions" ;
VAL_ 513 SensorF_TX_EnableSensorRT 1 "Transition" 0 "No Transitions" ;
VAL_ 513 SensorF_TX_EnablePDUT 1 "Transition" 0 "No Transitions" ;
VAL_ 513 SensorF_TX_EnableHVCUT 1 "Transition" 0 "No Transitions" ;
VAL_ 513 SensorF_TX_EnableBrakeRT 1 "Transition" 0 "No Transitions" ;
VAL_ 513 SensorF_TX_EnableBrakeFT 1 "Transition" 0 "No Transitions" ;
VAL_ 513 SensorF_TX_SetHVTransition 1 "Transition" 0 "No Transitions" ;
VAL_ 513 SensorF_TX_PreopTransition 1 "Transition" 0 "No Transitions" ;
VAL_ 513 SensorF_TX_LaunchStartTransition 1 "Transition" 0 "No Transitions" ;
VAL_ 513 SensorF_TX_LaunchSetupTransition 1 "Transition" 0 "No Transitions" ;
VAL_ 513 SensorF_TX_HWEnableTransition 1 "Transition" 0 "No Transitions" ;
VAL_ 513 SensorF_TX_ErrorResetTransition 1 "Transition" 0 "No Transitions" ;
VAL_ 513 SensorF_TX_EnableTransition 1 "Transition" 0 "No Transitions" ;
VAL_ 513 SensorF_TX_BrakesTransition 1 "Transition" 0 "No Transitions" ;
VAL_ 1409 SensorF_OD_SetReset 0 "None" 1 "Reset" ;
VAL_ 1409 SensorF_OD_MdbState 0 "precharge" 1 "levitaiton" 2 "grounded" 3 "save_to_approch" 4 "precharge_done" 255 "inconsistant" ;
VAL_ 1409 SensorF_OD_EncoderResetPosition 0 "None" 1 "Reset" ;
VAL_ 1409 SensorF_OD_HVBatteryMode 0 "Discharging" 1 "Charging" ;
VAL_ 1409 SensorF_OD_StateMachineActivate 0 "Activate" 1 "Deactivate" ;
VAL_ 1409 SensorF_OD_TelemetryCommands 0 "None" 1 "Launch Preparation" 2 "HV Activation" 3 "Pushing Start" 4 "Pushing End" 5 "Launch Start" 6 "Launch Abort" 7 "Idle" 8 "Error Resolved" 9 "Emergency" ;
VAL_ 1409 SensorF_OD_CAN2_ErrorStatus 0 "Ok" 1 "Warn" 2 "Error Passive" 3 "Bus Off" ;
VAL_ 1409 SensorF_OD_CAN2_Status 0 "Reset" 1 "Ready" 2 "Listening" 3 "Sleep_Pending" 4 "Sleep_Active" 5 "ERROR" ;
VAL_ 1409 SensorF_OD_CAN2_autoErrorReset 0 "Disabled" 1 "Enabled" ;
VAL_ 1409 SensorF_OD_CAN2_lastErrorCode 0 "No Error" 1 "Stuff Error" 2 "Form Error" 3 "Ack Error" 4 "Bit recessive Error" 5 "Bit dominant Error" 6 "CRC Error" ;
VAL_ 1409 SensorF_OD_CAN1_ErrorStatus 0 "Ok" 1 "Warn" 2 "Error Passive" 3 "Bus Off" ;
VAL_ 1409 SensorF_OD_CAN1_Status 0 "Reset" 1 "Ready" 2 "Listening" 3 "Sleep_Pending" 4 "Sleep_Active" 5 "ERROR" ;
VAL_ 1409 SensorF_OD_CAN1_autoErrorReset 0 "Disabled" 1 "Enabled" ;
VAL_ 1409 SensorF_OD_CAN1_lastErrorCode 0 "No Error" 1 "Stuff Error" 2 "Form Error" 3 "Ack Error" 4 "Bit recessive Error" 5 "Bit dominant Error" 6 "CRC Error" ;
VAL_ 1409 SensorF_OD_SendOdOnBootup 0 "Disabled" 1 "Enabled" ;
VAL_ 1409 SensorF_OD_NodeStatus 0 "Bootup" 4 "Stopped" 5 "Operational" 127 "Pre-Operational" 128 "Reset" ;
VAL_ 1409 SensorF_SDO_RespCode 5 "ERR: Out of range" 4 "ERR: No access in this state" 3 "ERR: Read only object" 2 "ERR: Write only object" 1 "ERR: Non existing object" 0 "OK" ;
VAL_ 1409 SensorF_SDO_ID 0 "Reserved" 1 "NodeID" 2 "NodeStatus" 3 "ProtocolVersion" 4 "StackVersion" 5 "DbcVersion" 16 "HeartbeatInterval" 32 "SendOdOnBootup" 33 "OdEntrySendInterval" 1040 "CpuUsage" 1041 "MemFree" 1042 "BoardTemp" 1043 "InputVoltage" 1044 "runtime" 1045 "SdcIn" 1046 "SdcOut" 1056 "ChipUID1" 1057 "ChipUID2" 1072 "BuildDate" 1073 "BuildTime" 1104 "CAN1_TxErrCnt" 1105 "CAN1_RxErrCnt" 1106 "CAN1_lastErrorCode" 1107 "CAN1_autoErrorReset" 1108 "CAN1_Baudrate" 1110 "CAN1_Status" 1111 "CAN1_DiscardedTxMessages" 1112 "CAN1_ErrorStatus" 1113 "CAN1_DelayedTxMessages" 1120 "CAN2_TxErrCnt" 1121 "CAN2_RxErrCnt" 1122 "CAN2_lastErrorCode" 1123 "CAN2_autoErrorReset" 1124 "CAN2_Baudrate" 1126 "CAN2_Status" 1127 "CAN2_DiscardedTxMessages" 1128 "CAN2_ErrorStatus" 1129 "CAN2_DelayedTxMessages" 2048 "samplingInterval" 2304 "TelemetryCommands" 2305 "StateMachineInterval" 2306 "StateMachineActivate" 2307 "HVBatteryMode" 2308 "EncoderWheelDiameter" 2309 "EncoderResetPosition" 2592 "IMU_number" 2597 "IMU1_Temperature" 2598 "IMU2_Temperature" 2599 "IMU3_Temperature" 2600 "IMU_AccelX" 2601 "IMU_AccelY" 2608 "IMU_AccelZ" 2609 "IMU_GyroX" 2610 "IMU_GyroY" 2611 "IMU_GyroZ" 2816 "CoolingPressure" 2817 "ReservoirTemperature" 2818 "Magnet_1_Temperature" 2820 "Magnet_2_Temperature" 2821 "Magnet_3_Temperature" 2822 "Magnet_4_Temperature" 2823 "Magnet_5_Temperature" 2824 "Magnet_6_Temperature" 2832 "MdbState" 3072 "StripeCount" 3328 "Position" 3329 "Velocity" 2320 "SetReset" 512 "HyperionTemperature" 513 "HyperionVoltage" 514 "HyperionCurrent" 515 "HyperionRemainingCapacity" 516 "HyperionLifeCycle" 517 "HyperionHealthStatus" 518 "HyperionCell1Voltage" 519 "HyperionCell2Voltage" 520 "HyperionCell3Voltage" 521 "HyperionCell4Voltage" 522 "HyperionCell5Voltage" 523 "HyperionCell6Voltage" 524 "HyperionCell7Voltage" 525 "HyperionCell8Voltage" 526 "HyperionCell9Voltage" 527 "HyperionCell10Voltage" 528 "HyperionCell11Voltage" 529 "HyperionCell12Voltage" 768 "TitanTemperature" 769 "TitanVoltage" 770 "TitanCurrent" 771 "TitanRemainingCapacity" 772 "TitanLifeCycle" 773 "TitanHealthStatus" 774 "TitanCell1Voltage" 775 "TitanCell2Voltage" 776 "TitanCell3Voltage" 777 "TitanCell4Voltage" 778 "TitanCell5Voltage" 779 "TitanCell6Voltage" 780 "TitanCell7Voltage" 781 "TitanCell8Voltage" 782 "TitanCell9Voltage" 783 "TitanCell10Voltage" 784 "TitanCell11Voltage" 785 "TitanCell12Voltage" ;
VAL_ 1473 SensorF_OD_SetReset 0 "None" 1 "Reset" ;
VAL_ 1473 SensorF_OD_MdbState 0 "precharge" 1 "levitaiton" 2 "grounded" 3 "save_to_approch" 4 "precharge_done" 255 "inconsistant" ;
VAL_ 1473 SensorF_OD_EncoderResetPosition 0 "None" 1 "Reset" ;
VAL_ 1473 SensorF_OD_HVBatteryMode 0 "Discharging" 1 "Charging" ;
VAL_ 1473 SensorF_OD_StateMachineActivate 0 "Activate" 1 "Deactivate" ;
VAL_ 1473 SensorF_OD_TelemetryCommands 0 "None" 1 "Launch Preparation" 2 "HV Activation" 3 "Pushing Start" 4 "Pushing End" 5 "Launch Start" 6 "Launch Abort" 7 "Idle" 8 "Error Resolved" 9 "Emergency" ;
VAL_ 1473 SensorF_OD_CAN2_ErrorStatus 0 "Ok" 1 "Warn" 2 "Error Passive" 3 "Bus Off" ;
VAL_ 1473 SensorF_OD_CAN2_Status 0 "Reset" 1 "Ready" 2 "Listening" 3 "Sleep_Pending" 4 "Sleep_Active" 5 "ERROR" ;
VAL_ 1473 SensorF_OD_CAN2_autoErrorReset 0 "Disabled" 1 "Enabled" ;
VAL_ 1473 SensorF_OD_CAN2_lastErrorCode 0 "No Error" 1 "Stuff Error" 2 "Form Error" 3 "Ack Error" 4 "Bit recessive Error" 5 "Bit dominant Error" 6 "CRC Error" ;
VAL_ 1473 SensorF_OD_CAN1_ErrorStatus 0 "Ok" 1 "Warn" 2 "Error Passive" 3 "Bus Off" ;
VAL_ 1473 SensorF_OD_CAN1_Status 0 "Reset" 1 "Ready" 2 "Listening" 3 "Sleep_Pending" 4 "Sleep_Active" 5 "ERROR" ;
VAL_ 1473 SensorF_OD_CAN1_autoErrorReset 0 "Disabled" 1 "Enabled" ;
VAL_ 1473 SensorF_OD_CAN1_lastErrorCode 0 "No Error" 1 "Stuff Error" 2 "Form Error" 3 "Ack Error" 4 "Bit recessive Error" 5 "Bit dominant Error" 6 "CRC Error" ;
VAL_ 1473 SensorF_OD_SendOdOnBootup 0 "Disabled" 1 "Enabled" ;
VAL_ 1473 SensorF_OD_NodeStatus 0 "Bootup" 4 "Stopped" 5 "Operational" 127 "Pre-Operational" 128 "Reset" ;
VAL_ 1473 SensorF_SDO_ID 0 "Reserved" 1 "NodeID" 2 "NodeStatus" 3 "ProtocolVersion" 4 "StackVersion" 5 "DbcVersion" 16 "HeartbeatInterval" 32 "SendOdOnBootup" 33 "OdEntrySendInterval" 1040 "CpuUsage" 1041 "MemFree" 1042 "BoardTemp" 1043 "InputVoltage" 1044 "runtime" 1045 "SdcIn" 1046 "SdcOut" 1056 "ChipUID1" 1057 "ChipUID2" 1072 "BuildDate" 1073 "BuildTime" 1104 "CAN1_TxErrCnt" 1105 "CAN1_RxErrCnt" 1106 "CAN1_lastErrorCode" 1107 "CAN1_autoErrorReset" 1108 "CAN1_Baudrate" 1110 "CAN1_Status" 1111 "CAN1_DiscardedTxMessages" 1112 "CAN1_ErrorStatus" 1113 "CAN1_DelayedTxMessages" 1120 "CAN2_TxErrCnt" 1121 "CAN2_RxErrCnt" 1122 "CAN2_lastErrorCode" 1123 "CAN2_autoErrorReset" 1124 "CAN2_Baudrate" 1126 "CAN2_Status" 1127 "CAN2_DiscardedTxMessages" 1128 "CAN2_ErrorStatus" 1129 "CAN2_DelayedTxMessages" 2048 "samplingInterval" 2304 "TelemetryCommands" 2305 "StateMachineInterval" 2306 "StateMachineActivate" 2307 "HVBatteryMode" 2308 "EncoderWheelDiameter" 2309 "EncoderResetPosition" 2592 "IMU_number" 2597 "IMU1_Temperature" 2598 "IMU2_Temperature" 2599 "IMU3_Temperature" 2600 "IMU_AccelX" 2601 "IMU_AccelY" 2608 "IMU_AccelZ" 2609 "IMU_GyroX" 2610 "IMU_GyroY" 2611 "IMU_GyroZ" 2816 "CoolingPressure" 2817 "ReservoirTemperature" 2818 "Magnet_1_Temperature" 2820 "Magnet_2_Temperature" 2821 "Magnet_3_Temperature" 2822 "Magnet_4_Temperature" 2823 "Magnet_5_Temperature" 2824 "Magnet_6_Temperature" 2832 "MdbState" 3072 "StripeCount" 3328 "Position" 3329 "Velocity" 2320 "SetReset" 512 "HyperionTemperature" 513 "HyperionVoltage" 514 "HyperionCurrent" 515 "HyperionRemainingCapacity" 516 "HyperionLifeCycle" 517 "HyperionHealthStatus" 518 "HyperionCell1Voltage" 519 "HyperionCell2Voltage" 520 "HyperionCell3Voltage" 521 "HyperionCell4Voltage" 522 "HyperionCell5Voltage" 523 "HyperionCell6Voltage" 524 "HyperionCell7Voltage" 525 "HyperionCell8Voltage" 526 "HyperionCell9Voltage" 527 "HyperionCell10Voltage" 528 "HyperionCell11Voltage" 529 "HyperionCell12Voltage" 768 "TitanTemperature" 769 "TitanVoltage" 770 "TitanCurrent" 771 "TitanRemainingCapacity" 772 "TitanLifeCycle" 773 "TitanHealthStatus" 774 "TitanCell1Voltage" 775 "TitanCell2Voltage" 776 "TitanCell3Voltage" 777 "TitanCell4Voltage" 778 "TitanCell5Voltage" 779 "TitanCell6Voltage" 780 "TitanCell7Voltage" 781 "TitanCell8Voltage" 782 "TitanCell9Voltage" 783 "TitanCell10Voltage" 784 "TitanCell11Voltage" 785 "TitanCell12Voltage" ;
VAL_ 1537 SensorF_SDO_ID 0 "Reserved" 1 "NodeID" 2 "NodeStatus" 3 "ProtocolVersion" 4 "StackVersion" 5 "DbcVersion" 16 "HeartbeatInterval" 32 "SendOdOnBootup" 33 "OdEntrySendInterval" 1040 "CpuUsage" 1041 "MemFree" 1042 "BoardTemp" 1043 "InputVoltage" 1044 "runtime" 1045 "SdcIn" 1046 "SdcOut" 1056 "ChipUID1" 1057 "ChipUID2" 1072 "BuildDate" 1073 "BuildTime" 1104 "CAN1_TxErrCnt" 1105 "CAN1_RxErrCnt" 1106 "CAN1_lastErrorCode" 1107 "CAN1_autoErrorReset" 1108 "CAN1_Baudrate" 1110 "CAN1_Status" 1111 "CAN1_DiscardedTxMessages" 1112 "CAN1_ErrorStatus" 1113 "CAN1_DelayedTxMessages" 1120 "CAN2_TxErrCnt" 1121 "CAN2_RxErrCnt" 1122 "CAN2_lastErrorCode" 1123 "CAN2_autoErrorReset" 1124 "CAN2_Baudrate" 1126 "CAN2_Status" 1127 "CAN2_DiscardedTxMessages" 1128 "CAN2_ErrorStatus" 1129 "CAN2_DelayedTxMessages" 2048 "samplingInterval" 2304 "TelemetryCommands" 2305 "StateMachineInterval" 2306 "StateMachineActivate" 2307 "HVBatteryMode" 2308 "EncoderWheelDiameter" 2309 "EncoderResetPosition" 2592 "IMU_number" 2597 "IMU1_Temperature" 2598 "IMU2_Temperature" 2599 "IMU3_Temperature" 2600 "IMU_AccelX" 2601 "IMU_AccelY" 2608 "IMU_AccelZ" 2609 "IMU_GyroX" 2610 "IMU_GyroY" 2611 "IMU_GyroZ" 2816 "CoolingPressure" 2817 "ReservoirTemperature" 2818 "Magnet_1_Temperature" 2820 "Magnet_2_Temperature" 2821 "Magnet_3_Temperature" 2822 "Magnet_4_Temperature" 2823 "Magnet_5_Temperature" 2824 "Magnet_6_Temperature" 2832 "MdbState" 3072 "StripeCount" 3328 "Position" 3329 "Velocity" 2320 "SetReset" 512 "HyperionTemperature" 513 "HyperionVoltage" 514 "HyperionCurrent" 515 "HyperionRemainingCapacity" 516 "HyperionLifeCycle" 517 "HyperionHealthStatus" 518 "HyperionCell1Voltage" 519 "HyperionCell2Voltage" 520 "HyperionCell3Voltage" 521 "HyperionCell4Voltage" 522 "HyperionCell5Voltage" 523 "HyperionCell6Voltage" 524 "HyperionCell7Voltage" 525 "HyperionCell8Voltage" 526 "HyperionCell9Voltage" 527 "HyperionCell10Voltage" 528 "HyperionCell11Voltage" 529 "HyperionCell12Voltage" 768 "TitanTemperature" 769 "TitanVoltage" 770 "TitanCurrent" 771 "TitanRemainingCapacity" 772 "TitanLifeCycle" 773 "TitanHealthStatus" 774 "TitanCell1Voltage" 775 "TitanCell2Voltage" 776 "TitanCell3Voltage" 777 "TitanCell4Voltage" 778 "TitanCell5Voltage" 779 "TitanCell6Voltage" 780 "TitanCell7Voltage" 781 "TitanCell8Voltage" 782 "TitanCell9Voltage" 783 "TitanCell10Voltage" 784 "TitanCell11Voltage" 785 "TitanCell12Voltage" ;
VAL_ 1793 SensorF_NodeState 0 "Bootup" 4 "Stopped" 5 "Operational" 127 "Pre-Operational" ;
VAL_ 130 SensorR_E12_highLIMTemperature 0 "Ok" 1 "ERR" ;
VAL_ 130 SensorR_E11_scimoPEerror101overc 0 "Ok" 1 "ERR" ;
VAL_ 130 SensorR_E10_scimoPEerror103sumcu 0 "Ok" 1 "ERR" ;
VAL_ 130 SensorR_E9_scimoPEerror102overcu 0 "Ok" 1 "ERR" ;
VAL_ 130 SensorR_E8_scimoPEerror024motTem 0 "Ok" 1 "ERR" ;
VAL_ 130 SensorR_E7_scimoPEerror020uZKmin 0 "Ok" 1 "ERR" ;
VAL_ 130 SensorR_E6_scimoPEerror009Pulslo 0 "Ok" 1 "ERR" ;
VAL_ 130 SensorR_E5_accEmergencyStop 0 "Ok" 1 "ERR" ;
VAL_ 130 SensorR_E4_velEmergencyStop 0 "Ok" 1 "ERR" ;
VAL_ 130 SensorR_E3_posEmergencyStop 0 "Ok" 1 "ERR" ;
VAL_ 130 SensorR_E2_stripeEmergencyStop 0 "Ok" 1 "ERR" ;
VAL_ 130 SensorR_E1_trajectoryError 0 "Ok" 1 "ERR" ;
VAL_ 130 SensorR_E0_OtherError 0 "Ok" 1 "ERR" ;
VAL_ 130 SensorR_W10_highLIMTemperature 0 "Ok" 1 "WARN" ;
VAL_ 130 SensorR_W9_restrictingVelocity 0 "Ok" 1 "WARN" ;
VAL_ 130 SensorR_W8_outOfLimModelBoundari 0 "Ok" 1 "WARN" ;
VAL_ 130 SensorR_W7_highOscillations 0 "Ok" 1 "WARN" ;
VAL_ 130 SensorR_W6_sciMoPEwarning104FETt 0 "Ok" 1 "WARN" ;
VAL_ 130 SensorR_W5_sciMoPEwarning069CPUt 0 "Ok" 1 "WARN" ;
VAL_ 130 SensorR_W4_stateEstimationAccWar 0 "Ok" 1 "WARN" ;
VAL_ 130 SensorR_W3_stateEstimationPosWar 0 "Ok" 1 "WARN" ;
VAL_ 130 SensorR_W2_stateEstimationVelWar 0 "Ok" 1 "WARN" ;
VAL_ 130 SensorR_W1_stripeWarning 0 "Ok" 1 "WARN" ;
VAL_ 130 SensorR_W0_OtherWarning 0 "Ok" 1 "WARN" ;
VAL_ 514 SensorR_TX_ErrorFlag 1 "Error" 0 "No Error" ;
VAL_ 514 SensorR_TX_Enabled 1 "Enabled" 0 "Disabled" ;
VAL_ 514 SensorR_TX_TrajectorySet 2 "Invalid set" 1 "Set" 0 "Not set" ;
VAL_ 514 SensorR_TX_RunState 4 "Idle not ready" 3 "Launch Abort" 2 "Finished" 1 "Ready to Launch" 0 "Launching" ;
VAL_ 706 SensorR_RX_ErrorReset 1 "Reset" 0 "No Reset" ;
VAL_ 706 SensorR_RX_Enable 1 "Enable" 0 "Disable" ;
VAL_ 706 SensorR_RX_LaunchComm 2 "No Start" 1 "Abort Launch" 0 "Start Launch" ;
